[part 2 of 2: packages /ComponentTypes to /Nexteer/DataTypes]
AUTOSAR XML (schema 4.0)
package /ComponentTypes  (continued)
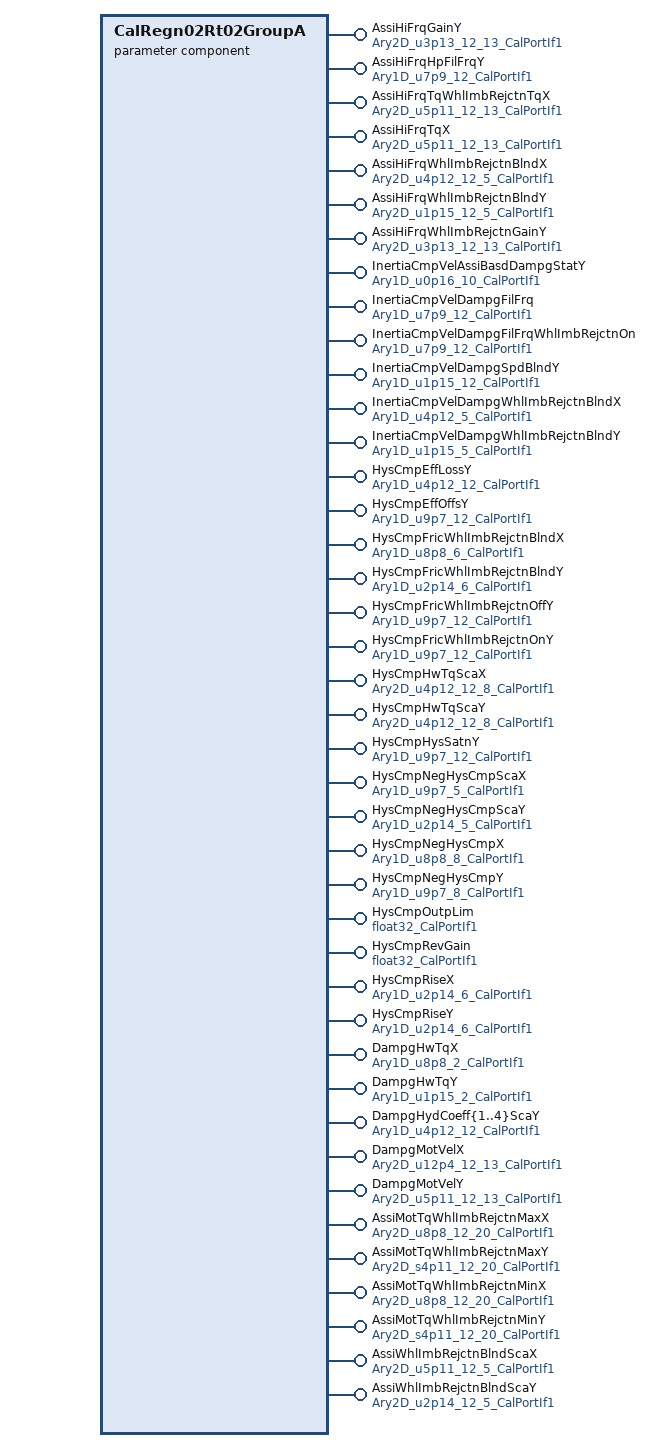
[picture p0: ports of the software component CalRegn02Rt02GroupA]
  parameter sw component type CalRegn02Rt02GroupA
    44 x provide port:
      AssiHiFrqGainY: parameter-provide-com-spec{init-value=12 x [2048, 1638, 1065, 655, 328, 82, 0, 0, 0, 0, 0, 0, 0], parameter=Ary2D_u3p13_12_13_CalPortIf1/Ary2D}, provided-interface=Ary2D_u3p13_12_13_CalPortIf1
      AssiHiFrqHpFilFrqY: parameter-provide-com-spec{init-value=12 x 4096, parameter=Ary1D_u7p9_12_CalPortIf1/Ary1D}, provided-interface=Ary1D_u7p9_12_CalPortIf1
      AssiHiFrqTqWhlImbRejctnTqX: parameter-provide-com-spec{init-value=12 x [0, 512, 1024, 1536, 2048, 2560, 3072, 4096, 8192, 12288, 15360, 15872, 16384], parameter=Ary2D_u5p11_12_13_CalPortIf1/Ary2D}, provided-interface=Ary2D_u5p11_12_13_CalPortIf1
      AssiHiFrqTqX: parameter-provide-com-spec{init-value=12 x [0, 512, 1024, 1536, 2048, 2560, 3072, 4096, 8192, 12288, 15360, 15872, 16384], parameter=Ary2D_u5p11_12_13_CalPortIf1/Ary2D}, provided-interface=Ary2D_u5p11_12_13_CalPortIf1
      AssiHiFrqWhlImbRejctnBlndX: parameter-provide-com-spec{init-value=12 x [0, 1024, 2048, 3072, 4506], parameter=Ary2D_u4p12_12_5_CalPortIf1/Ary2D}, provided-interface=Ary2D_u4p12_12_5_CalPortIf1
      AssiHiFrqWhlImbRejctnBlndY: parameter-provide-com-spec{init-value=12 x 5 x 0, parameter=Ary2D_u1p15_12_5_CalPortIf1/Ary2D}, provided-interface=Ary2D_u1p15_12_5_CalPortIf1
      AssiHiFrqWhlImbRejctnGainY: parameter-provide-com-spec{init-value=12 x [2048, 1638, 1065, 655, 328, 82, 0, 0, 0, 0, 0, 0, 0], parameter=Ary2D_u3p13_12_13_CalPortIf1/Ary2D}, provided-interface=Ary2D_u3p13_12_13_CalPortIf1
      InertiaCmpVelAssiBasdDampgStatY: parameter-provide-com-spec{init-value=10 x 0, parameter=Ary1D_u0p16_10_CalPortIf1/Ary1D}, provided-interface=Ary1D_u0p16_10_CalPortIf1
      InertiaCmpVelDampgFilFrq: parameter-provide-com-spec{init-value=12 x 8192, parameter=Ary1D_u7p9_12_CalPortIf1/Ary1D}, provided-interface=Ary1D_u7p9_12_CalPortIf1
      InertiaCmpVelDampgFilFrqWhlImbRejctnOn: parameter-provide-com-spec{init-value=12 x 8192, parameter=Ary1D_u7p9_12_CalPortIf1/Ary1D}, provided-interface=Ary1D_u7p9_12_CalPortIf1
      InertiaCmpVelDampgSpdBlndY: parameter-provide-com-spec{init-value=[32768, 32768, 9830, 6554, 3277, 0, 0, 0, 0, 0, 0, 0], parameter=Ary1D_u1p15_12_CalPortIf1/Ary1D}, provided-interface=Ary1D_u1p15_12_CalPortIf1
      InertiaCmpVelDampgWhlImbRejctnBlndX: parameter-provide-com-spec{init-value=[208, 432, 640, 848, 1056], parameter=Ary1D_u4p12_5_CalPortIf1/Ary1D}, provided-interface=Ary1D_u4p12_5_CalPortIf1
      InertiaCmpVelDampgWhlImbRejctnBlndY: parameter-provide-com-spec{init-value=5 x 0, parameter=Ary1D_u1p15_5_CalPortIf1/Ary1D}, provided-interface=Ary1D_u1p15_5_CalPortIf1
      HysCmpEffLossY: parameter-provide-com-spec{init-value=12 x 0, parameter=Ary1D_u4p12_12_CalPortIf1/Ary1D}, provided-interface=Ary1D_u4p12_12_CalPortIf1
      HysCmpEffOffsY: parameter-provide-com-spec{init-value=12 x 0, parameter=Ary1D_u9p7_12_CalPortIf1/Ary1D}, provided-interface=Ary1D_u9p7_12_CalPortIf1
      HysCmpFricWhlImbRejctnBlndX: parameter-provide-com-spec{init-value=[0, 51, 102, 154, 205, 256], parameter=Ary1D_u8p8_6_CalPortIf1/Ary1D}, provided-interface=Ary1D_u8p8_6_CalPortIf1
      HysCmpFricWhlImbRejctnBlndY: parameter-provide-com-spec{init-value=6 x 0, parameter=Ary1D_u2p14_6_CalPortIf1/Ary1D}, provided-interface=Ary1D_u2p14_6_CalPortIf1
      HysCmpFricWhlImbRejctnOffY: parameter-provide-com-spec{init-value=12 x 0, parameter=Ary1D_u9p7_12_CalPortIf1/Ary1D}, provided-interface=Ary1D_u9p7_12_CalPortIf1
      HysCmpFricWhlImbRejctnOnY: parameter-provide-com-spec{init-value=12 x 0, parameter=Ary1D_u9p7_12_CalPortIf1/Ary1D}, provided-interface=Ary1D_u9p7_12_CalPortIf1
      HysCmpHwTqScaX: parameter-provide-com-spec{init-value=12 x [0, 815, 1634, 2458, 4096, 5730, 8192, 40960], parameter=Ary2D_u4p12_12_8_CalPortIf1/Ary2D}, provided-interface=Ary2D_u4p12_12_8_CalPortIf1
      HysCmpHwTqScaY: parameter-provide-com-spec{init-value=12 x 8 x 4096, parameter=Ary2D_u4p12_12_8_CalPortIf1/Ary2D}, provided-interface=Ary2D_u4p12_12_8_CalPortIf1
      HysCmpHysSatnY: parameter-provide-com-spec{init-value=12 x 1280, parameter=Ary1D_u9p7_12_CalPortIf1/Ary1D}, provided-interface=Ary1D_u9p7_12_CalPortIf1
      HysCmpNegHysCmpScaX: parameter-provide-com-spec{init-value=[0, 128, 256, 384, 512], parameter=Ary1D_u9p7_5_CalPortIf1/Ary1D}, provided-interface=Ary1D_u9p7_5_CalPortIf1
      HysCmpNegHysCmpScaY: parameter-provide-com-spec{init-value=5 x 16384, parameter=Ary1D_u2p14_5_CalPortIf1/Ary1D}, provided-interface=Ary1D_u2p14_5_CalPortIf1
      HysCmpNegHysCmpX: parameter-provide-com-spec{init-value=[0, 26, 51, 102, 154, 205, 230, 256], parameter=Ary1D_u8p8_8_CalPortIf1/Ary1D}, provided-interface=Ary1D_u8p8_8_CalPortIf1
      HysCmpNegHysCmpY: parameter-provide-com-spec{init-value=8 x 0, parameter=Ary1D_u9p7_8_CalPortIf1/Ary1D}, provided-interface=Ary1D_u9p7_8_CalPortIf1
      HysCmpOutpLim: parameter-provide-com-spec{init-value=16, parameter=float32_CalPortIf1/Val}, provided-interface=float32_CalPortIf1
      HysCmpRevGain: parameter-provide-com-spec{init-value=6, parameter=float32_CalPortIf1/Val}, provided-interface=float32_CalPortIf1
      HysCmpRiseX: parameter-provide-com-spec{init-value=[0, 1556, 2097, 2540, 2982, 3277], parameter=Ary1D_u2p14_6_CalPortIf1/Ary1D}, provided-interface=Ary1D_u2p14_6_CalPortIf1
      HysCmpRiseY: parameter-provide-com-spec{init-value=[0, 9863, 12878, 14811, 15974, 16384], parameter=Ary1D_u2p14_6_CalPortIf1/Ary1D}, provided-interface=Ary1D_u2p14_6_CalPortIf1
      DampgHwTqX: parameter-provide-com-spec{init-value=[2048, 2560], parameter=Ary1D_u8p8_2_CalPortIf1/Ary1D}, provided-interface=Ary1D_u8p8_2_CalPortIf1
      DampgHwTqY: parameter-provide-com-spec{init-value=[32768, 0], parameter=Ary1D_u1p15_2_CalPortIf1/Ary1D}, provided-interface=Ary1D_u1p15_2_CalPortIf1
      DampgHydCoeff{1..4}ScaY: parameter-provide-com-spec{init-value=12 x 4096, parameter=Ary1D_u4p12_12_CalPortIf1/Ary1D}, provided-interface=Ary1D_u4p12_12_CalPortIf1
      DampgMotVelX: parameter-provide-com-spec{init-value=12 x [33, 163, 342, 554, 872, 1260, 1663, 2032, 2401, 2771, 3509, 4433, 5910], parameter=Ary2D_u12p4_12_13_CalPortIf1/Ary2D}, provided-interface=Ary2D_u12p4_12_13_CalPortIf1
      DampgMotVelY: parameter-provide-com-spec{init-value=[13 x 0, 13 x 0, 13 x 0, 13 x 0, [0, 0, 1, 3, 7, 14, 24, 36, 50, 67, 107, 171, 304], [1, 5, 13, 25, 48, 85, 132, 184, 245, 313, 476, 725, 1233], [5, 25, 54, 93, 159, 251, 360, 472, 597, 733, 1041, 1493, 2370], [10, 49, 106, 180, 301, 467, 659, 855, 1068, 1299, 1814, 2559, 3981], [10, 49, 106, 180, 301, 467, 659, 855, 1068, 1299, 1814, 2559, 3981], [10, 49, 106, 180, 301, 467, 659, 855, 1068, 1299, 1814, 2559, 3981], [10, 49, 106, 180, 301, 467, 659, 855, 1068, 1299, 1814, 2559, 3981], [10, 49, 106, 180, 301, 467, 659, 855, 1068, 1299, 1814, 2559, 3981]], parameter=Ary2D_u5p11_12_13_CalPortIf1/Ary2D}, provided-interface=Ary2D_u5p11_12_13_CalPortIf1
      AssiMotTqWhlImbRejctnMaxX: parameter-provide-com-spec{init-value=[[0, 26, 53, 63, 74, 86, 98, 110, 123, 134, 146, 159, 170, 182, 194, 205, 256, 372, 1220, 2560], [0, 26, 78, 101, 123, 148, 171, 196, 220, 243, 267, 290, 315, 339, 362, 435, 563, 719, 1624, 2560], [0, 51, 80, 113, 145, 176, 205, 238, 266, 297, 330, 360, 391, 422, 452, 538, 717, 916, 2216, 2560], [0, 51, 80, 110, 146, 173, 205, 237, 266, 299, 330, 360, 392, 423, 452, 484, 640, 917, 947, 2560], [0, 51, 80, 111, 143, 177, 207, 238, 267, 300, 330, 359, 392, 422, 453, 483, 640, 819, 947, 2560], [0, 51, 79, 111, 139, 174, 206, 236, 267, 300, 334, 366, 396, 428, 460, 494, 640, 819, 972, 2560], [0, 51, 80, 106, 142, 175, 205, 239, 270, 300, 332, 366, 398, 429, 462, 494, 640, 819, 972, 2560], [0, 51, 100, 130, 163, 194, 229, 261, 291, 324, 355, 388, 420, 451, 483, 515, 640, 819, 998, 2560], [0, 51, 100, 130, 164, 196, 232, 260, 297, 327, 360, 396, 430, 462, 493, 527, 666, 819, 1024, 2560], [0, 51, 100, 130, 164, 196, 232, 260, 297, 327, 360, 396, 430, 462, 493, 527, 666, 819, 1024, 2560], [0, 51, 100, 130, 164, 196, 232, 260, 297, 327, 360, 396, 430, 462, 493, 527, 666, 819, 1024, 2560], [0, 51, 100, 130, 164, 196, 232, 260, 297, 327, 360, 396, 430, 462, 493, 527, 666, 819, 1024, 2560]], parameter=Ary2D_u8p8_12_20_CalPortIf1/Ary2D}, provided-interface=Ary2D_u8p8_12_20_CalPortIf1
      AssiMotTqWhlImbRejctnMaxY: parameter-provide-com-spec{init-value=[[0, 0, 48, 72, 104, 144, 192, 248, 312, 376, 448, 536, 616, 712, 816, 920, 1536, 3128, 17904, 17904], [0, 0, 64, 104, 152, 216, 288, 376, 472, 576, 696, 824, 968, 1120, 1280, 1761, 3072, 5120, 17904, 17904], [0, 0, 32, 80, 136, 200, 272, 360, 448, 552, 672, 792, 928, 1072, 1224, 1741, 3031, 4728, 17904, 17904], [0, 0, 32, 72, 128, 176, 240, 312, 384, 472, 560, 656, 760, 872, 984, 1112, 2048, 3568, 3792, 15632], [0, 0, 32, 72, 120, 176, 232, 296, 360, 440, 520, 600, 696, 792, 896, 1000, 1741, 2642, 3320, 13472], [0, 0, 32, 72, 112, 168, 224, 280, 344, 416, 496, 576, 656, 744, 840, 944, 1536, 2314, 3024, 11632], [0, 0, 32, 64, 112, 160, 208, 264, 320, 376, 440, 512, 584, 656, 736, 816, 1311, 1925, 2456, 9120], [0, 0, 48, 80, 120, 160, 208, 256, 304, 360, 416, 480, 544, 608, 680, 752, 1126, 1720, 2264, 8272], [0, 0, 48, 80, 120, 160, 208, 248, 304, 352, 408, 472, 536, 600, 664, 736, 1024, 1536, 2160, 7528], [0, 0, 48, 80, 120, 160, 208, 248, 304, 352, 408, 472, 536, 600, 664, 736, 1024, 1536, 2160, 7528], [0, 0, 48, 80, 120, 160, 208, 248, 304, 352, 408, 472, 536, 600, 664, 736, 1024, 1536, 2160, 7528], [0, 0, 48, 80, 120, 160, 208, 248, 304, 352, 408, 472, 536, 600, 664, 736, 1024, 1536, 2160, 7528]], parameter=Ary2D_s4p11_12_20_CalPortIf1/Ary2D}, provided-interface=Ary2D_s4p11_12_20_CalPortIf1
      AssiMotTqWhlImbRejctnMinX: parameter-provide-com-spec{init-value=[[0, 26, 53, 63, 74, 86, 98, 110, 123, 134, 146, 159, 170, 182, 194, 205, 256, 372, 1220, 2560], [0, 26, 78, 101, 123, 148, 171, 196, 220, 243, 267, 290, 315, 339, 362, 435, 563, 719, 1624, 2560], [0, 51, 80, 113, 145, 176, 205, 238, 266, 297, 330, 360, 391, 422, 452, 538, 717, 916, 2216, 2560], [0, 51, 80, 110, 146, 173, 205, 237, 266, 299, 330, 360, 392, 423, 452, 484, 640, 917, 947, 2560], [0, 51, 80, 111, 143, 177, 207, 238, 267, 300, 330, 359, 392, 422, 453, 483, 640, 819, 947, 2560], [0, 51, 79, 111, 139, 174, 206, 236, 267, 300, 334, 366, 396, 428, 460, 494, 640, 819, 972, 2560], [0, 51, 80, 106, 142, 175, 205, 239, 270, 300, 332, 366, 398, 429, 462, 494, 640, 819, 972, 2560], [0, 51, 100, 130, 163, 194, 229, 261, 291, 324, 355, 388, 420, 451, 483, 515, 640, 819, 998, 2560], [0, 51, 100, 130, 164, 196, 232, 260, 297, 327, 360, 396, 430, 462, 493, 527, 666, 819, 1024, 2560], [0, 51, 100, 130, 164, 196, 232, 260, 297, 327, 360, 396, 430, 462, 493, 527, 666, 819, 1024, 2560], [0, 51, 100, 130, 164, 196, 232, 260, 297, 327, 360, 396, 430, 462, 493, 527, 666, 819, 1024, 2560], [0, 51, 100, 130, 164, 196, 232, 260, 297, 327, 360, 396, 430, 462, 493, 527, 666, 819, 1024, 2560]], parameter=Ary2D_u8p8_12_20_CalPortIf1/Ary2D}, provided-interface=Ary2D_u8p8_12_20_CalPortIf1
      AssiMotTqWhlImbRejctnMinY: parameter-provide-com-spec{init-value=[[0, 0, 48, 72, 104, 144, 192, 248, 312, 376, 448, 536, 616, 712, 816, 920, 1536, 3128, 17904, 17904], [0, 0, 64, 104, 152, 216, 288, 376, 472, 576, 696, 824, 968, 1120, 1280, 1761, 3072, 5120, 17904, 17904], [0, 0, 32, 80, 136, 200, 272, 360, 448, 552, 672, 792, 928, 1072, 1224, 1741, 3031, 4728, 17904, 17904], [0, 0, 32, 72, 128, 176, 240, 312, 384, 472, 560, 656, 760, 872, 984, 1112, 2048, 3568, 3792, 15632], [0, 0, 32, 72, 120, 176, 232, 296, 360, 440, 520, 600, 696, 792, 896, 1000, 1741, 2642, 3320, 13472], [0, 0, 32, 72, 112, 168, 224, 280, 344, 416, 496, 576, 656, 744, 840, 944, 1536, 2314, 3024, 11632], [0, 0, 32, 64, 112, 160, 208, 264, 320, 376, 440, 512, 584, 656, 736, 816, 1311, 1925, 2456, 9120], [0, 0, 48, 80, 120, 160, 208, 256, 304, 360, 416, 480, 544, 608, 680, 752, 1126, 1720, 2264, 8272], [0, 0, 48, 80, 120, 160, 208, 248, 304, 352, 408, 472, 536, 600, 664, 736, 1024, 1536, 2160, 7528], [0, 0, 48, 80, 120, 160, 208, 248, 304, 352, 408, 472, 536, 600, 664, 736, 1024, 1536, 2160, 7528], [0, 0, 48, 80, 120, 160, 208, 248, 304, 352, 408, 472, 536, 600, 664, 736, 1024, 1536, 2160, 7528], [0, 0, 48, 80, 120, 160, 208, 248, 304, 352, 408, 472, 536, 600, 664, 736, 1024, 1536, 2160, 7528]], parameter=Ary2D_s4p11_12_20_CalPortIf1/Ary2D}, provided-interface=Ary2D_s4p11_12_20_CalPortIf1
      AssiWhlImbRejctnBlndScaX: parameter-provide-com-spec{init-value=12 x [0, 512, 1024, 1536, 2253], parameter=Ary2D_u5p11_12_5_CalPortIf1/Ary2D}, provided-interface=Ary2D_u5p11_12_5_CalPortIf1
      AssiWhlImbRejctnBlndScaY: parameter-provide-com-spec{init-value=12 x 5 x 0, parameter=Ary2D_u2p14_12_5_CalPortIf1/Ary2D}, provided-interface=Ary2D_u2p14_12_5_CalPortIf1
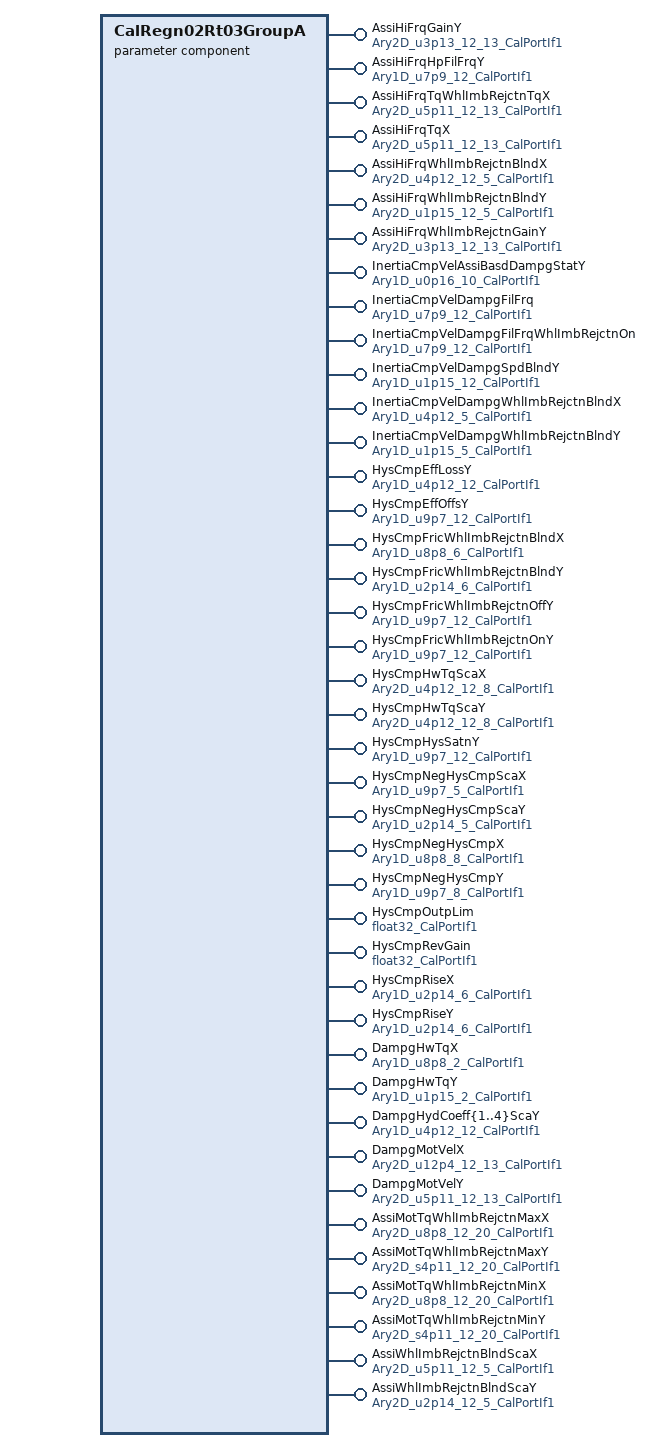
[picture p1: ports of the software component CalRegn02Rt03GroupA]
  parameter sw component type CalRegn02Rt03GroupA
    44 x provide port:
      AssiHiFrqGainY: parameter-provide-com-spec{init-value=12 x [2048, 1638, 1065, 655, 328, 82, 0, 0, 0, 0, 0, 0, 0], parameter=Ary2D_u3p13_12_13_CalPortIf1/Ary2D}, provided-interface=Ary2D_u3p13_12_13_CalPortIf1
      AssiHiFrqHpFilFrqY: parameter-provide-com-spec{init-value=12 x 4096, parameter=Ary1D_u7p9_12_CalPortIf1/Ary1D}, provided-interface=Ary1D_u7p9_12_CalPortIf1
      AssiHiFrqTqWhlImbRejctnTqX: parameter-provide-com-spec{init-value=12 x [0, 512, 1024, 1536, 2048, 2560, 3072, 4096, 8192, 12288, 15360, 15872, 16384], parameter=Ary2D_u5p11_12_13_CalPortIf1/Ary2D}, provided-interface=Ary2D_u5p11_12_13_CalPortIf1
      AssiHiFrqTqX: parameter-provide-com-spec{init-value=12 x [0, 512, 1024, 1536, 2048, 2560, 3072, 4096, 8192, 12288, 15360, 15872, 16384], parameter=Ary2D_u5p11_12_13_CalPortIf1/Ary2D}, provided-interface=Ary2D_u5p11_12_13_CalPortIf1
      AssiHiFrqWhlImbRejctnBlndX: parameter-provide-com-spec{init-value=12 x [0, 1024, 2048, 3072, 4506], parameter=Ary2D_u4p12_12_5_CalPortIf1/Ary2D}, provided-interface=Ary2D_u4p12_12_5_CalPortIf1
      AssiHiFrqWhlImbRejctnBlndY: parameter-provide-com-spec{init-value=12 x 5 x 0, parameter=Ary2D_u1p15_12_5_CalPortIf1/Ary2D}, provided-interface=Ary2D_u1p15_12_5_CalPortIf1
      AssiHiFrqWhlImbRejctnGainY: parameter-provide-com-spec{init-value=12 x [2048, 1638, 1065, 655, 328, 82, 0, 0, 0, 0, 0, 0, 0], parameter=Ary2D_u3p13_12_13_CalPortIf1/Ary2D}, provided-interface=Ary2D_u3p13_12_13_CalPortIf1
      InertiaCmpVelAssiBasdDampgStatY: parameter-provide-com-spec{init-value=10 x 0, parameter=Ary1D_u0p16_10_CalPortIf1/Ary1D}, provided-interface=Ary1D_u0p16_10_CalPortIf1
      InertiaCmpVelDampgFilFrq: parameter-provide-com-spec{init-value=12 x 8192, parameter=Ary1D_u7p9_12_CalPortIf1/Ary1D}, provided-interface=Ary1D_u7p9_12_CalPortIf1
      InertiaCmpVelDampgFilFrqWhlImbRejctnOn: parameter-provide-com-spec{init-value=12 x 8192, parameter=Ary1D_u7p9_12_CalPortIf1/Ary1D}, provided-interface=Ary1D_u7p9_12_CalPortIf1
      InertiaCmpVelDampgSpdBlndY: parameter-provide-com-spec{init-value=[32768, 32768, 9830, 6554, 3277, 0, 0, 0, 0, 0, 0, 0], parameter=Ary1D_u1p15_12_CalPortIf1/Ary1D}, provided-interface=Ary1D_u1p15_12_CalPortIf1
      InertiaCmpVelDampgWhlImbRejctnBlndX: parameter-provide-com-spec{init-value=[208, 432, 640, 848, 1056], parameter=Ary1D_u4p12_5_CalPortIf1/Ary1D}, provided-interface=Ary1D_u4p12_5_CalPortIf1
      InertiaCmpVelDampgWhlImbRejctnBlndY: parameter-provide-com-spec{init-value=5 x 0, parameter=Ary1D_u1p15_5_CalPortIf1/Ary1D}, provided-interface=Ary1D_u1p15_5_CalPortIf1
      HysCmpEffLossY: parameter-provide-com-spec{init-value=12 x 0, parameter=Ary1D_u4p12_12_CalPortIf1/Ary1D}, provided-interface=Ary1D_u4p12_12_CalPortIf1
      HysCmpEffOffsY: parameter-provide-com-spec{init-value=12 x 0, parameter=Ary1D_u9p7_12_CalPortIf1/Ary1D}, provided-interface=Ary1D_u9p7_12_CalPortIf1
      HysCmpFricWhlImbRejctnBlndX: parameter-provide-com-spec{init-value=[0, 51, 102, 154, 205, 256], parameter=Ary1D_u8p8_6_CalPortIf1/Ary1D}, provided-interface=Ary1D_u8p8_6_CalPortIf1
      HysCmpFricWhlImbRejctnBlndY: parameter-provide-com-spec{init-value=6 x 0, parameter=Ary1D_u2p14_6_CalPortIf1/Ary1D}, provided-interface=Ary1D_u2p14_6_CalPortIf1
      HysCmpFricWhlImbRejctnOffY: parameter-provide-com-spec{init-value=12 x 0, parameter=Ary1D_u9p7_12_CalPortIf1/Ary1D}, provided-interface=Ary1D_u9p7_12_CalPortIf1
      HysCmpFricWhlImbRejctnOnY: parameter-provide-com-spec{init-value=12 x 0, parameter=Ary1D_u9p7_12_CalPortIf1/Ary1D}, provided-interface=Ary1D_u9p7_12_CalPortIf1
      HysCmpHwTqScaX: parameter-provide-com-spec{init-value=12 x [0, 815, 1634, 2458, 4096, 5730, 8192, 40960], parameter=Ary2D_u4p12_12_8_CalPortIf1/Ary2D}, provided-interface=Ary2D_u4p12_12_8_CalPortIf1
      HysCmpHwTqScaY: parameter-provide-com-spec{init-value=12 x 8 x 4096, parameter=Ary2D_u4p12_12_8_CalPortIf1/Ary2D}, provided-interface=Ary2D_u4p12_12_8_CalPortIf1
      HysCmpHysSatnY: parameter-provide-com-spec{init-value=12 x 1280, parameter=Ary1D_u9p7_12_CalPortIf1/Ary1D}, provided-interface=Ary1D_u9p7_12_CalPortIf1
      HysCmpNegHysCmpScaX: parameter-provide-com-spec{init-value=[0, 128, 256, 384, 512], parameter=Ary1D_u9p7_5_CalPortIf1/Ary1D}, provided-interface=Ary1D_u9p7_5_CalPortIf1
      HysCmpNegHysCmpScaY: parameter-provide-com-spec{init-value=5 x 16384, parameter=Ary1D_u2p14_5_CalPortIf1/Ary1D}, provided-interface=Ary1D_u2p14_5_CalPortIf1
      HysCmpNegHysCmpX: parameter-provide-com-spec{init-value=[0, 26, 51, 102, 154, 205, 230, 256], parameter=Ary1D_u8p8_8_CalPortIf1/Ary1D}, provided-interface=Ary1D_u8p8_8_CalPortIf1
      HysCmpNegHysCmpY: parameter-provide-com-spec{init-value=8 x 0, parameter=Ary1D_u9p7_8_CalPortIf1/Ary1D}, provided-interface=Ary1D_u9p7_8_CalPortIf1
      HysCmpOutpLim: parameter-provide-com-spec{init-value=16, parameter=float32_CalPortIf1/Val}, provided-interface=float32_CalPortIf1
      HysCmpRevGain: parameter-provide-com-spec{init-value=6, parameter=float32_CalPortIf1/Val}, provided-interface=float32_CalPortIf1
      HysCmpRiseX: parameter-provide-com-spec{init-value=[0, 1556, 2097, 2540, 2982, 3277], parameter=Ary1D_u2p14_6_CalPortIf1/Ary1D}, provided-interface=Ary1D_u2p14_6_CalPortIf1
      HysCmpRiseY: parameter-provide-com-spec{init-value=[0, 9863, 12878, 14811, 15974, 16384], parameter=Ary1D_u2p14_6_CalPortIf1/Ary1D}, provided-interface=Ary1D_u2p14_6_CalPortIf1
      DampgHwTqX: parameter-provide-com-spec{init-value=[2048, 2560], parameter=Ary1D_u8p8_2_CalPortIf1/Ary1D}, provided-interface=Ary1D_u8p8_2_CalPortIf1
      DampgHwTqY: parameter-provide-com-spec{init-value=[32768, 0], parameter=Ary1D_u1p15_2_CalPortIf1/Ary1D}, provided-interface=Ary1D_u1p15_2_CalPortIf1
      DampgHydCoeff{1..4}ScaY: parameter-provide-com-spec{init-value=12 x 4096, parameter=Ary1D_u4p12_12_CalPortIf1/Ary1D}, provided-interface=Ary1D_u4p12_12_CalPortIf1
      DampgMotVelX: parameter-provide-com-spec{init-value=12 x [33, 163, 342, 554, 872, 1260, 1663, 2032, 2401, 2771, 3509, 4433, 5910], parameter=Ary2D_u12p4_12_13_CalPortIf1/Ary2D}, provided-interface=Ary2D_u12p4_12_13_CalPortIf1
      DampgMotVelY: parameter-provide-com-spec{init-value=[13 x 0, 13 x 0, 13 x 0, 13 x 0, [0, 0, 1, 3, 7, 14, 24, 36, 50, 67, 107, 171, 304], [1, 5, 13, 25, 48, 85, 132, 184, 245, 313, 476, 725, 1233], [5, 25, 54, 93, 159, 251, 360, 472, 597, 733, 1041, 1493, 2370], [10, 49, 106, 180, 301, 467, 659, 855, 1068, 1299, 1814, 2559, 3981], [10, 49, 106, 180, 301, 467, 659, 855, 1068, 1299, 1814, 2559, 3981], [10, 49, 106, 180, 301, 467, 659, 855, 1068, 1299, 1814, 2559, 3981], [10, 49, 106, 180, 301, 467, 659, 855, 1068, 1299, 1814, 2559, 3981], [10, 49, 106, 180, 301, 467, 659, 855, 1068, 1299, 1814, 2559, 3981]], parameter=Ary2D_u5p11_12_13_CalPortIf1/Ary2D}, provided-interface=Ary2D_u5p11_12_13_CalPortIf1
      AssiMotTqWhlImbRejctnMaxX: parameter-provide-com-spec{init-value=[[0, 26, 53, 63, 74, 86, 98, 110, 123, 134, 146, 159, 170, 182, 194, 205, 256, 372, 1220, 2560], [0, 26, 78, 101, 123, 148, 171, 196, 220, 243, 267, 290, 315, 339, 362, 435, 563, 719, 1624, 2560], [0, 51, 80, 113, 145, 176, 205, 238, 266, 297, 330, 360, 391, 422, 452, 538, 717, 916, 2216, 2560], [0, 51, 80, 110, 146, 173, 205, 237, 266, 299, 330, 360, 392, 423, 452, 484, 640, 917, 947, 2560], [0, 51, 80, 111, 143, 177, 207, 238, 267, 300, 330, 359, 392, 422, 453, 483, 640, 819, 947, 2560], [0, 51, 79, 111, 139, 174, 206, 236, 267, 300, 334, 366, 396, 428, 460, 494, 640, 819, 972, 2560], [0, 51, 80, 106, 142, 175, 205, 239, 270, 300, 332, 366, 398, 429, 462, 494, 640, 819, 972, 2560], [0, 51, 100, 130, 163, 194, 229, 261, 291, 324, 355, 388, 420, 451, 483, 515, 640, 819, 998, 2560], [0, 51, 100, 130, 164, 196, 232, 260, 297, 327, 360, 396, 430, 462, 493, 527, 666, 819, 1024, 2560], [0, 51, 100, 130, 164, 196, 232, 260, 297, 327, 360, 396, 430, 462, 493, 527, 666, 819, 1024, 2560], [0, 51, 100, 130, 164, 196, 232, 260, 297, 327, 360, 396, 430, 462, 493, 527, 666, 819, 1024, 2560], [0, 51, 100, 130, 164, 196, 232, 260, 297, 327, 360, 396, 430, 462, 493, 527, 666, 819, 1024, 2560]], parameter=Ary2D_u8p8_12_20_CalPortIf1/Ary2D}, provided-interface=Ary2D_u8p8_12_20_CalPortIf1
      AssiMotTqWhlImbRejctnMaxY: parameter-provide-com-spec{init-value=[[0, 0, 48, 72, 104, 144, 192, 248, 312, 376, 448, 536, 616, 712, 816, 920, 1536, 3128, 17904, 17904], [0, 0, 64, 104, 152, 216, 288, 376, 472, 576, 696, 824, 968, 1120, 1280, 1761, 3072, 5120, 17904, 17904], [0, 0, 32, 80, 136, 200, 272, 360, 448, 552, 672, 792, 928, 1072, 1224, 1741, 3031, 4728, 17904, 17904], [0, 0, 32, 72, 128, 176, 240, 312, 384, 472, 560, 656, 760, 872, 984, 1112, 2048, 3568, 3792, 15632], [0, 0, 32, 72, 120, 176, 232, 296, 360, 440, 520, 600, 696, 792, 896, 1000, 1741, 2642, 3320, 13472], [0, 0, 32, 72, 112, 168, 224, 280, 344, 416, 496, 576, 656, 744, 840, 944, 1536, 2314, 3024, 11632], [0, 0, 32, 64, 112, 160, 208, 264, 320, 376, 440, 512, 584, 656, 736, 816, 1311, 1925, 2456, 9120], [0, 0, 48, 80, 120, 160, 208, 256, 304, 360, 416, 480, 544, 608, 680, 752, 1126, 1720, 2264, 8272], [0, 0, 48, 80, 120, 160, 208, 248, 304, 352, 408, 472, 536, 600, 664, 736, 1024, 1536, 2160, 7528], [0, 0, 48, 80, 120, 160, 208, 248, 304, 352, 408, 472, 536, 600, 664, 736, 1024, 1536, 2160, 7528], [0, 0, 48, 80, 120, 160, 208, 248, 304, 352, 408, 472, 536, 600, 664, 736, 1024, 1536, 2160, 7528], [0, 0, 48, 80, 120, 160, 208, 248, 304, 352, 408, 472, 536, 600, 664, 736, 1024, 1536, 2160, 7528]], parameter=Ary2D_s4p11_12_20_CalPortIf1/Ary2D}, provided-interface=Ary2D_s4p11_12_20_CalPortIf1
      AssiMotTqWhlImbRejctnMinX: parameter-provide-com-spec{init-value=[[0, 26, 53, 63, 74, 86, 98, 110, 123, 134, 146, 159, 170, 182, 194, 205, 256, 372, 1220, 2560], [0, 26, 78, 101, 123, 148, 171, 196, 220, 243, 267, 290, 315, 339, 362, 435, 563, 719, 1624, 2560], [0, 51, 80, 113, 145, 176, 205, 238, 266, 297, 330, 360, 391, 422, 452, 538, 717, 916, 2216, 2560], [0, 51, 80, 110, 146, 173, 205, 237, 266, 299, 330, 360, 392, 423, 452, 484, 640, 917, 947, 2560], [0, 51, 80, 111, 143, 177, 207, 238, 267, 300, 330, 359, 392, 422, 453, 483, 640, 819, 947, 2560], [0, 51, 79, 111, 139, 174, 206, 236, 267, 300, 334, 366, 396, 428, 460, 494, 640, 819, 972, 2560], [0, 51, 80, 106, 142, 175, 205, 239, 270, 300, 332, 366, 398, 429, 462, 494, 640, 819, 972, 2560], [0, 51, 100, 130, 163, 194, 229, 261, 291, 324, 355, 388, 420, 451, 483, 515, 640, 819, 998, 2560], [0, 51, 100, 130, 164, 196, 232, 260, 297, 327, 360, 396, 430, 462, 493, 527, 666, 819, 1024, 2560], [0, 51, 100, 130, 164, 196, 232, 260, 297, 327, 360, 396, 430, 462, 493, 527, 666, 819, 1024, 2560], [0, 51, 100, 130, 164, 196, 232, 260, 297, 327, 360, 396, 430, 462, 493, 527, 666, 819, 1024, 2560], [0, 51, 100, 130, 164, 196, 232, 260, 297, 327, 360, 396, 430, 462, 493, 527, 666, 819, 1024, 2560]], parameter=Ary2D_u8p8_12_20_CalPortIf1/Ary2D}, provided-interface=Ary2D_u8p8_12_20_CalPortIf1
      AssiMotTqWhlImbRejctnMinY: parameter-provide-com-spec{init-value=[[0, 0, 48, 72, 104, 144, 192, 248, 312, 376, 448, 536, 616, 712, 816, 920, 1536, 3128, 17904, 17904], [0, 0, 64, 104, 152, 216, 288, 376, 472, 576, 696, 824, 968, 1120, 1280, 1761, 3072, 5120, 17904, 17904], [0, 0, 32, 80, 136, 200, 272, 360, 448, 552, 672, 792, 928, 1072, 1224, 1741, 3031, 4728, 17904, 17904], [0, 0, 32, 72, 128, 176, 240, 312, 384, 472, 560, 656, 760, 872, 984, 1112, 2048, 3568, 3792, 15632], [0, 0, 32, 72, 120, 176, 232, 296, 360, 440, 520, 600, 696, 792, 896, 1000, 1741, 2642, 3320, 13472], [0, 0, 32, 72, 112, 168, 224, 280, 344, 416, 496, 576, 656, 744, 840, 944, 1536, 2314, 3024, 11632], [0, 0, 32, 64, 112, 160, 208, 264, 320, 376, 440, 512, 584, 656, 736, 816, 1311, 1925, 2456, 9120], [0, 0, 48, 80, 120, 160, 208, 256, 304, 360, 416, 480, 544, 608, 680, 752, 1126, 1720, 2264, 8272], [0, 0, 48, 80, 120, 160, 208, 248, 304, 352, 408, 472, 536, 600, 664, 736, 1024, 1536, 2160, 7528], [0, 0, 48, 80, 120, 160, 208, 248, 304, 352, 408, 472, 536, 600, 664, 736, 1024, 1536, 2160, 7528], [0, 0, 48, 80, 120, 160, 208, 248, 304, 352, 408, 472, 536, 600, 664, 736, 1024, 1536, 2160, 7528], [0, 0, 48, 80, 120, 160, 208, 248, 304, 352, 408, 472, 536, 600, 664, 736, 1024, 1536, 2160, 7528]], parameter=Ary2D_s4p11_12_20_CalPortIf1/Ary2D}, provided-interface=Ary2D_s4p11_12_20_CalPortIf1
      AssiWhlImbRejctnBlndScaX: parameter-provide-com-spec{init-value=12 x [0, 512, 1024, 1536, 2253], parameter=Ary2D_u5p11_12_5_CalPortIf1/Ary2D}, provided-interface=Ary2D_u5p11_12_5_CalPortIf1
      AssiWhlImbRejctnBlndScaY: parameter-provide-com-spec{init-value=12 x 5 x 0, parameter=Ary2D_u2p14_12_5_CalPortIf1/Ary2D}, provided-interface=Ary2D_u2p14_12_5_CalPortIf1
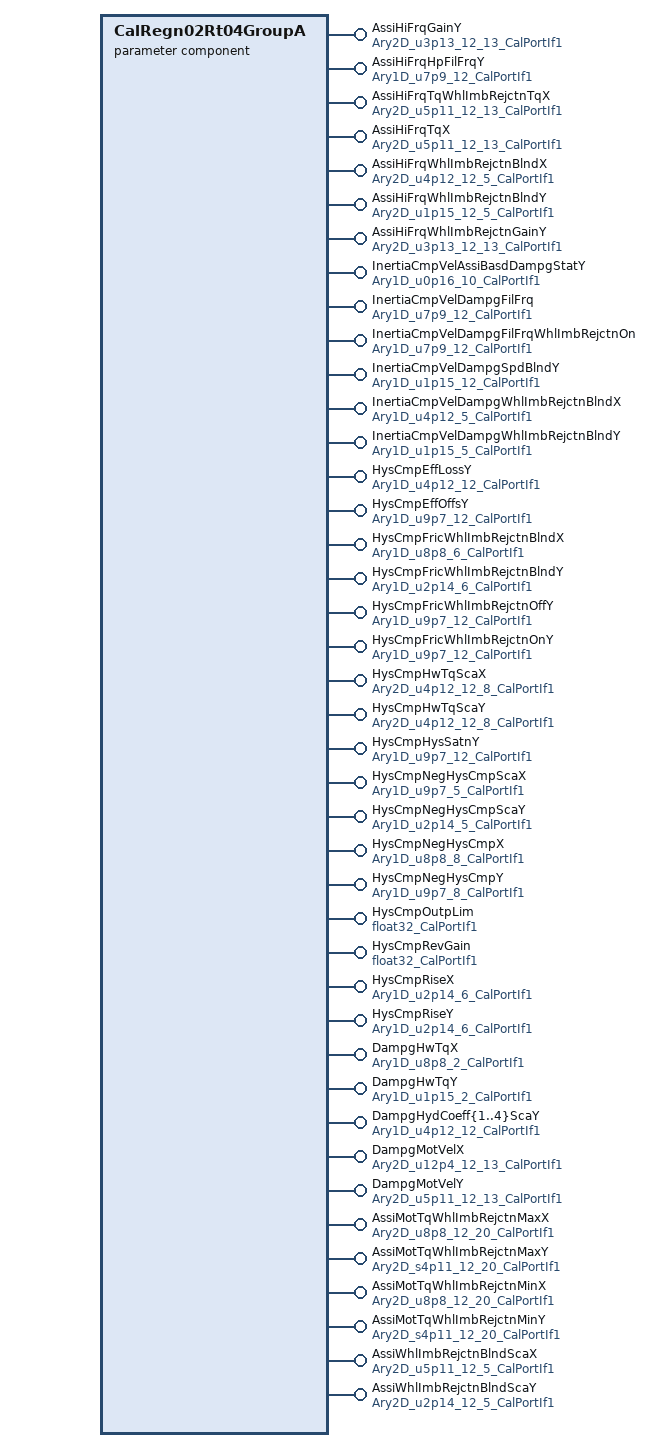
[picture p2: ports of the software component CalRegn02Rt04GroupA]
  parameter sw component type CalRegn02Rt04GroupA
    44 x provide port:
      AssiHiFrqGainY: parameter-provide-com-spec{init-value=12 x [2048, 1638, 1065, 655, 328, 82, 0, 0, 0, 0, 0, 0, 0], parameter=Ary2D_u3p13_12_13_CalPortIf1/Ary2D}, provided-interface=Ary2D_u3p13_12_13_CalPortIf1
      AssiHiFrqHpFilFrqY: parameter-provide-com-spec{init-value=12 x 4096, parameter=Ary1D_u7p9_12_CalPortIf1/Ary1D}, provided-interface=Ary1D_u7p9_12_CalPortIf1
      AssiHiFrqTqWhlImbRejctnTqX: parameter-provide-com-spec{init-value=12 x [0, 512, 1024, 1536, 2048, 2560, 3072, 4096, 8192, 12288, 15360, 15872, 16384], parameter=Ary2D_u5p11_12_13_CalPortIf1/Ary2D}, provided-interface=Ary2D_u5p11_12_13_CalPortIf1
      AssiHiFrqTqX: parameter-provide-com-spec{init-value=12 x [0, 512, 1024, 1536, 2048, 2560, 3072, 4096, 8192, 12288, 15360, 15872, 16384], parameter=Ary2D_u5p11_12_13_CalPortIf1/Ary2D}, provided-interface=Ary2D_u5p11_12_13_CalPortIf1
      AssiHiFrqWhlImbRejctnBlndX: parameter-provide-com-spec{init-value=12 x [0, 1024, 2048, 3072, 4506], parameter=Ary2D_u4p12_12_5_CalPortIf1/Ary2D}, provided-interface=Ary2D_u4p12_12_5_CalPortIf1
      AssiHiFrqWhlImbRejctnBlndY: parameter-provide-com-spec{init-value=12 x 5 x 0, parameter=Ary2D_u1p15_12_5_CalPortIf1/Ary2D}, provided-interface=Ary2D_u1p15_12_5_CalPortIf1
      AssiHiFrqWhlImbRejctnGainY: parameter-provide-com-spec{init-value=12 x [2048, 1638, 1065, 655, 328, 82, 0, 0, 0, 0, 0, 0, 0], parameter=Ary2D_u3p13_12_13_CalPortIf1/Ary2D}, provided-interface=Ary2D_u3p13_12_13_CalPortIf1
      InertiaCmpVelAssiBasdDampgStatY: parameter-provide-com-spec{init-value=10 x 0, parameter=Ary1D_u0p16_10_CalPortIf1/Ary1D}, provided-interface=Ary1D_u0p16_10_CalPortIf1
      InertiaCmpVelDampgFilFrq: parameter-provide-com-spec{init-value=12 x 8192, parameter=Ary1D_u7p9_12_CalPortIf1/Ary1D}, provided-interface=Ary1D_u7p9_12_CalPortIf1
      InertiaCmpVelDampgFilFrqWhlImbRejctnOn: parameter-provide-com-spec{init-value=12 x 8192, parameter=Ary1D_u7p9_12_CalPortIf1/Ary1D}, provided-interface=Ary1D_u7p9_12_CalPortIf1
      InertiaCmpVelDampgSpdBlndY: parameter-provide-com-spec{init-value=[32768, 32768, 9830, 6554, 3277, 0, 0, 0, 0, 0, 0, 0], parameter=Ary1D_u1p15_12_CalPortIf1/Ary1D}, provided-interface=Ary1D_u1p15_12_CalPortIf1
      InertiaCmpVelDampgWhlImbRejctnBlndX: parameter-provide-com-spec{init-value=[208, 432, 640, 848, 1056], parameter=Ary1D_u4p12_5_CalPortIf1/Ary1D}, provided-interface=Ary1D_u4p12_5_CalPortIf1
      InertiaCmpVelDampgWhlImbRejctnBlndY: parameter-provide-com-spec{init-value=5 x 0, parameter=Ary1D_u1p15_5_CalPortIf1/Ary1D}, provided-interface=Ary1D_u1p15_5_CalPortIf1
      HysCmpEffLossY: parameter-provide-com-spec{init-value=12 x 0, parameter=Ary1D_u4p12_12_CalPortIf1/Ary1D}, provided-interface=Ary1D_u4p12_12_CalPortIf1
      HysCmpEffOffsY: parameter-provide-com-spec{init-value=12 x 0, parameter=Ary1D_u9p7_12_CalPortIf1/Ary1D}, provided-interface=Ary1D_u9p7_12_CalPortIf1
      HysCmpFricWhlImbRejctnBlndX: parameter-provide-com-spec{init-value=[0, 51, 102, 154, 205, 256], parameter=Ary1D_u8p8_6_CalPortIf1/Ary1D}, provided-interface=Ary1D_u8p8_6_CalPortIf1
      HysCmpFricWhlImbRejctnBlndY: parameter-provide-com-spec{init-value=6 x 0, parameter=Ary1D_u2p14_6_CalPortIf1/Ary1D}, provided-interface=Ary1D_u2p14_6_CalPortIf1
      HysCmpFricWhlImbRejctnOffY: parameter-provide-com-spec{init-value=12 x 0, parameter=Ary1D_u9p7_12_CalPortIf1/Ary1D}, provided-interface=Ary1D_u9p7_12_CalPortIf1
      HysCmpFricWhlImbRejctnOnY: parameter-provide-com-spec{init-value=12 x 0, parameter=Ary1D_u9p7_12_CalPortIf1/Ary1D}, provided-interface=Ary1D_u9p7_12_CalPortIf1
      HysCmpHwTqScaX: parameter-provide-com-spec{init-value=12 x [0, 815, 1634, 2458, 4096, 5730, 8192, 40960], parameter=Ary2D_u4p12_12_8_CalPortIf1/Ary2D}, provided-interface=Ary2D_u4p12_12_8_CalPortIf1
      HysCmpHwTqScaY: parameter-provide-com-spec{init-value=12 x 8 x 4096, parameter=Ary2D_u4p12_12_8_CalPortIf1/Ary2D}, provided-interface=Ary2D_u4p12_12_8_CalPortIf1
      HysCmpHysSatnY: parameter-provide-com-spec{init-value=12 x 1280, parameter=Ary1D_u9p7_12_CalPortIf1/Ary1D}, provided-interface=Ary1D_u9p7_12_CalPortIf1
      HysCmpNegHysCmpScaX: parameter-provide-com-spec{init-value=[0, 128, 256, 384, 512], parameter=Ary1D_u9p7_5_CalPortIf1/Ary1D}, provided-interface=Ary1D_u9p7_5_CalPortIf1
      HysCmpNegHysCmpScaY: parameter-provide-com-spec{init-value=5 x 16384, parameter=Ary1D_u2p14_5_CalPortIf1/Ary1D}, provided-interface=Ary1D_u2p14_5_CalPortIf1
      HysCmpNegHysCmpX: parameter-provide-com-spec{init-value=[0, 26, 51, 102, 154, 205, 230, 256], parameter=Ary1D_u8p8_8_CalPortIf1/Ary1D}, provided-interface=Ary1D_u8p8_8_CalPortIf1
      HysCmpNegHysCmpY: parameter-provide-com-spec{init-value=8 x 0, parameter=Ary1D_u9p7_8_CalPortIf1/Ary1D}, provided-interface=Ary1D_u9p7_8_CalPortIf1
      HysCmpOutpLim: parameter-provide-com-spec{init-value=16, parameter=float32_CalPortIf1/Val}, provided-interface=float32_CalPortIf1
      HysCmpRevGain: parameter-provide-com-spec{init-value=6, parameter=float32_CalPortIf1/Val}, provided-interface=float32_CalPortIf1
      HysCmpRiseX: parameter-provide-com-spec{init-value=[0, 1556, 2097, 2540, 2982, 3277], parameter=Ary1D_u2p14_6_CalPortIf1/Ary1D}, provided-interface=Ary1D_u2p14_6_CalPortIf1
      HysCmpRiseY: parameter-provide-com-spec{init-value=[0, 9863, 12878, 14811, 15974, 16384], parameter=Ary1D_u2p14_6_CalPortIf1/Ary1D}, provided-interface=Ary1D_u2p14_6_CalPortIf1
      DampgHwTqX: parameter-provide-com-spec{init-value=[2048, 2560], parameter=Ary1D_u8p8_2_CalPortIf1/Ary1D}, provided-interface=Ary1D_u8p8_2_CalPortIf1
      DampgHwTqY: parameter-provide-com-spec{init-value=[32768, 0], parameter=Ary1D_u1p15_2_CalPortIf1/Ary1D}, provided-interface=Ary1D_u1p15_2_CalPortIf1
      DampgHydCoeff{1..4}ScaY: parameter-provide-com-spec{init-value=12 x 4096, parameter=Ary1D_u4p12_12_CalPortIf1/Ary1D}, provided-interface=Ary1D_u4p12_12_CalPortIf1
      DampgMotVelX: parameter-provide-com-spec{init-value=12 x [33, 163, 342, 554, 872, 1260, 1663, 2032, 2401, 2771, 3509, 4433, 5910], parameter=Ary2D_u12p4_12_13_CalPortIf1/Ary2D}, provided-interface=Ary2D_u12p4_12_13_CalPortIf1
      DampgMotVelY: parameter-provide-com-spec{init-value=[13 x 0, 13 x 0, 13 x 0, 13 x 0, [0, 0, 1, 3, 7, 14, 24, 36, 50, 67, 107, 171, 304], [1, 5, 13, 25, 48, 85, 132, 184, 245, 313, 476, 725, 1233], [5, 25, 54, 93, 159, 251, 360, 472, 597, 733, 1041, 1493, 2370], [10, 49, 106, 180, 301, 467, 659, 855, 1068, 1299, 1814, 2559, 3981], [10, 49, 106, 180, 301, 467, 659, 855, 1068, 1299, 1814, 2559, 3981], [10, 49, 106, 180, 301, 467, 659, 855, 1068, 1299, 1814, 2559, 3981], [10, 49, 106, 180, 301, 467, 659, 855, 1068, 1299, 1814, 2559, 3981], [10, 49, 106, 180, 301, 467, 659, 855, 1068, 1299, 1814, 2559, 3981]], parameter=Ary2D_u5p11_12_13_CalPortIf1/Ary2D}, provided-interface=Ary2D_u5p11_12_13_CalPortIf1
      AssiMotTqWhlImbRejctnMaxX: parameter-provide-com-spec{init-value=[[0, 26, 53, 63, 74, 86, 98, 110, 123, 134, 146, 159, 170, 182, 194, 205, 256, 372, 1220, 2560], [0, 26, 78, 101, 123, 148, 171, 196, 220, 243, 267, 290, 315, 339, 362, 435, 563, 719, 1624, 2560], [0, 51, 80, 113, 145, 176, 205, 238, 266, 297, 330, 360, 391, 422, 452, 538, 717, 916, 2216, 2560], [0, 51, 80, 110, 146, 173, 205, 237, 266, 299, 330, 360, 392, 423, 452, 484, 640, 917, 947, 2560], [0, 51, 80, 111, 143, 177, 207, 238, 267, 300, 330, 359, 392, 422, 453, 483, 640, 819, 947, 2560], [0, 51, 79, 111, 139, 174, 206, 236, 267, 300, 334, 366, 396, 428, 460, 494, 640, 819, 972, 2560], [0, 51, 80, 106, 142, 175, 205, 239, 270, 300, 332, 366, 398, 429, 462, 494, 640, 819, 972, 2560], [0, 51, 100, 130, 163, 194, 229, 261, 291, 324, 355, 388, 420, 451, 483, 515, 640, 819, 998, 2560], [0, 51, 100, 130, 164, 196, 232, 260, 297, 327, 360, 396, 430, 462, 493, 527, 666, 819, 1024, 2560], [0, 51, 100, 130, 164, 196, 232, 260, 297, 327, 360, 396, 430, 462, 493, 527, 666, 819, 1024, 2560], [0, 51, 100, 130, 164, 196, 232, 260, 297, 327, 360, 396, 430, 462, 493, 527, 666, 819, 1024, 2560], [0, 51, 100, 130, 164, 196, 232, 260, 297, 327, 360, 396, 430, 462, 493, 527, 666, 819, 1024, 2560]], parameter=Ary2D_u8p8_12_20_CalPortIf1/Ary2D}, provided-interface=Ary2D_u8p8_12_20_CalPortIf1
      AssiMotTqWhlImbRejctnMaxY: parameter-provide-com-spec{init-value=[[0, 0, 48, 72, 104, 144, 192, 248, 312, 376, 448, 536, 616, 712, 816, 920, 1536, 3128, 17904, 17904], [0, 0, 64, 104, 152, 216, 288, 376, 472, 576, 696, 824, 968, 1120, 1280, 1761, 3072, 5120, 17904, 17904], [0, 0, 32, 80, 136, 200, 272, 360, 448, 552, 672, 792, 928, 1072, 1224, 1741, 3031, 4728, 17904, 17904], [0, 0, 32, 72, 128, 176, 240, 312, 384, 472, 560, 656, 760, 872, 984, 1112, 2048, 3568, 3792, 15632], [0, 0, 32, 72, 120, 176, 232, 296, 360, 440, 520, 600, 696, 792, 896, 1000, 1741, 2642, 3320, 13472], [0, 0, 32, 72, 112, 168, 224, 280, 344, 416, 496, 576, 656, 744, 840, 944, 1536, 2314, 3024, 11632], [0, 0, 32, 64, 112, 160, 208, 264, 320, 376, 440, 512, 584, 656, 736, 816, 1311, 1925, 2456, 9120], [0, 0, 48, 80, 120, 160, 208, 256, 304, 360, 416, 480, 544, 608, 680, 752, 1126, 1720, 2264, 8272], [0, 0, 48, 80, 120, 160, 208, 248, 304, 352, 408, 472, 536, 600, 664, 736, 1024, 1536, 2160, 7528], [0, 0, 48, 80, 120, 160, 208, 248, 304, 352, 408, 472, 536, 600, 664, 736, 1024, 1536, 2160, 7528], [0, 0, 48, 80, 120, 160, 208, 248, 304, 352, 408, 472, 536, 600, 664, 736, 1024, 1536, 2160, 7528], [0, 0, 48, 80, 120, 160, 208, 248, 304, 352, 408, 472, 536, 600, 664, 736, 1024, 1536, 2160, 7528]], parameter=Ary2D_s4p11_12_20_CalPortIf1/Ary2D}, provided-interface=Ary2D_s4p11_12_20_CalPortIf1
      AssiMotTqWhlImbRejctnMinX: parameter-provide-com-spec{init-value=[[0, 26, 53, 63, 74, 86, 98, 110, 123, 134, 146, 159, 170, 182, 194, 205, 256, 372, 1220, 2560], [0, 26, 78, 101, 123, 148, 171, 196, 220, 243, 267, 290, 315, 339, 362, 435, 563, 719, 1624, 2560], [0, 51, 80, 113, 145, 176, 205, 238, 266, 297, 330, 360, 391, 422, 452, 538, 717, 916, 2216, 2560], [0, 51, 80, 110, 146, 173, 205, 237, 266, 299, 330, 360, 392, 423, 452, 484, 640, 917, 947, 2560], [0, 51, 80, 111, 143, 177, 207, 238, 267, 300, 330, 359, 392, 422, 453, 483, 640, 819, 947, 2560], [0, 51, 79, 111, 139, 174, 206, 236, 267, 300, 334, 366, 396, 428, 460, 494, 640, 819, 972, 2560], [0, 51, 80, 106, 142, 175, 205, 239, 270, 300, 332, 366, 398, 429, 462, 494, 640, 819, 972, 2560], [0, 51, 100, 130, 163, 194, 229, 261, 291, 324, 355, 388, 420, 451, 483, 515, 640, 819, 998, 2560], [0, 51, 100, 130, 164, 196, 232, 260, 297, 327, 360, 396, 430, 462, 493, 527, 666, 819, 1024, 2560], [0, 51, 100, 130, 164, 196, 232, 260, 297, 327, 360, 396, 430, 462, 493, 527, 666, 819, 1024, 2560], [0, 51, 100, 130, 164, 196, 232, 260, 297, 327, 360, 396, 430, 462, 493, 527, 666, 819, 1024, 2560], [0, 51, 100, 130, 164, 196, 232, 260, 297, 327, 360, 396, 430, 462, 493, 527, 666, 819, 1024, 2560]], parameter=Ary2D_u8p8_12_20_CalPortIf1/Ary2D}, provided-interface=Ary2D_u8p8_12_20_CalPortIf1
      AssiMotTqWhlImbRejctnMinY: parameter-provide-com-spec{init-value=[[0, 0, 48, 72, 104, 144, 192, 248, 312, 376, 448, 536, 616, 712, 816, 920, 1536, 3128, 17904, 17904], [0, 0, 64, 104, 152, 216, 288, 376, 472, 576, 696, 824, 968, 1120, 1280, 1761, 3072, 5120, 17904, 17904], [0, 0, 32, 80, 136, 200, 272, 360, 448, 552, 672, 792, 928, 1072, 1224, 1741, 3031, 4728, 17904, 17904], [0, 0, 32, 72, 128, 176, 240, 312, 384, 472, 560, 656, 760, 872, 984, 1112, 2048, 3568, 3792, 15632], [0, 0, 32, 72, 120, 176, 232, 296, 360, 440, 520, 600, 696, 792, 896, 1000, 1741, 2642, 3320, 13472], [0, 0, 32, 72, 112, 168, 224, 280, 344, 416, 496, 576, 656, 744, 840, 944, 1536, 2314, 3024, 11632], [0, 0, 32, 64, 112, 160, 208, 264, 320, 376, 440, 512, 584, 656, 736, 816, 1311, 1925, 2456, 9120], [0, 0, 48, 80, 120, 160, 208, 256, 304, 360, 416, 480, 544, 608, 680, 752, 1126, 1720, 2264, 8272], [0, 0, 48, 80, 120, 160, 208, 248, 304, 352, 408, 472, 536, 600, 664, 736, 1024, 1536, 2160, 7528], [0, 0, 48, 80, 120, 160, 208, 248, 304, 352, 408, 472, 536, 600, 664, 736, 1024, 1536, 2160, 7528], [0, 0, 48, 80, 120, 160, 208, 248, 304, 352, 408, 472, 536, 600, 664, 736, 1024, 1536, 2160, 7528], [0, 0, 48, 80, 120, 160, 208, 248, 304, 352, 408, 472, 536, 600, 664, 736, 1024, 1536, 2160, 7528]], parameter=Ary2D_s4p11_12_20_CalPortIf1/Ary2D}, provided-interface=Ary2D_s4p11_12_20_CalPortIf1
      AssiWhlImbRejctnBlndScaX: parameter-provide-com-spec{init-value=12 x [0, 512, 1024, 1536, 2253], parameter=Ary2D_u5p11_12_5_CalPortIf1/Ary2D}, provided-interface=Ary2D_u5p11_12_5_CalPortIf1
      AssiWhlImbRejctnBlndScaY: parameter-provide-com-spec{init-value=12 x 5 x 0, parameter=Ary2D_u2p14_12_5_CalPortIf1/Ary2D}, provided-interface=Ary2D_u2p14_12_5_CalPortIf1
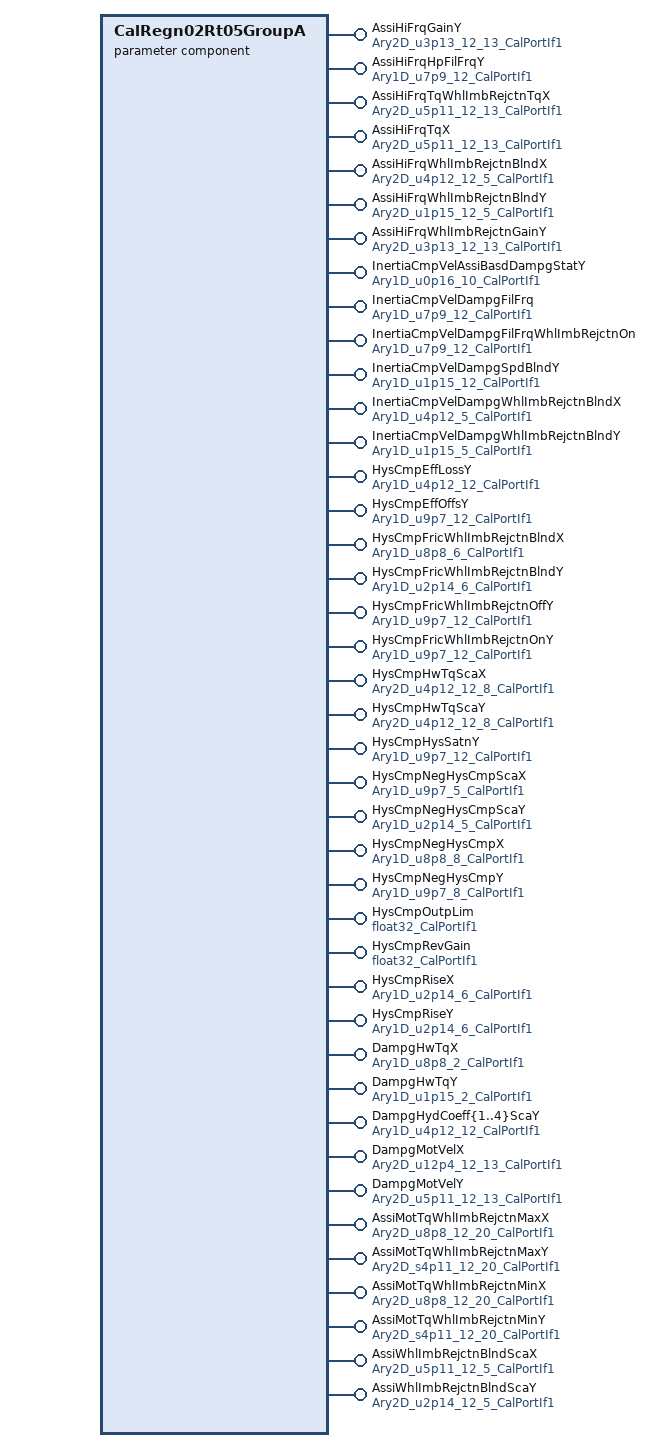
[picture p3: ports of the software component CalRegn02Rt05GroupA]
  parameter sw component type CalRegn02Rt05GroupA
    44 x provide port:
      AssiHiFrqGainY: parameter-provide-com-spec{init-value=12 x [2048, 1638, 1065, 655, 328, 82, 0, 0, 0, 0, 0, 0, 0], parameter=Ary2D_u3p13_12_13_CalPortIf1/Ary2D}, provided-interface=Ary2D_u3p13_12_13_CalPortIf1
      AssiHiFrqHpFilFrqY: parameter-provide-com-spec{init-value=12 x 4096, parameter=Ary1D_u7p9_12_CalPortIf1/Ary1D}, provided-interface=Ary1D_u7p9_12_CalPortIf1
      AssiHiFrqTqWhlImbRejctnTqX: parameter-provide-com-spec{init-value=12 x [0, 512, 1024, 1536, 2048, 2560, 3072, 4096, 8192, 12288, 15360, 15872, 16384], parameter=Ary2D_u5p11_12_13_CalPortIf1/Ary2D}, provided-interface=Ary2D_u5p11_12_13_CalPortIf1
      AssiHiFrqTqX: parameter-provide-com-spec{init-value=12 x [0, 512, 1024, 1536, 2048, 2560, 3072, 4096, 8192, 12288, 15360, 15872, 16384], parameter=Ary2D_u5p11_12_13_CalPortIf1/Ary2D}, provided-interface=Ary2D_u5p11_12_13_CalPortIf1
      AssiHiFrqWhlImbRejctnBlndX: parameter-provide-com-spec{init-value=12 x [0, 1024, 2048, 3072, 4506], parameter=Ary2D_u4p12_12_5_CalPortIf1/Ary2D}, provided-interface=Ary2D_u4p12_12_5_CalPortIf1
      AssiHiFrqWhlImbRejctnBlndY: parameter-provide-com-spec{init-value=12 x 5 x 0, parameter=Ary2D_u1p15_12_5_CalPortIf1/Ary2D}, provided-interface=Ary2D_u1p15_12_5_CalPortIf1
      AssiHiFrqWhlImbRejctnGainY: parameter-provide-com-spec{init-value=12 x [2048, 1638, 1065, 655, 328, 82, 0, 0, 0, 0, 0, 0, 0], parameter=Ary2D_u3p13_12_13_CalPortIf1/Ary2D}, provided-interface=Ary2D_u3p13_12_13_CalPortIf1
      InertiaCmpVelAssiBasdDampgStatY: parameter-provide-com-spec{init-value=10 x 0, parameter=Ary1D_u0p16_10_CalPortIf1/Ary1D}, provided-interface=Ary1D_u0p16_10_CalPortIf1
      InertiaCmpVelDampgFilFrq: parameter-provide-com-spec{init-value=12 x 8192, parameter=Ary1D_u7p9_12_CalPortIf1/Ary1D}, provided-interface=Ary1D_u7p9_12_CalPortIf1
      InertiaCmpVelDampgFilFrqWhlImbRejctnOn: parameter-provide-com-spec{init-value=12 x 8192, parameter=Ary1D_u7p9_12_CalPortIf1/Ary1D}, provided-interface=Ary1D_u7p9_12_CalPortIf1
      InertiaCmpVelDampgSpdBlndY: parameter-provide-com-spec{init-value=[32768, 32768, 9830, 6554, 3277, 0, 0, 0, 0, 0, 0, 0], parameter=Ary1D_u1p15_12_CalPortIf1/Ary1D}, provided-interface=Ary1D_u1p15_12_CalPortIf1
      InertiaCmpVelDampgWhlImbRejctnBlndX: parameter-provide-com-spec{init-value=[208, 432, 640, 848, 1056], parameter=Ary1D_u4p12_5_CalPortIf1/Ary1D}, provided-interface=Ary1D_u4p12_5_CalPortIf1
      InertiaCmpVelDampgWhlImbRejctnBlndY: parameter-provide-com-spec{init-value=5 x 0, parameter=Ary1D_u1p15_5_CalPortIf1/Ary1D}, provided-interface=Ary1D_u1p15_5_CalPortIf1
      HysCmpEffLossY: parameter-provide-com-spec{init-value=12 x 0, parameter=Ary1D_u4p12_12_CalPortIf1/Ary1D}, provided-interface=Ary1D_u4p12_12_CalPortIf1
      HysCmpEffOffsY: parameter-provide-com-spec{init-value=12 x 0, parameter=Ary1D_u9p7_12_CalPortIf1/Ary1D}, provided-interface=Ary1D_u9p7_12_CalPortIf1
      HysCmpFricWhlImbRejctnBlndX: parameter-provide-com-spec{init-value=[0, 51, 102, 154, 205, 256], parameter=Ary1D_u8p8_6_CalPortIf1/Ary1D}, provided-interface=Ary1D_u8p8_6_CalPortIf1
      HysCmpFricWhlImbRejctnBlndY: parameter-provide-com-spec{init-value=6 x 0, parameter=Ary1D_u2p14_6_CalPortIf1/Ary1D}, provided-interface=Ary1D_u2p14_6_CalPortIf1
      HysCmpFricWhlImbRejctnOffY: parameter-provide-com-spec{init-value=12 x 0, parameter=Ary1D_u9p7_12_CalPortIf1/Ary1D}, provided-interface=Ary1D_u9p7_12_CalPortIf1
      HysCmpFricWhlImbRejctnOnY: parameter-provide-com-spec{init-value=12 x 0, parameter=Ary1D_u9p7_12_CalPortIf1/Ary1D}, provided-interface=Ary1D_u9p7_12_CalPortIf1
      HysCmpHwTqScaX: parameter-provide-com-spec{init-value=12 x [0, 815, 1634, 2458, 4096, 5730, 8192, 40960], parameter=Ary2D_u4p12_12_8_CalPortIf1/Ary2D}, provided-interface=Ary2D_u4p12_12_8_CalPortIf1
      HysCmpHwTqScaY: parameter-provide-com-spec{init-value=12 x 8 x 4096, parameter=Ary2D_u4p12_12_8_CalPortIf1/Ary2D}, provided-interface=Ary2D_u4p12_12_8_CalPortIf1
      HysCmpHysSatnY: parameter-provide-com-spec{init-value=12 x 1280, parameter=Ary1D_u9p7_12_CalPortIf1/Ary1D}, provided-interface=Ary1D_u9p7_12_CalPortIf1
      HysCmpNegHysCmpScaX: parameter-provide-com-spec{init-value=[0, 128, 256, 384, 512], parameter=Ary1D_u9p7_5_CalPortIf1/Ary1D}, provided-interface=Ary1D_u9p7_5_CalPortIf1
      HysCmpNegHysCmpScaY: parameter-provide-com-spec{init-value=5 x 16384, parameter=Ary1D_u2p14_5_CalPortIf1/Ary1D}, provided-interface=Ary1D_u2p14_5_CalPortIf1
      HysCmpNegHysCmpX: parameter-provide-com-spec{init-value=[0, 26, 51, 102, 154, 205, 230, 256], parameter=Ary1D_u8p8_8_CalPortIf1/Ary1D}, provided-interface=Ary1D_u8p8_8_CalPortIf1
      HysCmpNegHysCmpY: parameter-provide-com-spec{init-value=8 x 0, parameter=Ary1D_u9p7_8_CalPortIf1/Ary1D}, provided-interface=Ary1D_u9p7_8_CalPortIf1
      HysCmpOutpLim: parameter-provide-com-spec{init-value=16, parameter=float32_CalPortIf1/Val}, provided-interface=float32_CalPortIf1
      HysCmpRevGain: parameter-provide-com-spec{init-value=6, parameter=float32_CalPortIf1/Val}, provided-interface=float32_CalPortIf1
      HysCmpRiseX: parameter-provide-com-spec{init-value=[0, 1556, 2097, 2540, 2982, 3277], parameter=Ary1D_u2p14_6_CalPortIf1/Ary1D}, provided-interface=Ary1D_u2p14_6_CalPortIf1
      HysCmpRiseY: parameter-provide-com-spec{init-value=[0, 9863, 12878, 14811, 15974, 16384], parameter=Ary1D_u2p14_6_CalPortIf1/Ary1D}, provided-interface=Ary1D_u2p14_6_CalPortIf1
      DampgHwTqX: parameter-provide-com-spec{init-value=[2048, 2560], parameter=Ary1D_u8p8_2_CalPortIf1/Ary1D}, provided-interface=Ary1D_u8p8_2_CalPortIf1
      DampgHwTqY: parameter-provide-com-spec{init-value=[32768, 0], parameter=Ary1D_u1p15_2_CalPortIf1/Ary1D}, provided-interface=Ary1D_u1p15_2_CalPortIf1
      DampgHydCoeff{1..4}ScaY: parameter-provide-com-spec{init-value=12 x 4096, parameter=Ary1D_u4p12_12_CalPortIf1/Ary1D}, provided-interface=Ary1D_u4p12_12_CalPortIf1
      DampgMotVelX: parameter-provide-com-spec{init-value=12 x [33, 163, 342, 554, 872, 1260, 1663, 2032, 2401, 2771, 3509, 4433, 5910], parameter=Ary2D_u12p4_12_13_CalPortIf1/Ary2D}, provided-interface=Ary2D_u12p4_12_13_CalPortIf1
      DampgMotVelY: parameter-provide-com-spec{init-value=[13 x 0, 13 x 0, 13 x 0, 13 x 0, [0, 0, 1, 3, 7, 14, 24, 36, 50, 67, 107, 171, 304], [1, 5, 13, 25, 48, 85, 132, 184, 245, 313, 476, 725, 1233], [5, 25, 54, 93, 159, 251, 360, 472, 597, 733, 1041, 1493, 2370], [10, 49, 106, 180, 301, 467, 659, 855, 1068, 1299, 1814, 2559, 3981], [10, 49, 106, 180, 301, 467, 659, 855, 1068, 1299, 1814, 2559, 3981], [10, 49, 106, 180, 301, 467, 659, 855, 1068, 1299, 1814, 2559, 3981], [10, 49, 106, 180, 301, 467, 659, 855, 1068, 1299, 1814, 2559, 3981], [10, 49, 106, 180, 301, 467, 659, 855, 1068, 1299, 1814, 2559, 3981]], parameter=Ary2D_u5p11_12_13_CalPortIf1/Ary2D}, provided-interface=Ary2D_u5p11_12_13_CalPortIf1
      AssiMotTqWhlImbRejctnMaxX: parameter-provide-com-spec{init-value=[[0, 26, 53, 63, 74, 86, 98, 110, 123, 134, 146, 159, 170, 182, 194, 205, 256, 372, 1220, 2560], [0, 26, 78, 101, 123, 148, 171, 196, 220, 243, 267, 290, 315, 339, 362, 435, 563, 719, 1624, 2560], [0, 51, 80, 113, 145, 176, 205, 238, 266, 297, 330, 360, 391, 422, 452, 538, 717, 916, 2216, 2560], [0, 51, 80, 110, 146, 173, 205, 237, 266, 299, 330, 360, 392, 423, 452, 484, 640, 917, 947, 2560], [0, 51, 80, 111, 143, 177, 207, 238, 267, 300, 330, 359, 392, 422, 453, 483, 640, 819, 947, 2560], [0, 51, 79, 111, 139, 174, 206, 236, 267, 300, 334, 366, 396, 428, 460, 494, 640, 819, 972, 2560], [0, 51, 80, 106, 142, 175, 205, 239, 270, 300, 332, 366, 398, 429, 462, 494, 640, 819, 972, 2560], [0, 51, 100, 130, 163, 194, 229, 261, 291, 324, 355, 388, 420, 451, 483, 515, 640, 819, 998, 2560], [0, 51, 100, 130, 164, 196, 232, 260, 297, 327, 360, 396, 430, 462, 493, 527, 666, 819, 1024, 2560], [0, 51, 100, 130, 164, 196, 232, 260, 297, 327, 360, 396, 430, 462, 493, 527, 666, 819, 1024, 2560], [0, 51, 100, 130, 164, 196, 232, 260, 297, 327, 360, 396, 430, 462, 493, 527, 666, 819, 1024, 2560], [0, 51, 100, 130, 164, 196, 232, 260, 297, 327, 360, 396, 430, 462, 493, 527, 666, 819, 1024, 2560]], parameter=Ary2D_u8p8_12_20_CalPortIf1/Ary2D}, provided-interface=Ary2D_u8p8_12_20_CalPortIf1
      AssiMotTqWhlImbRejctnMaxY: parameter-provide-com-spec{init-value=[[0, 0, 48, 72, 104, 144, 192, 248, 312, 376, 448, 536, 616, 712, 816, 920, 1536, 3128, 17904, 17904], [0, 0, 64, 104, 152, 216, 288, 376, 472, 576, 696, 824, 968, 1120, 1280, 1761, 3072, 5120, 17904, 17904], [0, 0, 32, 80, 136, 200, 272, 360, 448, 552, 672, 792, 928, 1072, 1224, 1741, 3031, 4728, 17904, 17904], [0, 0, 32, 72, 128, 176, 240, 312, 384, 472, 560, 656, 760, 872, 984, 1112, 2048, 3568, 3792, 15632], [0, 0, 32, 72, 120, 176, 232, 296, 360, 440, 520, 600, 696, 792, 896, 1000, 1741, 2642, 3320, 13472], [0, 0, 32, 72, 112, 168, 224, 280, 344, 416, 496, 576, 656, 744, 840, 944, 1536, 2314, 3024, 11632], [0, 0, 32, 64, 112, 160, 208, 264, 320, 376, 440, 512, 584, 656, 736, 816, 1311, 1925, 2456, 9120], [0, 0, 48, 80, 120, 160, 208, 256, 304, 360, 416, 480, 544, 608, 680, 752, 1126, 1720, 2264, 8272], [0, 0, 48, 80, 120, 160, 208, 248, 304, 352, 408, 472, 536, 600, 664, 736, 1024, 1536, 2160, 7528], [0, 0, 48, 80, 120, 160, 208, 248, 304, 352, 408, 472, 536, 600, 664, 736, 1024, 1536, 2160, 7528], [0, 0, 48, 80, 120, 160, 208, 248, 304, 352, 408, 472, 536, 600, 664, 736, 1024, 1536, 2160, 7528], [0, 0, 48, 80, 120, 160, 208, 248, 304, 352, 408, 472, 536, 600, 664, 736, 1024, 1536, 2160, 7528]], parameter=Ary2D_s4p11_12_20_CalPortIf1/Ary2D}, provided-interface=Ary2D_s4p11_12_20_CalPortIf1
      AssiMotTqWhlImbRejctnMinX: parameter-provide-com-spec{init-value=[[0, 26, 53, 63, 74, 86, 98, 110, 123, 134, 146, 159, 170, 182, 194, 205, 256, 372, 1220, 2560], [0, 26, 78, 101, 123, 148, 171, 196, 220, 243, 267, 290, 315, 339, 362, 435, 563, 719, 1624, 2560], [0, 51, 80, 113, 145, 176, 205, 238, 266, 297, 330, 360, 391, 422, 452, 538, 717, 916, 2216, 2560], [0, 51, 80, 110, 146, 173, 205, 237, 266, 299, 330, 360, 392, 423, 452, 484, 640, 917, 947, 2560], [0, 51, 80, 111, 143, 177, 207, 238, 267, 300, 330, 359, 392, 422, 453, 483, 640, 819, 947, 2560], [0, 51, 79, 111, 139, 174, 206, 236, 267, 300, 334, 366, 396, 428, 460, 494, 640, 819, 972, 2560], [0, 51, 80, 106, 142, 175, 205, 239, 270, 300, 332, 366, 398, 429, 462, 494, 640, 819, 972, 2560], [0, 51, 100, 130, 163, 194, 229, 261, 291, 324, 355, 388, 420, 451, 483, 515, 640, 819, 998, 2560], [0, 51, 100, 130, 164, 196, 232, 260, 297, 327, 360, 396, 430, 462, 493, 527, 666, 819, 1024, 2560], [0, 51, 100, 130, 164, 196, 232, 260, 297, 327, 360, 396, 430, 462, 493, 527, 666, 819, 1024, 2560], [0, 51, 100, 130, 164, 196, 232, 260, 297, 327, 360, 396, 430, 462, 493, 527, 666, 819, 1024, 2560], [0, 51, 100, 130, 164, 196, 232, 260, 297, 327, 360, 396, 430, 462, 493, 527, 666, 819, 1024, 2560]], parameter=Ary2D_u8p8_12_20_CalPortIf1/Ary2D}, provided-interface=Ary2D_u8p8_12_20_CalPortIf1
      AssiMotTqWhlImbRejctnMinY: parameter-provide-com-spec{init-value=[[0, 0, 48, 72, 104, 144, 192, 248, 312, 376, 448, 536, 616, 712, 816, 920, 1536, 3128, 17904, 17904], [0, 0, 64, 104, 152, 216, 288, 376, 472, 576, 696, 824, 968, 1120, 1280, 1761, 3072, 5120, 17904, 17904], [0, 0, 32, 80, 136, 200, 272, 360, 448, 552, 672, 792, 928, 1072, 1224, 1741, 3031, 4728, 17904, 17904], [0, 0, 32, 72, 128, 176, 240, 312, 384, 472, 560, 656, 760, 872, 984, 1112, 2048, 3568, 3792, 15632], [0, 0, 32, 72, 120, 176, 232, 296, 360, 440, 520, 600, 696, 792, 896, 1000, 1741, 2642, 3320, 13472], [0, 0, 32, 72, 112, 168, 224, 280, 344, 416, 496, 576, 656, 744, 840, 944, 1536, 2314, 3024, 11632], [0, 0, 32, 64, 112, 160, 208, 264, 320, 376, 440, 512, 584, 656, 736, 816, 1311, 1925, 2456, 9120], [0, 0, 48, 80, 120, 160, 208, 256, 304, 360, 416, 480, 544, 608, 680, 752, 1126, 1720, 2264, 8272], [0, 0, 48, 80, 120, 160, 208, 248, 304, 352, 408, 472, 536, 600, 664, 736, 1024, 1536, 2160, 7528], [0, 0, 48, 80, 120, 160, 208, 248, 304, 352, 408, 472, 536, 600, 664, 736, 1024, 1536, 2160, 7528], [0, 0, 48, 80, 120, 160, 208, 248, 304, 352, 408, 472, 536, 600, 664, 736, 1024, 1536, 2160, 7528], [0, 0, 48, 80, 120, 160, 208, 248, 304, 352, 408, 472, 536, 600, 664, 736, 1024, 1536, 2160, 7528]], parameter=Ary2D_s4p11_12_20_CalPortIf1/Ary2D}, provided-interface=Ary2D_s4p11_12_20_CalPortIf1
      AssiWhlImbRejctnBlndScaX: parameter-provide-com-spec{init-value=12 x [0, 512, 1024, 1536, 2253], parameter=Ary2D_u5p11_12_5_CalPortIf1/Ary2D}, provided-interface=Ary2D_u5p11_12_5_CalPortIf1
      AssiWhlImbRejctnBlndScaY: parameter-provide-com-spec{init-value=12 x 5 x 0, parameter=Ary2D_u2p14_12_5_CalPortIf1/Ary2D}, provided-interface=Ary2D_u2p14_12_5_CalPortIf1
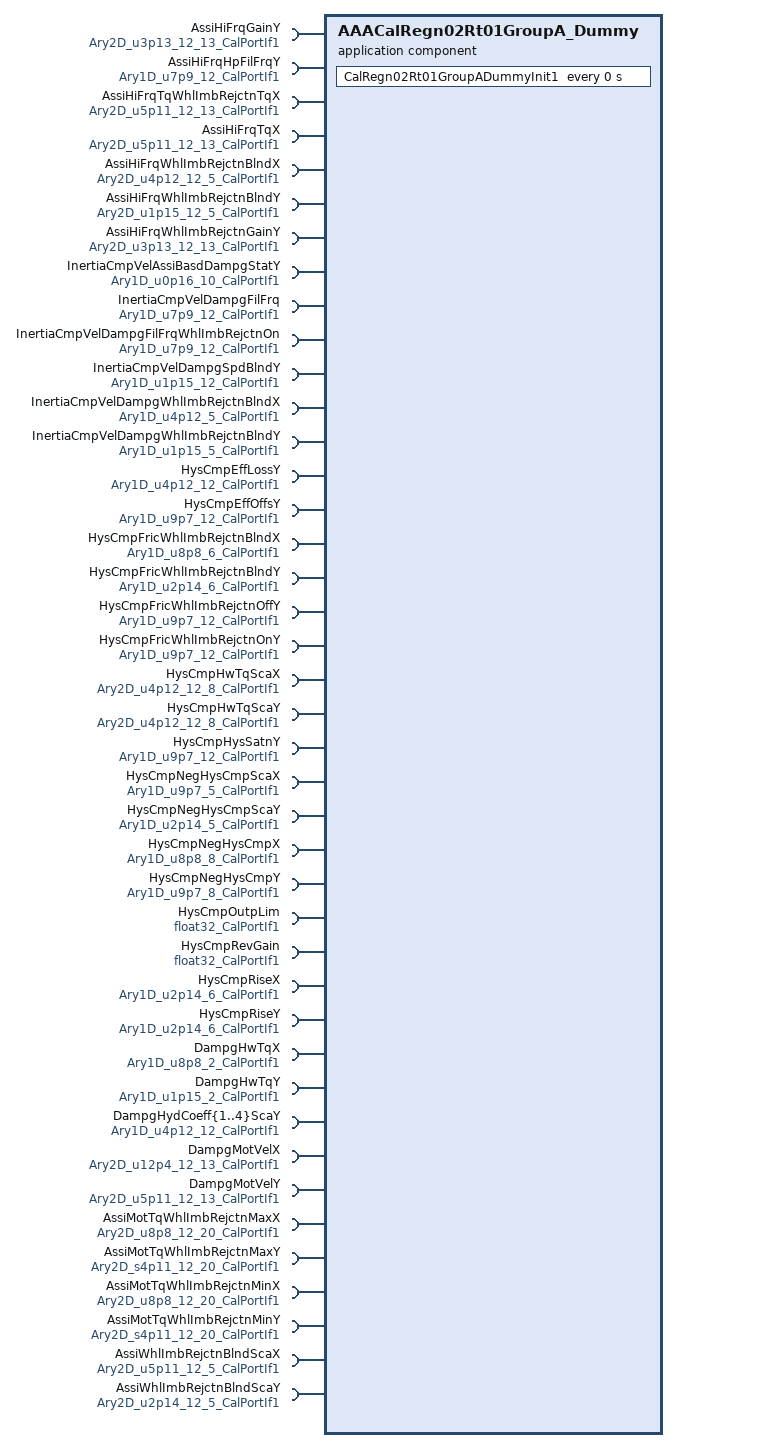
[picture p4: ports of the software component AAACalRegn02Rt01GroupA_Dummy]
  application sw component type AAACalRegn02Rt01GroupA_Dummy
    44 x require port:
      AssiHiFrqGainY: parameter-require-com-spec{init-value=12 x [2048, 1638, 1065, 655, 328, 82, 0, 0, 0, 0, 0, 0, 0], parameter=Ary2D_u3p13_12_13_CalPortIf1/Ary2D}, required-interface=Ary2D_u3p13_12_13_CalPortIf1
      AssiHiFrqHpFilFrqY: parameter-require-com-spec{init-value=12 x 4096, parameter=Ary1D_u7p9_12_CalPortIf1/Ary1D}, required-interface=Ary1D_u7p9_12_CalPortIf1
      AssiHiFrqTqWhlImbRejctnTqX: parameter-require-com-spec{init-value=12 x [0, 512, 1024, 1536, 2048, 2560, 3072, 4096, 8192, 12288, 15360, 15872, 16384], parameter=Ary2D_u5p11_12_13_CalPortIf1/Ary2D}, required-interface=Ary2D_u5p11_12_13_CalPortIf1
      AssiHiFrqTqX: parameter-require-com-spec{init-value=12 x [0, 512, 1024, 1536, 2048, 2560, 3072, 4096, 8192, 12288, 15360, 15872, 16384], parameter=Ary2D_u5p11_12_13_CalPortIf1/Ary2D}, required-interface=Ary2D_u5p11_12_13_CalPortIf1
      AssiHiFrqWhlImbRejctnBlndX: parameter-require-com-spec{init-value=12 x [0, 1024, 2048, 3072, 4506], parameter=Ary2D_u4p12_12_5_CalPortIf1/Ary2D}, required-interface=Ary2D_u4p12_12_5_CalPortIf1
      AssiHiFrqWhlImbRejctnBlndY: parameter-require-com-spec{init-value=12 x 5 x 0, parameter=Ary2D_u1p15_12_5_CalPortIf1/Ary2D}, required-interface=Ary2D_u1p15_12_5_CalPortIf1
      AssiHiFrqWhlImbRejctnGainY: parameter-require-com-spec{init-value=12 x [2048, 1638, 1065, 655, 328, 82, 0, 0, 0, 0, 0, 0, 0], parameter=Ary2D_u3p13_12_13_CalPortIf1/Ary2D}, required-interface=Ary2D_u3p13_12_13_CalPortIf1
      InertiaCmpVelAssiBasdDampgStatY: parameter-require-com-spec{init-value=10 x 0, parameter=Ary1D_u0p16_10_CalPortIf1/Ary1D}, required-interface=Ary1D_u0p16_10_CalPortIf1
      InertiaCmpVelDampgFilFrq: parameter-require-com-spec{init-value=12 x 8192, parameter=Ary1D_u7p9_12_CalPortIf1/Ary1D}, required-interface=Ary1D_u7p9_12_CalPortIf1
      InertiaCmpVelDampgFilFrqWhlImbRejctnOn: parameter-require-com-spec{init-value=12 x 8192, parameter=Ary1D_u7p9_12_CalPortIf1/Ary1D}, required-interface=Ary1D_u7p9_12_CalPortIf1
      InertiaCmpVelDampgSpdBlndY: parameter-require-com-spec{init-value=[32768, 32768, 9830, 6554, 3277, 0, 0, 0, 0, 0, 0, 0], parameter=Ary1D_u1p15_12_CalPortIf1/Ary1D}, required-interface=Ary1D_u1p15_12_CalPortIf1
      InertiaCmpVelDampgWhlImbRejctnBlndX: parameter-require-com-spec{init-value=[208, 432, 640, 848, 1056], parameter=Ary1D_u4p12_5_CalPortIf1/Ary1D}, required-interface=Ary1D_u4p12_5_CalPortIf1
      InertiaCmpVelDampgWhlImbRejctnBlndY: parameter-require-com-spec{init-value=5 x 0, parameter=Ary1D_u1p15_5_CalPortIf1/Ary1D}, required-interface=Ary1D_u1p15_5_CalPortIf1
      HysCmpEffLossY: parameter-require-com-spec{init-value=12 x 0, parameter=Ary1D_u4p12_12_CalPortIf1/Ary1D}, required-interface=Ary1D_u4p12_12_CalPortIf1
      HysCmpEffOffsY: parameter-require-com-spec{init-value=12 x 0, parameter=Ary1D_u9p7_12_CalPortIf1/Ary1D}, required-interface=Ary1D_u9p7_12_CalPortIf1
      HysCmpFricWhlImbRejctnBlndX: parameter-require-com-spec{init-value=[0, 51, 102, 154, 205, 256], parameter=Ary1D_u8p8_6_CalPortIf1/Ary1D}, required-interface=Ary1D_u8p8_6_CalPortIf1
      HysCmpFricWhlImbRejctnBlndY: parameter-require-com-spec{init-value=6 x 0, parameter=Ary1D_u2p14_6_CalPortIf1/Ary1D}, required-interface=Ary1D_u2p14_6_CalPortIf1
      HysCmpFricWhlImbRejctnOffY: parameter-require-com-spec{init-value=12 x 0, parameter=Ary1D_u9p7_12_CalPortIf1/Ary1D}, required-interface=Ary1D_u9p7_12_CalPortIf1
      HysCmpFricWhlImbRejctnOnY: parameter-require-com-spec{init-value=12 x 0, parameter=Ary1D_u9p7_12_CalPortIf1/Ary1D}, required-interface=Ary1D_u9p7_12_CalPortIf1
      HysCmpHwTqScaX: parameter-require-com-spec{init-value=12 x [0, 815, 1634, 2458, 4096, 5730, 8192, 40960], parameter=Ary2D_u4p12_12_8_CalPortIf1/Ary2D}, required-interface=Ary2D_u4p12_12_8_CalPortIf1
      HysCmpHwTqScaY: parameter-require-com-spec{init-value=12 x 8 x 4096, parameter=Ary2D_u4p12_12_8_CalPortIf1/Ary2D}, required-interface=Ary2D_u4p12_12_8_CalPortIf1
      HysCmpHysSatnY: parameter-require-com-spec{init-value=12 x 1280, parameter=Ary1D_u9p7_12_CalPortIf1/Ary1D}, required-interface=Ary1D_u9p7_12_CalPortIf1
      HysCmpNegHysCmpScaX: parameter-require-com-spec{init-value=[0, 128, 256, 384, 512], parameter=Ary1D_u9p7_5_CalPortIf1/Ary1D}, required-interface=Ary1D_u9p7_5_CalPortIf1
      HysCmpNegHysCmpScaY: parameter-require-com-spec{init-value=5 x 16384, parameter=Ary1D_u2p14_5_CalPortIf1/Ary1D}, required-interface=Ary1D_u2p14_5_CalPortIf1
      HysCmpNegHysCmpX: parameter-require-com-spec{init-value=[0, 26, 51, 102, 154, 205, 230, 256], parameter=Ary1D_u8p8_8_CalPortIf1/Ary1D}, required-interface=Ary1D_u8p8_8_CalPortIf1
      HysCmpNegHysCmpY: parameter-require-com-spec{init-value=8 x 0, parameter=Ary1D_u9p7_8_CalPortIf1/Ary1D}, required-interface=Ary1D_u9p7_8_CalPortIf1
      HysCmpOutpLim: parameter-require-com-spec{init-value=16, parameter=float32_CalPortIf1/Val}, required-interface=float32_CalPortIf1
      HysCmpRevGain: parameter-require-com-spec{init-value=6, parameter=float32_CalPortIf1/Val}, required-interface=float32_CalPortIf1
      HysCmpRiseX: parameter-require-com-spec{init-value=[0, 1556, 2097, 2540, 2982, 3277], parameter=Ary1D_u2p14_6_CalPortIf1/Ary1D}, required-interface=Ary1D_u2p14_6_CalPortIf1
      HysCmpRiseY: parameter-require-com-spec{init-value=[0, 9863, 12878, 14811, 15974, 16384], parameter=Ary1D_u2p14_6_CalPortIf1/Ary1D}, required-interface=Ary1D_u2p14_6_CalPortIf1
      DampgHwTqX: parameter-require-com-spec{init-value=[2048, 2560], parameter=Ary1D_u8p8_2_CalPortIf1/Ary1D}, required-interface=Ary1D_u8p8_2_CalPortIf1
      DampgHwTqY: parameter-require-com-spec{init-value=[32768, 0], parameter=Ary1D_u1p15_2_CalPortIf1/Ary1D}, required-interface=Ary1D_u1p15_2_CalPortIf1
      DampgHydCoeff{1..4}ScaY: parameter-require-com-spec{init-value=12 x 4096, parameter=Ary1D_u4p12_12_CalPortIf1/Ary1D}, required-interface=Ary1D_u4p12_12_CalPortIf1
      DampgMotVelX: parameter-require-com-spec{init-value=12 x [33, 163, 342, 554, 872, 1260, 1663, 2032, 2401, 2771, 3509, 4433, 5910], parameter=Ary2D_u12p4_12_13_CalPortIf1/Ary2D}, required-interface=Ary2D_u12p4_12_13_CalPortIf1
      DampgMotVelY: parameter-require-com-spec{init-value=[13 x 0, 13 x 0, 13 x 0, 13 x 0, [0, 0, 1, 3, 7, 14, 24, 36, 50, 67, 107, 171, 304], [1, 5, 13, 25, 48, 85, 132, 184, 245, 313, 476, 725, 1233], [5, 25, 54, 93, 159, 251, 360, 472, 597, 733, 1041, 1493, 2370], [10, 49, 106, 180, 301, 467, 659, 855, 1068, 1299, 1814, 2559, 3981], [10, 49, 106, 180, 301, 467, 659, 855, 1068, 1299, 1814, 2559, 3981], [10, 49, 106, 180, 301, 467, 659, 855, 1068, 1299, 1814, 2559, 3981], [10, 49, 106, 180, 301, 467, 659, 855, 1068, 1299, 1814, 2559, 3981], [10, 49, 106, 180, 301, 467, 659, 855, 1068, 1299, 1814, 2559, 3981]], parameter=Ary2D_u5p11_12_13_CalPortIf1/Ary2D}, required-interface=Ary2D_u5p11_12_13_CalPortIf1
      AssiMotTqWhlImbRejctnMaxX: parameter-require-com-spec{init-value=[[0, 26, 53, 63, 74, 86, 98, 110, 123, 134, 146, 159, 170, 182, 194, 205, 256, 372, 1220, 2560], [0, 26, 78, 101, 123, 148, 171, 196, 220, 243, 267, 290, 315, 339, 362, 435, 563, 719, 1624, 2560], [0, 51, 80, 113, 145, 176, 205, 238, 266, 297, 330, 360, 391, 422, 452, 538, 717, 916, 2216, 2560], [0, 51, 80, 110, 146, 173, 205, 237, 266, 299, 330, 360, 392, 423, 452, 484, 640, 917, 947, 2560], [0, 51, 80, 111, 143, 177, 207, 238, 267, 300, 330, 359, 392, 422, 453, 483, 640, 819, 947, 2560], [0, 51, 79, 111, 139, 174, 206, 236, 267, 300, 334, 366, 396, 428, 460, 494, 640, 819, 972, 2560], [0, 51, 80, 106, 142, 175, 205, 239, 270, 300, 332, 366, 398, 429, 462, 494, 640, 819, 972, 2560], [0, 51, 100, 130, 163, 194, 229, 261, 291, 324, 355, 388, 420, 451, 483, 515, 640, 819, 998, 2560], [0, 51, 100, 130, 164, 196, 232, 260, 297, 327, 360, 396, 430, 462, 493, 527, 666, 819, 1024, 2560], [0, 51, 100, 130, 164, 196, 232, 260, 297, 327, 360, 396, 430, 462, 493, 527, 666, 819, 1024, 2560], [0, 51, 100, 130, 164, 196, 232, 260, 297, 327, 360, 396, 430, 462, 493, 527, 666, 819, 1024, 2560], [0, 51, 100, 130, 164, 196, 232, 260, 297, 327, 360, 396, 430, 462, 493, 527, 666, 819, 1024, 2560]], parameter=Ary2D_u8p8_12_20_CalPortIf1/Ary2D}, required-interface=Ary2D_u8p8_12_20_CalPortIf1
      AssiMotTqWhlImbRejctnMaxY: parameter-require-com-spec{init-value=[[0, 0, 48, 72, 104, 144, 192, 248, 312, 376, 448, 536, 616, 712, 816, 920, 1536, 3128, 17904, 17904], [0, 0, 64, 104, 152, 216, 288, 376, 472, 576, 696, 824, 968, 1120, 1280, 1761, 3072, 5120, 17904, 17904], [0, 0, 32, 80, 136, 200, 272, 360, 448, 552, 672, 792, 928, 1072, 1224, 1741, 3031, 4728, 17904, 17904], [0, 0, 32, 72, 128, 176, 240, 312, 384, 472, 560, 656, 760, 872, 984, 1112, 2048, 3568, 3792, 15632], [0, 0, 32, 72, 120, 176, 232, 296, 360, 440, 520, 600, 696, 792, 896, 1000, 1741, 2642, 3320, 13472], [0, 0, 32, 72, 112, 168, 224, 280, 344, 416, 496, 576, 656, 744, 840, 944, 1536, 2314, 3024, 11632], [0, 0, 32, 64, 112, 160, 208, 264, 320, 376, 440, 512, 584, 656, 736, 816, 1311, 1925, 2456, 9120], [0, 0, 48, 80, 120, 160, 208, 256, 304, 360, 416, 480, 544, 608, 680, 752, 1126, 1720, 2264, 8272], [0, 0, 48, 80, 120, 160, 208, 248, 304, 352, 408, 472, 536, 600, 664, 736, 1024, 1536, 2160, 7528], [0, 0, 48, 80, 120, 160, 208, 248, 304, 352, 408, 472, 536, 600, 664, 736, 1024, 1536, 2160, 7528], [0, 0, 48, 80, 120, 160, 208, 248, 304, 352, 408, 472, 536, 600, 664, 736, 1024, 1536, 2160, 7528], [0, 0, 48, 80, 120, 160, 208, 248, 304, 352, 408, 472, 536, 600, 664, 736, 1024, 1536, 2160, 7528]], parameter=Ary2D_s4p11_12_20_CalPortIf1/Ary2D}, required-interface=Ary2D_s4p11_12_20_CalPortIf1
      AssiMotTqWhlImbRejctnMinX: parameter-require-com-spec{init-value=[[0, 26, 53, 63, 74, 86, 98, 110, 123, 134, 146, 159, 170, 182, 194, 205, 256, 372, 1220, 2560], [0, 26, 78, 101, 123, 148, 171, 196, 220, 243, 267, 290, 315, 339, 362, 435, 563, 719, 1624, 2560], [0, 51, 80, 113, 145, 176, 205, 238, 266, 297, 330, 360, 391, 422, 452, 538, 717, 916, 2216, 2560], [0, 51, 80, 110, 146, 173, 205, 237, 266, 299, 330, 360, 392, 423, 452, 484, 640, 917, 947, 2560], [0, 51, 80, 111, 143, 177, 207, 238, 267, 300, 330, 359, 392, 422, 453, 483, 640, 819, 947, 2560], [0, 51, 79, 111, 139, 174, 206, 236, 267, 300, 334, 366, 396, 428, 460, 494, 640, 819, 972, 2560], [0, 51, 80, 106, 142, 175, 205, 239, 270, 300, 332, 366, 398, 429, 462, 494, 640, 819, 972, 2560], [0, 51, 100, 130, 163, 194, 229, 261, 291, 324, 355, 388, 420, 451, 483, 515, 640, 819, 998, 2560], [0, 51, 100, 130, 164, 196, 232, 260, 297, 327, 360, 396, 430, 462, 493, 527, 666, 819, 1024, 2560], [0, 51, 100, 130, 164, 196, 232, 260, 297, 327, 360, 396, 430, 462, 493, 527, 666, 819, 1024, 2560], [0, 51, 100, 130, 164, 196, 232, 260, 297, 327, 360, 396, 430, 462, 493, 527, 666, 819, 1024, 2560], [0, 51, 100, 130, 164, 196, 232, 260, 297, 327, 360, 396, 430, 462, 493, 527, 666, 819, 1024, 2560]], parameter=Ary2D_u8p8_12_20_CalPortIf1/Ary2D}, required-interface=Ary2D_u8p8_12_20_CalPortIf1
      AssiMotTqWhlImbRejctnMinY: parameter-require-com-spec{init-value=[[0, 0, 48, 72, 104, 144, 192, 248, 312, 376, 448, 536, 616, 712, 816, 920, 1536, 3128, 17904, 17904], [0, 0, 64, 104, 152, 216, 288, 376, 472, 576, 696, 824, 968, 1120, 1280, 1761, 3072, 5120, 17904, 17904], [0, 0, 32, 80, 136, 200, 272, 360, 448, 552, 672, 792, 928, 1072, 1224, 1741, 3031, 4728, 17904, 17904], [0, 0, 32, 72, 128, 176, 240, 312, 384, 472, 560, 656, 760, 872, 984, 1112, 2048, 3568, 3792, 15632], [0, 0, 32, 72, 120, 176, 232, 296, 360, 440, 520, 600, 696, 792, 896, 1000, 1741, 2642, 3320, 13472], [0, 0, 32, 72, 112, 168, 224, 280, 344, 416, 496, 576, 656, 744, 840, 944, 1536, 2314, 3024, 11632], [0, 0, 32, 64, 112, 160, 208, 264, 320, 376, 440, 512, 584, 656, 736, 816, 1311, 1925, 2456, 9120], [0, 0, 48, 80, 120, 160, 208, 256, 304, 360, 416, 480, 544, 608, 680, 752, 1126, 1720, 2264, 8272], [0, 0, 48, 80, 120, 160, 208, 248, 304, 352, 408, 472, 536, 600, 664, 736, 1024, 1536, 2160, 7528], [0, 0, 48, 80, 120, 160, 208, 248, 304, 352, 408, 472, 536, 600, 664, 736, 1024, 1536, 2160, 7528], [0, 0, 48, 80, 120, 160, 208, 248, 304, 352, 408, 472, 536, 600, 664, 736, 1024, 1536, 2160, 7528], [0, 0, 48, 80, 120, 160, 208, 248, 304, 352, 408, 472, 536, 600, 664, 736, 1024, 1536, 2160, 7528]], parameter=Ary2D_s4p11_12_20_CalPortIf1/Ary2D}, required-interface=Ary2D_s4p11_12_20_CalPortIf1
      AssiWhlImbRejctnBlndScaX: parameter-require-com-spec{init-value=12 x [0, 512, 1024, 1536, 2253], parameter=Ary2D_u5p11_12_5_CalPortIf1/Ary2D}, required-interface=Ary2D_u5p11_12_5_CalPortIf1
      AssiWhlImbRejctnBlndScaY: parameter-require-com-spec{init-value=12 x 5 x 0, parameter=Ary2D_u2p14_12_5_CalPortIf1/Ary2D}, required-interface=Ary2D_u2p14_12_5_CalPortIf1
    behavior AAACalRegn02Rt01GroupA_Dummy_InternalBehavior: supports-multiple-instantiation=true
      timing event AAACalRegn02Rt01GroupA_Dummy_InitEvent: start-on-event=CalRegn02Rt01GroupADummyInit1, period=0
      runnable CalRegn02Rt01GroupADummyInit1
        44 x parameter access:
          PA_AssiHiFrqGainY_Ary2D: accessed-parameter=AssiHiFrqGainY.Ary2D
          PA_AssiHiFrqHpFilFrqY_Ary1D: accessed-parameter=AssiHiFrqHpFilFrqY.Ary1D
          PA_AssiHiFrqTqWhlImbRejctnTqX_Ary2D: accessed-parameter=AssiHiFrqTqWhlImbRejctnTqX.Ary2D
          PA_AssiHiFrqTqX_Ary2D: accessed-parameter=AssiHiFrqTqX.Ary2D
          PA_AssiHiFrqWhlImbRejctnBlndX_Ary2D: accessed-parameter=AssiHiFrqWhlImbRejctnBlndX.Ary2D
          PA_AssiHiFrqWhlImbRejctnBlndY_Ary2D: accessed-parameter=AssiHiFrqWhlImbRejctnBlndY.Ary2D
          PA_AssiHiFrqWhlImbRejctnGainY_Ary2D: accessed-parameter=AssiHiFrqWhlImbRejctnGainY.Ary2D
          PA_InertiaCmpVelAssiBasdDampgStatY_Ary1D: accessed-parameter=InertiaCmpVelAssiBasdDampgStatY.Ary1D
          PA_InertiaCmpVelDampgFilFrq_Ary1D: accessed-parameter=InertiaCmpVelDampgFilFrq.Ary1D
          PA_InertiaCmpVelDampgFilFrqWhlImbRejctnOn_Ary1D: accessed-parameter=InertiaCmpVelDampgFilFrqWhlImbRejctnOn.Ary1D
          PA_InertiaCmpVelDampgSpdBlndY_Ary1D: accessed-parameter=InertiaCmpVelDampgSpdBlndY.Ary1D
          PA_InertiaCmpVelDampgWhlImbRejctnBlndX_Ary1D: accessed-parameter=InertiaCmpVelDampgWhlImbRejctnBlndX.Ary1D
          PA_InertiaCmpVelDampgWhlImbRejctnBlndY_Ary1D: accessed-parameter=InertiaCmpVelDampgWhlImbRejctnBlndY.Ary1D
          PA_HysCmpEffLossY_Ary1D: accessed-parameter=HysCmpEffLossY.Ary1D
          PA_HysCmpEffOffsY_Ary1D: accessed-parameter=HysCmpEffOffsY.Ary1D
          PA_HysCmpFricWhlImbRejctnBlndX_Ary1D: accessed-parameter=HysCmpFricWhlImbRejctnBlndX.Ary1D
          PA_HysCmpFricWhlImbRejctnBlndY_Ary1D: accessed-parameter=HysCmpFricWhlImbRejctnBlndY.Ary1D
          PA_HysCmpFricWhlImbRejctnOffY_Ary1D: accessed-parameter=HysCmpFricWhlImbRejctnOffY.Ary1D
          PA_HysCmpFricWhlImbRejctnOnY_Ary1D: accessed-parameter=HysCmpFricWhlImbRejctnOnY.Ary1D
          PA_HysCmpHwTqScaX_Ary2D: accessed-parameter=HysCmpHwTqScaX.Ary2D
          PA_HysCmpHwTqScaY_Ary2D: accessed-parameter=HysCmpHwTqScaY.Ary2D
          PA_HysCmpHysSatnY_Ary1D: accessed-parameter=HysCmpHysSatnY.Ary1D
          PA_HysCmpNegHysCmpScaX_Ary1D: accessed-parameter=HysCmpNegHysCmpScaX.Ary1D
          PA_HysCmpNegHysCmpScaY_Ary1D: accessed-parameter=HysCmpNegHysCmpScaY.Ary1D
          PA_HysCmpNegHysCmpX_Ary1D: accessed-parameter=HysCmpNegHysCmpX.Ary1D
          PA_HysCmpNegHysCmpY_Ary1D: accessed-parameter=HysCmpNegHysCmpY.Ary1D
          PA_HysCmpOutpLim_Val: accessed-parameter=HysCmpOutpLim.Val
          PA_HysCmpRevGain_Val: accessed-parameter=HysCmpRevGain.Val
          PA_HysCmpRiseX_Ary1D: accessed-parameter=HysCmpRiseX.Ary1D
          PA_HysCmpRiseY_Ary1D: accessed-parameter=HysCmpRiseY.Ary1D
          PA_DampgHwTqX_Ary1D: accessed-parameter=DampgHwTqX.Ary1D
          PA_DampgHwTqY_Ary1D: accessed-parameter=DampgHwTqY.Ary1D
          PA_DampgHydCoeff{1..4}ScaY_Ary1D: accessed-parameter=DampgHydCoeff{1..4}ScaY.Ary1D
          PA_DampgMotVelX_Ary2D: accessed-parameter=DampgMotVelX.Ary2D
          PA_DampgMotVelY_Ary2D: accessed-parameter=DampgMotVelY.Ary2D
          PA_AssiMotTqWhlImbRejctnMaxX_Ary2D: accessed-parameter=AssiMotTqWhlImbRejctnMaxX.Ary2D
          PA_AssiMotTqWhlImbRejctnMaxY_Ary2D: accessed-parameter=AssiMotTqWhlImbRejctnMaxY.Ary2D
          PA_AssiMotTqWhlImbRejctnMinX_Ary2D: accessed-parameter=AssiMotTqWhlImbRejctnMinX.Ary2D
          PA_AssiMotTqWhlImbRejctnMinY_Ary2D: accessed-parameter=AssiMotTqWhlImbRejctnMinY.Ary2D
          PA_AssiWhlImbRejctnBlndScaX_Ary2D: accessed-parameter=AssiWhlImbRejctnBlndScaX.Ary2D
          PA_AssiWhlImbRejctnBlndScaY_Ary2D: accessed-parameter=AssiWhlImbRejctnBlndScaY.Ary2D
  6 x swc implementation, all with behavior=AAACalRegn02Rt01GroupA_Dummy_InternalBehavior:
    AAACalRegn02Rt00GroupA_Dummy_Implementation
      code-descriptors:
        code Default: artifact-descriptors=autosar-engineering-object={short-label=Default, category=SWSRC}
    AAACalRegn02Rt01GroupA_Dummy_Implementation
      code-descriptors:
        code Default: artifact-descriptors=autosar-engineering-object={short-label=Default, category=SWSRC}
    AAACalRegn02Rt02GroupA_Dummy_Implementation
      code-descriptors:
        code Default: artifact-descriptors=autosar-engineering-object={short-label=Default, category=SWSRC}
    AAACalRegn02Rt03GroupA_Dummy_Implementation
      code-descriptors:
        code Default: artifact-descriptors=autosar-engineering-object={short-label=Default, category=SWSRC}
    AAACalRegn02Rt04GroupA_Dummy_Implementation
      code-descriptors:
        code Default: artifact-descriptors=autosar-engineering-object={short-label=Default, category=SWSRC}
    AAACalRegn02Rt05GroupA_Dummy_Implementation
      code-descriptors:
        code Default: artifact-descriptors=autosar-engineering-object={short-label=Default, category=SWSRC}
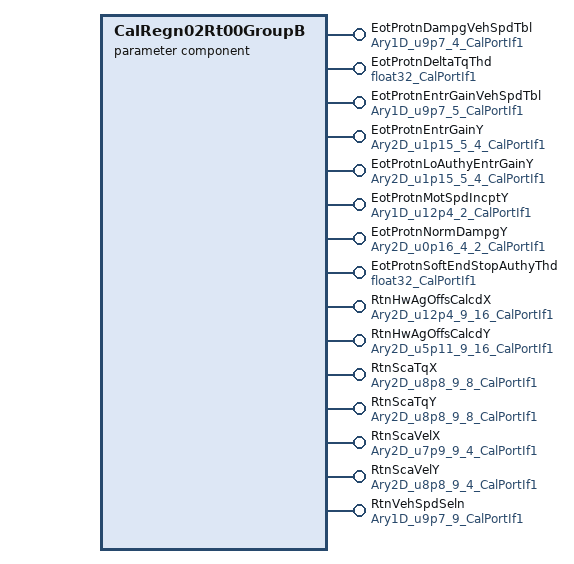
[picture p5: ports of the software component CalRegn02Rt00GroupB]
  parameter sw component type CalRegn02Rt00GroupB
    15 x provide port:
      EotProtnDampgVehSpdTbl: parameter-provide-com-spec{init-value=[0, 640, 1280, 2560], parameter=Ary1D_u9p7_4_CalPortIf1/Ary1D}, provided-interface=Ary1D_u9p7_4_CalPortIf1
      EotProtnDeltaTqThd: parameter-provide-com-spec{init-value=0, parameter=float32_CalPortIf1/Val}, provided-interface=float32_CalPortIf1
      EotProtnEntrGainVehSpdTbl: parameter-provide-com-spec{init-value=[0, 640, 1280, 1920, 2560], parameter=Ary1D_u9p7_5_CalPortIf1/Ary1D}, provided-interface=Ary1D_u9p7_5_CalPortIf1
      EotProtnEntrGainY: parameter-provide-com-spec{init-value=5 x [0, 10813, 21627, 32768], parameter=Ary2D_u1p15_5_4_CalPortIf1/Ary2D}, provided-interface=Ary2D_u1p15_5_4_CalPortIf1
      EotProtnLoAuthyEntrGainY: parameter-provide-com-spec{init-value=5 x [0, 9830, 22938, 32768], parameter=Ary2D_u1p15_5_4_CalPortIf1/Ary2D}, provided-interface=Ary2D_u1p15_5_4_CalPortIf1
      EotProtnMotSpdIncptY: parameter-provide-com-spec{init-value=[10400, 10400], parameter=Ary1D_u12p4_2_CalPortIf1/Ary1D}, provided-interface=Ary1D_u12p4_2_CalPortIf1
      EotProtnNormDampgY: parameter-provide-com-spec{init-value=[[0, 262], [0, 262], [0, 262], [0, 262]], parameter=Ary2D_u0p16_4_2_CalPortIf1/Ary2D}, provided-interface=Ary2D_u0p16_4_2_CalPortIf1
      EotProtnSoftEndStopAuthyThd: parameter-provide-com-spec{init-value=0.9, parameter=float32_CalPortIf1/Val}, provided-interface=float32_CalPortIf1
      RtnHwAgOffsCalcdX: parameter-provide-com-spec{init-value=9 x [0, 8, 16, 80, 160, 320, 480, 720, 960, 1440, 1920, 2880, 4320, 5760, 7200, 8640], parameter=Ary2D_u12p4_9_16_CalPortIf1/Ary2D}, provided-interface=Ary2D_u12p4_9_16_CalPortIf1
      RtnHwAgOffsCalcdY: parameter-provide-com-spec{init-value=9 x 16 x 0, parameter=Ary2D_u5p11_9_16_CalPortIf1/Ary2D}, provided-interface=Ary2D_u5p11_9_16_CalPortIf1
      RtnScaTqX: parameter-provide-com-spec{init-value=9 x [0, 128, 256, 512, 768, 1024, 1280, 2560], parameter=Ary2D_u8p8_9_8_CalPortIf1/Ary2D}, provided-interface=Ary2D_u8p8_9_8_CalPortIf1
      RtnScaTqY: parameter-provide-com-spec{init-value=9 x 8 x 256, parameter=Ary2D_u8p8_9_8_CalPortIf1/Ary2D}, provided-interface=Ary2D_u8p8_9_8_CalPortIf1
      RtnScaVelX: parameter-provide-com-spec{init-value=9 x [0, 20480, 21504, 21504], parameter=Ary2D_u7p9_9_4_CalPortIf1/Ary2D}, provided-interface=Ary2D_u7p9_9_4_CalPortIf1
      RtnScaVelY: parameter-provide-com-spec{init-value=9 x [256, 256, 256, 256], parameter=Ary2D_u8p8_9_4_CalPortIf1/Ary2D}, provided-interface=Ary2D_u8p8_9_4_CalPortIf1
      RtnVehSpdSeln: parameter-provide-com-spec{init-value=[0, 384, 896, 1536, 2560, 3840, 5760, 7680, 10240], parameter=Ary1D_u9p7_9_CalPortIf1/Ary1D}, provided-interface=Ary1D_u9p7_9_CalPortIf1
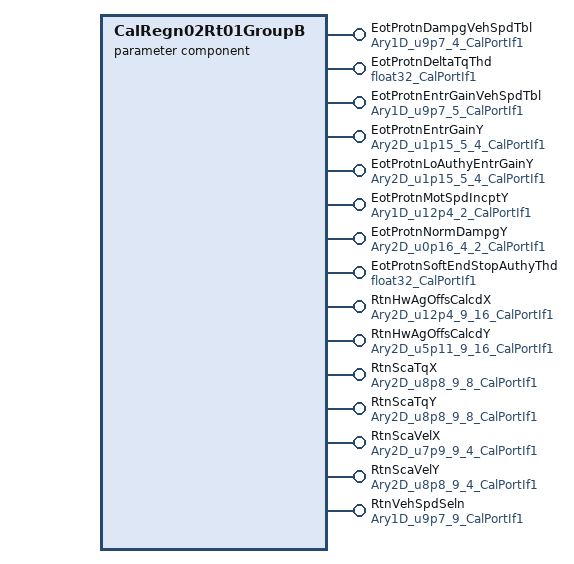
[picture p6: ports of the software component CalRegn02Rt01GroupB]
  parameter sw component type CalRegn02Rt01GroupB
    15 x provide port:
      EotProtnDampgVehSpdTbl: parameter-provide-com-spec{init-value=[0, 640, 1280, 2560], parameter=Ary1D_u9p7_4_CalPortIf1/Ary1D}, provided-interface=Ary1D_u9p7_4_CalPortIf1
      EotProtnDeltaTqThd: parameter-provide-com-spec{init-value=0, parameter=float32_CalPortIf1/Val}, provided-interface=float32_CalPortIf1
      EotProtnEntrGainVehSpdTbl: parameter-provide-com-spec{init-value=[0, 640, 1280, 1920, 2560], parameter=Ary1D_u9p7_5_CalPortIf1/Ary1D}, provided-interface=Ary1D_u9p7_5_CalPortIf1
      EotProtnEntrGainY: parameter-provide-com-spec{init-value=5 x [0, 10813, 21627, 32768], parameter=Ary2D_u1p15_5_4_CalPortIf1/Ary2D}, provided-interface=Ary2D_u1p15_5_4_CalPortIf1
      EotProtnLoAuthyEntrGainY: parameter-provide-com-spec{init-value=5 x [0, 9830, 22938, 32768], parameter=Ary2D_u1p15_5_4_CalPortIf1/Ary2D}, provided-interface=Ary2D_u1p15_5_4_CalPortIf1
      EotProtnMotSpdIncptY: parameter-provide-com-spec{init-value=[10400, 10400], parameter=Ary1D_u12p4_2_CalPortIf1/Ary1D}, provided-interface=Ary1D_u12p4_2_CalPortIf1
      EotProtnNormDampgY: parameter-provide-com-spec{init-value=[[0, 262], [0, 262], [0, 262], [0, 262]], parameter=Ary2D_u0p16_4_2_CalPortIf1/Ary2D}, provided-interface=Ary2D_u0p16_4_2_CalPortIf1
      EotProtnSoftEndStopAuthyThd: parameter-provide-com-spec{init-value=0.9, parameter=float32_CalPortIf1/Val}, provided-interface=float32_CalPortIf1
      RtnHwAgOffsCalcdX: parameter-provide-com-spec{init-value=9 x [0, 8, 16, 80, 160, 320, 480, 720, 960, 1440, 1920, 2880, 4320, 5760, 7200, 8640], parameter=Ary2D_u12p4_9_16_CalPortIf1/Ary2D}, provided-interface=Ary2D_u12p4_9_16_CalPortIf1
      RtnHwAgOffsCalcdY: parameter-provide-com-spec{init-value=9 x 16 x 0, parameter=Ary2D_u5p11_9_16_CalPortIf1/Ary2D}, provided-interface=Ary2D_u5p11_9_16_CalPortIf1
      RtnScaTqX: parameter-provide-com-spec{init-value=9 x [0, 128, 256, 512, 768, 1024, 1280, 2560], parameter=Ary2D_u8p8_9_8_CalPortIf1/Ary2D}, provided-interface=Ary2D_u8p8_9_8_CalPortIf1
      RtnScaTqY: parameter-provide-com-spec{init-value=9 x 8 x 256, parameter=Ary2D_u8p8_9_8_CalPortIf1/Ary2D}, provided-interface=Ary2D_u8p8_9_8_CalPortIf1
      RtnScaVelX: parameter-provide-com-spec{init-value=9 x [0, 20480, 21504, 21504], parameter=Ary2D_u7p9_9_4_CalPortIf1/Ary2D}, provided-interface=Ary2D_u7p9_9_4_CalPortIf1
      RtnScaVelY: parameter-provide-com-spec{init-value=9 x [256, 256, 256, 256], parameter=Ary2D_u8p8_9_4_CalPortIf1/Ary2D}, provided-interface=Ary2D_u8p8_9_4_CalPortIf1
      RtnVehSpdSeln: parameter-provide-com-spec{init-value=[0, 384, 896, 1536, 2560, 3840, 5760, 7680, 10240], parameter=Ary1D_u9p7_9_CalPortIf1/Ary1D}, provided-interface=Ary1D_u9p7_9_CalPortIf1
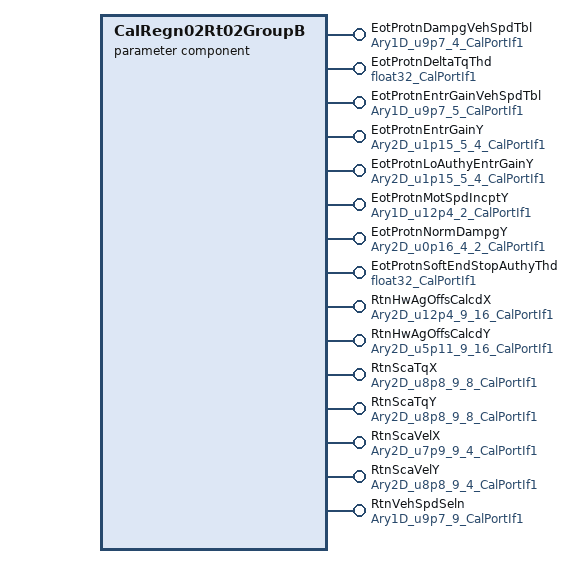
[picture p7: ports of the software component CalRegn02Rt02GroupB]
  parameter sw component type CalRegn02Rt02GroupB
    15 x provide port:
      EotProtnDampgVehSpdTbl: parameter-provide-com-spec{init-value=[0, 640, 1280, 2560], parameter=Ary1D_u9p7_4_CalPortIf1/Ary1D}, provided-interface=Ary1D_u9p7_4_CalPortIf1
      EotProtnDeltaTqThd: parameter-provide-com-spec{init-value=0, parameter=float32_CalPortIf1/Val}, provided-interface=float32_CalPortIf1
      EotProtnEntrGainVehSpdTbl: parameter-provide-com-spec{init-value=[0, 640, 1280, 1920, 2560], parameter=Ary1D_u9p7_5_CalPortIf1/Ary1D}, provided-interface=Ary1D_u9p7_5_CalPortIf1
      EotProtnEntrGainY: parameter-provide-com-spec{init-value=5 x [0, 10813, 21627, 32768], parameter=Ary2D_u1p15_5_4_CalPortIf1/Ary2D}, provided-interface=Ary2D_u1p15_5_4_CalPortIf1
      EotProtnLoAuthyEntrGainY: parameter-provide-com-spec{init-value=5 x [0, 9830, 22938, 32768], parameter=Ary2D_u1p15_5_4_CalPortIf1/Ary2D}, provided-interface=Ary2D_u1p15_5_4_CalPortIf1
      EotProtnMotSpdIncptY: parameter-provide-com-spec{init-value=[10400, 10400], parameter=Ary1D_u12p4_2_CalPortIf1/Ary1D}, provided-interface=Ary1D_u12p4_2_CalPortIf1
      EotProtnNormDampgY: parameter-provide-com-spec{init-value=[[0, 262], [0, 262], [0, 262], [0, 262]], parameter=Ary2D_u0p16_4_2_CalPortIf1/Ary2D}, provided-interface=Ary2D_u0p16_4_2_CalPortIf1
      EotProtnSoftEndStopAuthyThd: parameter-provide-com-spec{init-value=0.9, parameter=float32_CalPortIf1/Val}, provided-interface=float32_CalPortIf1
      RtnHwAgOffsCalcdX: parameter-provide-com-spec{init-value=9 x [0, 8, 16, 80, 160, 320, 480, 720, 960, 1440, 1920, 2880, 4320, 5760, 7200, 8640], parameter=Ary2D_u12p4_9_16_CalPortIf1/Ary2D}, provided-interface=Ary2D_u12p4_9_16_CalPortIf1
      RtnHwAgOffsCalcdY: parameter-provide-com-spec{init-value=9 x 16 x 0, parameter=Ary2D_u5p11_9_16_CalPortIf1/Ary2D}, provided-interface=Ary2D_u5p11_9_16_CalPortIf1
      RtnScaTqX: parameter-provide-com-spec{init-value=9 x [0, 128, 256, 512, 768, 1024, 1280, 2560], parameter=Ary2D_u8p8_9_8_CalPortIf1/Ary2D}, provided-interface=Ary2D_u8p8_9_8_CalPortIf1
      RtnScaTqY: parameter-provide-com-spec{init-value=9 x 8 x 256, parameter=Ary2D_u8p8_9_8_CalPortIf1/Ary2D}, provided-interface=Ary2D_u8p8_9_8_CalPortIf1
      RtnScaVelX: parameter-provide-com-spec{init-value=9 x [0, 20480, 21504, 21504], parameter=Ary2D_u7p9_9_4_CalPortIf1/Ary2D}, provided-interface=Ary2D_u7p9_9_4_CalPortIf1
      RtnScaVelY: parameter-provide-com-spec{init-value=9 x [256, 256, 256, 256], parameter=Ary2D_u8p8_9_4_CalPortIf1/Ary2D}, provided-interface=Ary2D_u8p8_9_4_CalPortIf1
      RtnVehSpdSeln: parameter-provide-com-spec{init-value=[0, 384, 896, 1536, 2560, 3840, 5760, 7680, 10240], parameter=Ary1D_u9p7_9_CalPortIf1/Ary1D}, provided-interface=Ary1D_u9p7_9_CalPortIf1
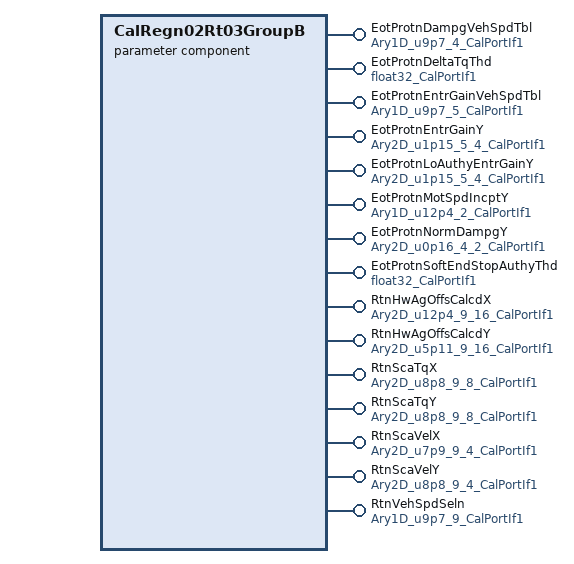
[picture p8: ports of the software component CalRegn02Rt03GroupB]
  parameter sw component type CalRegn02Rt03GroupB
    15 x provide port:
      EotProtnDampgVehSpdTbl: parameter-provide-com-spec{init-value=[0, 640, 1280, 2560], parameter=Ary1D_u9p7_4_CalPortIf1/Ary1D}, provided-interface=Ary1D_u9p7_4_CalPortIf1
      EotProtnDeltaTqThd: parameter-provide-com-spec{init-value=0, parameter=float32_CalPortIf1/Val}, provided-interface=float32_CalPortIf1
      EotProtnEntrGainVehSpdTbl: parameter-provide-com-spec{init-value=[0, 640, 1280, 1920, 2560], parameter=Ary1D_u9p7_5_CalPortIf1/Ary1D}, provided-interface=Ary1D_u9p7_5_CalPortIf1
      EotProtnEntrGainY: parameter-provide-com-spec{init-value=5 x [0, 10813, 21627, 32768], parameter=Ary2D_u1p15_5_4_CalPortIf1/Ary2D}, provided-interface=Ary2D_u1p15_5_4_CalPortIf1
      EotProtnLoAuthyEntrGainY: parameter-provide-com-spec{init-value=5 x [0, 9830, 22938, 32768], parameter=Ary2D_u1p15_5_4_CalPortIf1/Ary2D}, provided-interface=Ary2D_u1p15_5_4_CalPortIf1
      EotProtnMotSpdIncptY: parameter-provide-com-spec{init-value=[10400, 10400], parameter=Ary1D_u12p4_2_CalPortIf1/Ary1D}, provided-interface=Ary1D_u12p4_2_CalPortIf1
      EotProtnNormDampgY: parameter-provide-com-spec{init-value=[[0, 262], [0, 262], [0, 262], [0, 262]], parameter=Ary2D_u0p16_4_2_CalPortIf1/Ary2D}, provided-interface=Ary2D_u0p16_4_2_CalPortIf1
      EotProtnSoftEndStopAuthyThd: parameter-provide-com-spec{init-value=0.9, parameter=float32_CalPortIf1/Val}, provided-interface=float32_CalPortIf1
      RtnHwAgOffsCalcdX: parameter-provide-com-spec{init-value=9 x [0, 8, 16, 80, 160, 320, 480, 720, 960, 1440, 1920, 2880, 4320, 5760, 7200, 8640], parameter=Ary2D_u12p4_9_16_CalPortIf1/Ary2D}, provided-interface=Ary2D_u12p4_9_16_CalPortIf1
      RtnHwAgOffsCalcdY: parameter-provide-com-spec{init-value=9 x 16 x 0, parameter=Ary2D_u5p11_9_16_CalPortIf1/Ary2D}, provided-interface=Ary2D_u5p11_9_16_CalPortIf1
      RtnScaTqX: parameter-provide-com-spec{init-value=9 x [0, 128, 256, 512, 768, 1024, 1280, 2560], parameter=Ary2D_u8p8_9_8_CalPortIf1/Ary2D}, provided-interface=Ary2D_u8p8_9_8_CalPortIf1
      RtnScaTqY: parameter-provide-com-spec{init-value=9 x 8 x 256, parameter=Ary2D_u8p8_9_8_CalPortIf1/Ary2D}, provided-interface=Ary2D_u8p8_9_8_CalPortIf1
      RtnScaVelX: parameter-provide-com-spec{init-value=9 x [0, 20480, 21504, 21504], parameter=Ary2D_u7p9_9_4_CalPortIf1/Ary2D}, provided-interface=Ary2D_u7p9_9_4_CalPortIf1
      RtnScaVelY: parameter-provide-com-spec{init-value=9 x [256, 256, 256, 256], parameter=Ary2D_u8p8_9_4_CalPortIf1/Ary2D}, provided-interface=Ary2D_u8p8_9_4_CalPortIf1
      RtnVehSpdSeln: parameter-provide-com-spec{init-value=[0, 384, 896, 1536, 2560, 3840, 5760, 7680, 10240], parameter=Ary1D_u9p7_9_CalPortIf1/Ary1D}, provided-interface=Ary1D_u9p7_9_CalPortIf1
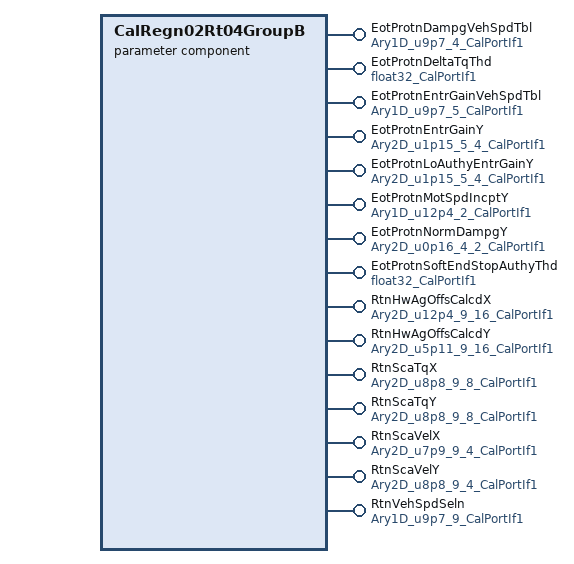
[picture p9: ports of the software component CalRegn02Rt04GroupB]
  parameter sw component type CalRegn02Rt04GroupB
    15 x provide port:
      EotProtnDampgVehSpdTbl: parameter-provide-com-spec{init-value=[0, 640, 1280, 2560], parameter=Ary1D_u9p7_4_CalPortIf1/Ary1D}, provided-interface=Ary1D_u9p7_4_CalPortIf1
      EotProtnDeltaTqThd: parameter-provide-com-spec{init-value=0, parameter=float32_CalPortIf1/Val}, provided-interface=float32_CalPortIf1
      EotProtnEntrGainVehSpdTbl: parameter-provide-com-spec{init-value=[0, 640, 1280, 1920, 2560], parameter=Ary1D_u9p7_5_CalPortIf1/Ary1D}, provided-interface=Ary1D_u9p7_5_CalPortIf1
      EotProtnEntrGainY: parameter-provide-com-spec{init-value=5 x [0, 10813, 21627, 32768], parameter=Ary2D_u1p15_5_4_CalPortIf1/Ary2D}, provided-interface=Ary2D_u1p15_5_4_CalPortIf1
      EotProtnLoAuthyEntrGainY: parameter-provide-com-spec{init-value=5 x [0, 9830, 22938, 32768], parameter=Ary2D_u1p15_5_4_CalPortIf1/Ary2D}, provided-interface=Ary2D_u1p15_5_4_CalPortIf1
      EotProtnMotSpdIncptY: parameter-provide-com-spec{init-value=[10400, 10400], parameter=Ary1D_u12p4_2_CalPortIf1/Ary1D}, provided-interface=Ary1D_u12p4_2_CalPortIf1
      EotProtnNormDampgY: parameter-provide-com-spec{init-value=[[0, 262], [0, 262], [0, 262], [0, 262]], parameter=Ary2D_u0p16_4_2_CalPortIf1/Ary2D}, provided-interface=Ary2D_u0p16_4_2_CalPortIf1
      EotProtnSoftEndStopAuthyThd: parameter-provide-com-spec{init-value=0.9, parameter=float32_CalPortIf1/Val}, provided-interface=float32_CalPortIf1
      RtnHwAgOffsCalcdX: parameter-provide-com-spec{init-value=9 x [0, 8, 16, 80, 160, 320, 480, 720, 960, 1440, 1920, 2880, 4320, 5760, 7200, 8640], parameter=Ary2D_u12p4_9_16_CalPortIf1/Ary2D}, provided-interface=Ary2D_u12p4_9_16_CalPortIf1
      RtnHwAgOffsCalcdY: parameter-provide-com-spec{init-value=9 x 16 x 0, parameter=Ary2D_u5p11_9_16_CalPortIf1/Ary2D}, provided-interface=Ary2D_u5p11_9_16_CalPortIf1
      RtnScaTqX: parameter-provide-com-spec{init-value=9 x [0, 128, 256, 512, 768, 1024, 1280, 2560], parameter=Ary2D_u8p8_9_8_CalPortIf1/Ary2D}, provided-interface=Ary2D_u8p8_9_8_CalPortIf1
      RtnScaTqY: parameter-provide-com-spec{init-value=9 x 8 x 256, parameter=Ary2D_u8p8_9_8_CalPortIf1/Ary2D}, provided-interface=Ary2D_u8p8_9_8_CalPortIf1
      RtnScaVelX: parameter-provide-com-spec{init-value=9 x [0, 20480, 21504, 21504], parameter=Ary2D_u7p9_9_4_CalPortIf1/Ary2D}, provided-interface=Ary2D_u7p9_9_4_CalPortIf1
      RtnScaVelY: parameter-provide-com-spec{init-value=9 x [256, 256, 256, 256], parameter=Ary2D_u8p8_9_4_CalPortIf1/Ary2D}, provided-interface=Ary2D_u8p8_9_4_CalPortIf1
      RtnVehSpdSeln: parameter-provide-com-spec{init-value=[0, 384, 896, 1536, 2560, 3840, 5760, 7680, 10240], parameter=Ary1D_u9p7_9_CalPortIf1/Ary1D}, provided-interface=Ary1D_u9p7_9_CalPortIf1
  parameter sw component type CalRegn02Rt05GroupB
    15 x provide port:
      EotProtnDampgVehSpdTbl: parameter-provide-com-spec{init-value=[0, 640, 1280, 2560], parameter=Ary1D_u9p7_4_CalPortIf1/Ary1D}, provided-interface=Ary1D_u9p7_4_CalPortIf1
      EotProtnDeltaTqThd: parameter-provide-com-spec{init-value=0, parameter=float32_CalPortIf1/Val}, provided-interface=float32_CalPortIf1
      EotProtnEntrGainVehSpdTbl: parameter-provide-com-spec{init-value=[0, 640, 1280, 1920, 2560], parameter=Ary1D_u9p7_5_CalPortIf1/Ary1D}, provided-interface=Ary1D_u9p7_5_CalPortIf1
      EotProtnEntrGainY: parameter-provide-com-spec{init-value=5 x [0, 10813, 21627, 32768], parameter=Ary2D_u1p15_5_4_CalPortIf1/Ary2D}, provided-interface=Ary2D_u1p15_5_4_CalPortIf1
      EotProtnLoAuthyEntrGainY: parameter-provide-com-spec{init-value=5 x [0, 9830, 22938, 32768], parameter=Ary2D_u1p15_5_4_CalPortIf1/Ary2D}, provided-interface=Ary2D_u1p15_5_4_CalPortIf1
      EotProtnMotSpdIncptY: parameter-provide-com-spec{init-value=[10400, 10400], parameter=Ary1D_u12p4_2_CalPortIf1/Ary1D}, provided-interface=Ary1D_u12p4_2_CalPortIf1
      EotProtnNormDampgY: parameter-provide-com-spec{init-value=[[0, 262], [0, 262], [0, 262], [0, 262]], parameter=Ary2D_u0p16_4_2_CalPortIf1/Ary2D}, provided-interface=Ary2D_u0p16_4_2_CalPortIf1
      EotProtnSoftEndStopAuthyThd: parameter-provide-com-spec{init-value=0.9, parameter=float32_CalPortIf1/Val}, provided-interface=float32_CalPortIf1
      RtnHwAgOffsCalcdX: parameter-provide-com-spec{init-value=9 x [0, 8, 16, 80, 160, 320, 480, 720, 960, 1440, 1920, 2880, 4320, 5760, 7200, 8640], parameter=Ary2D_u12p4_9_16_CalPortIf1/Ary2D}, provided-interface=Ary2D_u12p4_9_16_CalPortIf1
      RtnHwAgOffsCalcdY: parameter-provide-com-spec{init-value=9 x 16 x 0, parameter=Ary2D_u5p11_9_16_CalPortIf1/Ary2D}, provided-interface=Ary2D_u5p11_9_16_CalPortIf1
      RtnScaTqX: parameter-provide-com-spec{init-value=9 x [0, 128, 256, 512, 768, 1024, 1280, 2560], parameter=Ary2D_u8p8_9_8_CalPortIf1/Ary2D}, provided-interface=Ary2D_u8p8_9_8_CalPortIf1
      RtnScaTqY: parameter-provide-com-spec{init-value=9 x 8 x 256, parameter=Ary2D_u8p8_9_8_CalPortIf1/Ary2D}, provided-interface=Ary2D_u8p8_9_8_CalPortIf1
      RtnScaVelX: parameter-provide-com-spec{init-value=9 x [0, 20480, 21504, 21504], parameter=Ary2D_u7p9_9_4_CalPortIf1/Ary2D}, provided-interface=Ary2D_u7p9_9_4_CalPortIf1
      RtnScaVelY: parameter-provide-com-spec{init-value=9 x [256, 256, 256, 256], parameter=Ary2D_u8p8_9_4_CalPortIf1/Ary2D}, provided-interface=Ary2D_u8p8_9_4_CalPortIf1
      RtnVehSpdSeln: parameter-provide-com-spec{init-value=[0, 384, 896, 1536, 2560, 3840, 5760, 7680, 10240], parameter=Ary1D_u9p7_9_CalPortIf1/Ary1D}, provided-interface=Ary1D_u9p7_9_CalPortIf1
  application sw component type AAACalRegn02Rt01GroupB_Dummy
    15 x require port:
      EotProtnDampgVehSpdTbl: parameter-require-com-spec{init-value=[0, 640, 1280, 2560], parameter=Ary1D_u9p7_4_CalPortIf1/Ary1D}, required-interface=Ary1D_u9p7_4_CalPortIf1
      EotProtnDeltaTqThd: parameter-require-com-spec{init-value=0, parameter=float32_CalPortIf1/Val}, required-interface=float32_CalPortIf1
      EotProtnEntrGainVehSpdTbl: parameter-require-com-spec{init-value=[0, 640, 1280, 1920, 2560], parameter=Ary1D_u9p7_5_CalPortIf1/Ary1D}, required-interface=Ary1D_u9p7_5_CalPortIf1
      EotProtnEntrGainY: parameter-require-com-spec{init-value=5 x [0, 10813, 21627, 32768], parameter=Ary2D_u1p15_5_4_CalPortIf1/Ary2D}, required-interface=Ary2D_u1p15_5_4_CalPortIf1
      EotProtnLoAuthyEntrGainY: parameter-require-com-spec{init-value=5 x [0, 9830, 22938, 32768], parameter=Ary2D_u1p15_5_4_CalPortIf1/Ary2D}, required-interface=Ary2D_u1p15_5_4_CalPortIf1
      EotProtnMotSpdIncptY: parameter-require-com-spec{init-value=[10400, 10400], parameter=Ary1D_u12p4_2_CalPortIf1/Ary1D}, required-interface=Ary1D_u12p4_2_CalPortIf1
      EotProtnNormDampgY: parameter-require-com-spec{init-value=[[0, 262], [0, 262], [0, 262], [0, 262]], parameter=Ary2D_u0p16_4_2_CalPortIf1/Ary2D}, required-interface=Ary2D_u0p16_4_2_CalPortIf1
      EotProtnSoftEndStopAuthyThd: parameter-require-com-spec{init-value=0.9, parameter=float32_CalPortIf1/Val}, required-interface=float32_CalPortIf1
      RtnHwAgOffsCalcdX: parameter-require-com-spec{init-value=9 x [0, 8, 16, 80, 160, 320, 480, 720, 960, 1440, 1920, 2880, 4320, 5760, 7200, 8640], parameter=Ary2D_u12p4_9_16_CalPortIf1/Ary2D}, required-interface=Ary2D_u12p4_9_16_CalPortIf1
      RtnHwAgOffsCalcdY: parameter-require-com-spec{init-value=9 x 16 x 0, parameter=Ary2D_u5p11_9_16_CalPortIf1/Ary2D}, required-interface=Ary2D_u5p11_9_16_CalPortIf1
      RtnScaTqX: parameter-require-com-spec{init-value=9 x [0, 128, 256, 512, 768, 1024, 1280, 2560], parameter=Ary2D_u8p8_9_8_CalPortIf1/Ary2D}, required-interface=Ary2D_u8p8_9_8_CalPortIf1
      RtnScaTqY: parameter-require-com-spec{init-value=9 x 8 x 256, parameter=Ary2D_u8p8_9_8_CalPortIf1/Ary2D}, required-interface=Ary2D_u8p8_9_8_CalPortIf1
      RtnScaVelX: parameter-require-com-spec{init-value=9 x [0, 20480, 21504, 21504], parameter=Ary2D_u7p9_9_4_CalPortIf1/Ary2D}, required-interface=Ary2D_u7p9_9_4_CalPortIf1
      RtnScaVelY: parameter-require-com-spec{init-value=9 x [256, 256, 256, 256], parameter=Ary2D_u8p8_9_4_CalPortIf1/Ary2D}, required-interface=Ary2D_u8p8_9_4_CalPortIf1
      RtnVehSpdSeln: parameter-require-com-spec{init-value=[0, 384, 896, 1536, 2560, 3840, 5760, 7680, 10240], parameter=Ary1D_u9p7_9_CalPortIf1/Ary1D}, required-interface=Ary1D_u9p7_9_CalPortIf1
    behavior AAACalRegn02Rt01GroupB_Dummy_InternalBehavior: supports-multiple-instantiation=true
      timing event AAACalRegn02Rt01GroupB_Dummy_InitEvent: start-on-event=CalRegn02Rt01GroupBDummyInit1, period=0
      runnable CalRegn02Rt01GroupBDummyInit1
        15 x parameter access:
          PA_EotProtnDampgVehSpdTbl_Ary1D: accessed-parameter=EotProtnDampgVehSpdTbl.Ary1D
          PA_EotProtnDeltaTqThd_Val: accessed-parameter=EotProtnDeltaTqThd.Val
          PA_EotProtnEntrGainVehSpdTbl_Ary1D: accessed-parameter=EotProtnEntrGainVehSpdTbl.Ary1D
          PA_EotProtnEntrGainY_Ary2D: accessed-parameter=EotProtnEntrGainY.Ary2D
          PA_EotProtnLoAuthyEntrGainY_Ary2D: accessed-parameter=EotProtnLoAuthyEntrGainY.Ary2D
          PA_EotProtnMotSpdIncptY_Ary1D: accessed-parameter=EotProtnMotSpdIncptY.Ary1D
          PA_EotProtnNormDampgY_Ary2D: accessed-parameter=EotProtnNormDampgY.Ary2D
          PA_EotProtnSoftEndStopAuthyThd_Val: accessed-parameter=EotProtnSoftEndStopAuthyThd.Val
          PA_RtnHwAgOffsCalcdX_Ary2D: accessed-parameter=RtnHwAgOffsCalcdX.Ary2D
          PA_RtnHwAgOffsCalcdY_Ary2D: accessed-parameter=RtnHwAgOffsCalcdY.Ary2D
          PA_RtnScaTqX_Ary2D: accessed-parameter=RtnScaTqX.Ary2D
          PA_RtnScaTqY_Ary2D: accessed-parameter=RtnScaTqY.Ary2D
          PA_RtnScaVelX_Ary2D: accessed-parameter=RtnScaVelX.Ary2D
          PA_RtnScaVelY_Ary2D: accessed-parameter=RtnScaVelY.Ary2D
          PA_RtnVehSpdSeln_Ary1D: accessed-parameter=RtnVehSpdSeln.Ary1D
  6 x swc implementation, all with behavior=AAACalRegn02Rt01GroupB_Dummy_InternalBehavior:
    AAACalRegn02Rt00GroupB_Dummy_Implementation
      code-descriptors:
        code Default: artifact-descriptors=autosar-engineering-object={short-label=Default, category=SWSRC}
    AAACalRegn02Rt01GroupB_Dummy_Implementation
      code-descriptors:
        code Default: artifact-descriptors=autosar-engineering-object={short-label=Default, category=SWSRC}
    AAACalRegn02Rt02GroupB_Dummy_Implementation
      code-descriptors:
        code Default: artifact-descriptors=autosar-engineering-object={short-label=Default, category=SWSRC}
    AAACalRegn02Rt03GroupB_Dummy_Implementation
      code-descriptors:
        code Default: artifact-descriptors=autosar-engineering-object={short-label=Default, category=SWSRC}
    AAACalRegn02Rt04GroupB_Dummy_Implementation
      code-descriptors:
        code Default: artifact-descriptors=autosar-engineering-object={short-label=Default, category=SWSRC}
    AAACalRegn02Rt05GroupB_Dummy_Implementation
      code-descriptors:
        code Default: artifact-descriptors=autosar-engineering-object={short-label=Default, category=SWSRC}
  parameter sw component type CalRegn02Inin00
    11 x provide port:
      SysGlbPrmSysKineRat: parameter-provide-com-spec{init-value=22, parameter=float32_CalPortIf1/Val}, provided-interface=float32_CalPortIf1
      VehSigCdngVehSpdSlewRate: parameter-provide-com-spec{init-value=50, parameter=float32_CalPortIf1/Val}, provided-interface=float32_CalPortIf1
      HiLoadStallLimrMotTqCmdFetMtgtnEnaFilFrq: parameter-provide-com-spec{init-value=2, parameter=float32_CalPortIf1/Val}, provided-interface=float32_CalPortIf1
      HiLoadStallLimrMotTqCmdFilFrq: parameter-provide-com-spec{init-value=2, parameter=float32_CalPortIf1/Val}, provided-interface=float32_CalPortIf1
      HiLoadStallLimrMotVelMgnThd: parameter-provide-com-spec{init-value=[1.375, 1.375], parameter=Ary1D_f32_2_CalPortIf1/Ary1D}, provided-interface=Ary1D_f32_2_CalPortIf1
      HiLoadStallLimrStallMotTqCmdFetMtgtnLimX: parameter-provide-com-spec{init-value=[0, 563, 640, 717, 768, 768], parameter=Ary1D_u8p8_6_CalPortIf1/Ary1D}, provided-interface=Ary1D_u8p8_6_CalPortIf1
      HiLoadStallLimrStallMotTqCmdFetMtgtnLimY: parameter-provide-com-spec{init-value=[768, 768, 512, 256, 0, 0], parameter=Ary1D_u8p8_6_CalPortIf1/Ary1D}, provided-interface=Ary1D_u8p8_6_CalPortIf1
      HiLoadStallLimrStallMotTqCmdLimX: parameter-provide-com-spec{init-value=[0, 563, 640, 717, 768, 768], parameter=Ary1D_u8p8_6_CalPortIf1/Ary1D}, provided-interface=Ary1D_u8p8_6_CalPortIf1
      HiLoadStallLimrStallMotTqCmdLimY: parameter-provide-com-spec{init-value=[768, 768, 512, 256, 0, 0], parameter=Ary1D_u8p8_6_CalPortIf1/Ary1D}, provided-interface=Ary1D_u8p8_6_CalPortIf1
      HiLoadStallLimrStallMotTqLimSlewRate: parameter-provide-com-spec{init-value=[0.101563, 0.101563], parameter=Ary1D_f32_2_CalPortIf1/Ary1D}, provided-interface=Ary1D_f32_2_CalPortIf1
      HiLoadStallLimrStallThermLimSca: parameter-provide-com-spec{init-value=0.5, parameter=float32_CalPortIf1/Val}, provided-interface=float32_CalPortIf1
  parameter sw component type CalRegn02Inin00GroupA
    29 x provide port:
      AssiHiFrqHpFilFrq: parameter-provide-com-spec{init-value=15, parameter=float32_CalPortIf1/Val}, provided-interface=float32_CalPortIf1
      InertiaCmpVelAssiBasdDampgCoeffX: parameter-provide-com-spec{init-value=[0, 2048, 4096, 6144, 8192, 10240, 12288, 14336, 16384, 18432], parameter=Ary1D_u4p12_10_CalPortIf1/Ary1D}, provided-interface=Ary1D_u4p12_10_CalPortIf1
      InertiaCmpVelAssiBasdDampgRollgWhlImbRejctnOnY: parameter-provide-com-spec{init-value=10 x 0, parameter=Ary1D_u0p16_10_CalPortIf1/Ary1D}, provided-interface=Ary1D_u0p16_10_CalPortIf1
      InertiaCmpVelAssiBasdDampgRollgY: parameter-provide-com-spec{init-value=10 x 0, parameter=Ary1D_u0p16_10_CalPortIf1/Ary1D}, provided-interface=Ary1D_u0p16_10_CalPortIf1
      InertiaCmpVelAssiBasdDampgStatWhlImbRejctnOnY: parameter-provide-com-spec{init-value=10 x 0, parameter=Ary1D_u0p16_10_CalPortIf1/Ary1D}, provided-interface=Ary1D_u0p16_10_CalPortIf1
      InertiaCmpVelCmdScaY: parameter-provide-com-spec{init-value=12 x 384, parameter=Ary1D_u2p14_12_CalPortIf1/Ary1D}, provided-interface=Ary1D_u2p14_12_CalPortIf1
      InertiaCmpVelDampgDecelGain: parameter-provide-com-spec{init-value=1, parameter=float32_CalPortIf1/Val}, provided-interface=float32_CalPortIf1
      InertiaCmpVelDampgDecelGainFallSlew: parameter-provide-com-spec{init-value=-4500, parameter=float32_CalPortIf1/Val}, provided-interface=float32_CalPortIf1
      InertiaCmpVelDampgDecelGainRisngSlewX: parameter-provide-com-spec{init-value=[0, 640, 1088, 1120, 1152, 1184], parameter=Ary1D_u11p5_6_CalPortIf1/Ary1D}, provided-interface=Ary1D_u11p5_6_CalPortIf1
      InertiaCmpVelDampgDecelGainRisngSlewY: parameter-provide-com-spec{init-value=6 x 36000, parameter=Ary1D_u13p3_6_CalPortIf1/Ary1D}, provided-interface=Ary1D_u13p3_6_CalPortIf1
      InertiaCmpVelDampgGainOffThd: parameter-provide-com-spec{init-value=1, parameter=float32_CalPortIf1/Val}, provided-interface=float32_CalPortIf1
      InertiaCmpVelDampgGainOnThd: parameter-provide-com-spec{init-value=10, parameter=float32_CalPortIf1/Val}, provided-interface=float32_CalPortIf1
      InertiaCmpVelDecelGainEnaCal: parameter-provide-com-spec{init-value=0, parameter=Logl}, provided-interface=boolean_CalPortIf1
      InertiaCmpVelModWhlImbRejctnBlndX: parameter-provide-com-spec{init-value=[0, 4096], parameter=Ary1D_u4p12_2_CalPortIf1/Ary1D}, provided-interface=Ary1D_u4p12_2_CalPortIf1
      InertiaCmpVelModWhlImbRejctnBlndY: parameter-provide-com-spec{init-value=[32768, 0], parameter=Ary1D_u1p15_2_CalPortIf1/Ary1D}, provided-interface=Ary1D_u1p15_2_CalPortIf1
      InertiaCmpVelMotInertia: parameter-provide-com-spec{init-value=0.001, parameter=float32_CalPortIf1/Val}, provided-interface=float32_CalPortIf1
      InertiaCmpVelMotVelBasdOutpScagX: parameter-provide-com-spec{init-value=[1005, 1100], parameter=Ary1D_u12p4_2_CalPortIf1/Ary1D}, provided-interface=Ary1D_u12p4_2_CalPortIf1
      InertiaCmpVelMotVelBasdOutpScagY: parameter-provide-com-spec{init-value=[32768, 32768], parameter=Ary1D_u1p15_2_CalPortIf1/Ary1D}, provided-interface=Ary1D_u1p15_2_CalPortIf1
      InertiaCmpVelNotchBlndY: parameter-provide-com-spec{init-value=12 x 0, parameter=Ary1D_u1p15_12_CalPortIf1/Ary1D}, provided-interface=Ary1D_u1p15_12_CalPortIf1
      InertiaCmpVelNotchFilStruct: parameter-provide-com-spec=parameter=Rec, provided-interface=FilNotchGainRec1_CalPortIf1
      InertiaCmpVelTqSnsrVelFilFrq: parameter-provide-com-spec{init-value=20, parameter=float32_CalPortIf1/Val}, provided-interface=float32_CalPortIf1
      InertiaCmpVelTqSnsrVelSca: parameter-provide-com-spec{init-value=12 x 0, parameter=Ary1D_u2p14_12_CalPortIf1/Ary1D}, provided-interface=Ary1D_u2p14_12_CalPortIf1
      HysCmpAssiCmdLpFilFrq: parameter-provide-com-spec{init-value=50, parameter=float32_CalPortIf1/Val}, provided-interface=float32_CalPortIf1
      HysCmpAssiInpLim: parameter-provide-com-spec{init-value=45056, parameter=u9p7_CalPortIf1/Val}, provided-interface=u9p7_CalPortIf1
      HysCmpFinalOutpLpFilFrq: parameter-provide-com-spec{init-value=50, parameter=float32_CalPortIf1/Val}, provided-interface=float32_CalPortIf1
      HysCmpFricTScaX: parameter-provide-com-spec{init-value=[-80, -60, -40, -20, 0, 50, 100, 160], parameter=Ary1D_s14p1_8_CalPortIf1/Ary1D}, provided-interface=Ary1D_s14p1_8_CalPortIf1
      HysCmpFricTScaY: parameter-provide-com-spec{init-value=8 x 128, parameter=Ary1D_u9p7_8_CalPortIf1/Ary1D}, provided-interface=Ary1D_u9p7_8_CalPortIf1
      HysCmpHwTqLpFilFrq: parameter-provide-com-spec{init-value=50, parameter=float32_CalPortIf1/Val}, provided-interface=float32_CalPortIf1
      DampgHydAssiLim: parameter-provide-com-spec{init-value=12 x 36045, parameter=Ary1D_u4p12_12_CalPortIf1/Ary1D}, provided-interface=Ary1D_u4p12_12_CalPortIf1
  parameter sw component type CalRegn02Inin00GroupB
    47 x provide port:
      RtnPahFwlUpprBndTblX: parameter-provide-com-spec{init-value=[-6400, -1600, 0, 800, 1600, 2400, 3200, 4000, 4800, 5600, 6400], parameter=Ary1D_s11p4_11_CalPortIf1/Ary1D}, provided-interface=Ary1D_s11p4_11_CalPortIf1
      RtnPahFwlUpprBndTblY: parameter-provide-com-spec{init-value=8 x 11 x 18022, parameter=Ary2D_s4p11_8_11_CalPortIf1/Ary2D}, provided-interface=Ary2D_s4p11_8_11_CalPortIf1
      RtnPahFwlVehSpd: parameter-provide-com-spec{init-value=[0, 384, 1280, 2560, 3840, 7680, 12800, 32640], parameter=Ary1D_u9p7_8_CalPortIf1/Ary1D}, provided-interface=Ary1D_u9p7_8_CalPortIf1
      EotProtnFwlActvCmdLowrBnd: parameter-provide-com-spec{init-value=[-512, -512, -512, -512], parameter=Ary1D_s4p11_4_CalPortIf1/Ary1D}, provided-interface=Ary1D_s4p11_4_CalPortIf1
      EotProtnFwlActvCmdUpprBnd: parameter-provide-com-spec{init-value=[18022, 18022, 18022, 18022], parameter=Ary1D_s4p11_4_CalPortIf1/Ary1D}, provided-interface=Ary1D_s4p11_4_CalPortIf1
      EotProtnFwlEotDampgActvBndY: parameter-provide-com-spec{init-value=[5 x 2253, 5 x 2253, 5 x 2253, 5 x 2253], parameter=Ary2D_s7p8_4_5_CalPortIf1/Ary2D}, provided-interface=Ary2D_s7p8_4_5_CalPortIf1
      EotProtnDampgSlew: parameter-provide-com-spec{init-value=400, parameter=float32_CalPortIf1/Val}, provided-interface=float32_CalPortIf1
      EotProtnDftPosn: parameter-provide-com-spec{init-value=100, parameter=float32_CalPortIf1/Val}, provided-interface=float32_CalPortIf1
      EotProtnEntrGainAuthyThd: parameter-provide-com-spec{init-value=0.5, parameter=float32_CalPortIf1/Val}, provided-interface=float32_CalPortIf1
      EotProtnEntrGainX: parameter-provide-com-spec{init-value=5 x [0, 480, 960, 1440], parameter=Ary2D_u12p4_5_4_CalPortIf1/Ary2D}, provided-interface=Ary2D_u12p4_5_4_CalPortIf1
      EotProtnEntrStLpFilFrq: parameter-provide-com-spec{init-value=30, parameter=float32_CalPortIf1/Val}, provided-interface=float32_CalPortIf1
      EotProtnExitDampgY: parameter-provide-com-spec{init-value=[[0, 262], [0, 262], [0, 262], [0, 262]], parameter=Ary2D_u0p16_4_2_CalPortIf1/Ary2D}, provided-interface=Ary2D_u0p16_4_2_CalPortIf1
      EotProtnExitStLpFilFrq: parameter-provide-com-spec{init-value=5, parameter=float32_CalPortIf1/Val}, provided-interface=float32_CalPortIf1
      EotProtnHwAgGain: parameter-provide-com-spec{init-value=0.15, parameter=float32_CalPortIf1/Val}, provided-interface=float32_CalPortIf1
      EotProtnHwAgMax: parameter-provide-com-spec{init-value=600, parameter=float32_CalPortIf1/Val}, provided-interface=float32_CalPortIf1
      EotProtnHwAgMin: parameter-provide-com-spec{init-value=550, parameter=float32_CalPortIf1/Val}, provided-interface=float32_CalPortIf1
      EotProtnHwDegDampgX: parameter-provide-com-spec{init-value=[[1920, 0], [1920, 0], [1920, 0], [1920, 0]], parameter=Ary2D_u12p4_4_2_CalPortIf1/Ary2D}, provided-interface=Ary2D_u12p4_4_2_CalPortIf1
      EotProtnHwTqLpFilFrq: parameter-provide-com-spec{init-value=30, parameter=float32_CalPortIf1/Val}, provided-interface=float32_CalPortIf1
      EotProtnHwTqScaX: parameter-provide-com-spec{init-value=[0, 4096], parameter=Ary1D_u4p12_2_CalPortIf1/Ary1D}, provided-interface=Ary1D_u4p12_2_CalPortIf1
      EotProtnMotSpdIncptSca: parameter-provide-com-spec{init-value=0.02, parameter=float32_CalPortIf1/Val}, provided-interface=float32_CalPortIf1
      EotProtnMotSpdIncptX: parameter-provide-com-spec{init-value=[800, 400], parameter=Ary1D_u12p4_2_CalPortIf1/Ary1D}, provided-interface=Ary1D_u12p4_2_CalPortIf1
      EotProtnMotVelGain: parameter-provide-com-spec{init-value=0.29, parameter=float32_CalPortIf1/Val}, provided-interface=float32_CalPortIf1
      EotProtnPosnRampStep: parameter-provide-com-spec{init-value=3, parameter=float32_CalPortIf1/Val}, provided-interface=float32_CalPortIf1
      EotProtnRackTrvlLimrAuthyThd: parameter-provide-com-spec{init-value=1, parameter=float32_CalPortIf1/Val}, provided-interface=float32_CalPortIf1
      EotProtnRackTrvlLimrAuthyThdLimd: parameter-provide-com-spec{init-value=1, parameter=float32_CalPortIf1/Val}, provided-interface=float32_CalPortIf1
      EotProtnRackTrvlLimrEna: parameter-provide-com-spec{init-value=0, parameter=Logl}, provided-interface=boolean_CalPortIf1
      EotProtnRackTrvlLimrRng: parameter-provide-com-spec{init-value=90, parameter=float32_CalPortIf1/Val}, provided-interface=float32_CalPortIf1
      EotProtnRackTrvlLimrRngLimd: parameter-provide-com-spec{init-value=20, parameter=float32_CalPortIf1/Val}, provided-interface=float32_CalPortIf1
      EotProtnRackTrvlLimrVehSpdThd: parameter-provide-com-spec{init-value=20, parameter=float32_CalPortIf1/Val}, provided-interface=float32_CalPortIf1
      EotProtnRunEotVelImpctAndSoftEndStop: parameter-provide-com-spec{init-value=0, parameter=Logl}, provided-interface=boolean_CalPortIf1
      EotProtnSoftEndStopEna: parameter-provide-com-spec{init-value=0, parameter=Logl}, provided-interface=boolean_CalPortIf1
      EotProtnSoftEndStopVehSpdThd: parameter-provide-com-spec{init-value=30, parameter=float32_CalPortIf1/Val}, provided-interface=float32_CalPortIf1
      EotLrngAuthyStrtLrn: parameter-provide-com-spec{init-value=1, parameter=float32_CalPortIf1/Val}, provided-interface=float32_CalPortIf1
      EotLrngEntrAndExitHysRngLimr: parameter-provide-com-spec{init-value=3, parameter=float32_CalPortIf1/Val}, provided-interface=float32_CalPortIf1
      EotLrngEotLrnTmr: parameter-provide-com-spec{init-value=100, parameter=uint16_CalPortIf1/Val}, provided-interface=uint16_CalPortIf1
      EotLrngHwTqEotLrn: parameter-provide-com-spec{init-value=2, parameter=float32_CalPortIf1/Val}, provided-interface=float32_CalPortIf1
      EotLrngMotVelEotLrn: parameter-provide-com-spec{init-value=50, parameter=float32_CalPortIf1/Val}, provided-interface=float32_CalPortIf1
      EotLrngRackTrvlMax: parameter-provide-com-spec{init-value=800, parameter=float32_CalPortIf1/Val}, provided-interface=float32_CalPortIf1
      EotLrngRackTrvlMin: parameter-provide-com-spec{init-value=400, parameter=float32_CalPortIf1/Val}, provided-interface=float32_CalPortIf1
      EotLrngRstAuthyMin: parameter-provide-com-spec{init-value=1, parameter=float32_CalPortIf1/Val}, provided-interface=float32_CalPortIf1
      RtnHwAuthyScaX: parameter-provide-com-spec{init-value=[0, 128, 192, 256], parameter=Ary1D_u8p8_4_CalPortIf1/Ary1D}, provided-interface=Ary1D_u8p8_4_CalPortIf1
      RtnHwAuthyScaY: parameter-provide-com-spec{init-value=[0, 0, 0, 128], parameter=Ary1D_u9p7_4_CalPortIf1/Ary1D}, provided-interface=Ary1D_u9p7_4_CalPortIf1
      RtnHwAuthySlew: parameter-provide-com-spec{init-value=0.5, parameter=float32_CalPortIf1/Val}, provided-interface=float32_CalPortIf1
      RtnOffsRng: parameter-provide-com-spec{init-value=17, parameter=float32_CalPortIf1/Val}, provided-interface=float32_CalPortIf1
      RtnOffsSlew: parameter-provide-com-spec{init-value=0.04, parameter=float32_CalPortIf1/Val}, provided-interface=float32_CalPortIf1
      RtnTScaX: parameter-provide-com-spec{init-value=[-640, -560, -480, -320, -160, 0, 160, 320, 480, 640, 800, 960, 1120, 1440], parameter=Ary1D_s11p4_14_CalPortIf1/Ary1D}, provided-interface=Ary1D_s11p4_14_CalPortIf1
      RtnTScaY: parameter-provide-com-spec{init-value=14 x 256, parameter=Ary1D_u8p8_14_CalPortIf1/Ary1D}, provided-interface=Ary1D_u8p8_14_CalPortIf1
  parameter sw component type CalRegn02Cmn
    161 x provide port:
      MotRplCoggCmdHrmncOrder1Elec: parameter-provide-com-spec{init-value=6, parameter=uint8_CalPortIf1/Val}, provided-interface=uint8_CalPortIf1
      MotRplCoggCmdHrmncOrder2Elec: parameter-provide-com-spec{init-value=12, parameter=uint8_CalPortIf1/Val}, provided-interface=uint8_CalPortIf1
      MotRplCoggCmdHrmncOrder3Elec: parameter-provide-com-spec{init-value=18, parameter=uint8_CalPortIf1/Val}, provided-interface=uint8_CalPortIf1
      MotRplCoggCfgMotAgTiDly: parameter-provide-com-spec{init-value=0, parameter=float32_CalPortIf1/Val}, provided-interface=float32_CalPortIf1
      MotRplCoggCfgMotCurrDaxRplBilnrSeln: parameter-provide-com-spec{init-value=[0, 1280, 3200, 6400, 7680, 9600, 11520, 12800, 14080, 16000], parameter=Ary1D_u9p7_10_CalPortIf1/Ary1D}, provided-interface=Ary1D_u9p7_10_CalPortIf1
      MotRplCoggCfgMotCurrQaxRpl: parameter-provide-com-spec{init-value=[0, 1280, 3200, 6400, 7680, 9600, 12800, 13440, 14080, 15360, 16000, 17280], parameter=Ary1D_u9p7_12_CalPortIf1/Ary1D}, provided-interface=Ary1D_u9p7_12_CalPortIf1
      MotRplCoggCfgMotTqCmdCurrRgltrBwCmpMgnY: parameter-provide-com-spec{init-value=20 x 8 x 0, parameter=Ary2D_u3p13_20_8_CalPortIf1/Ary2D}, provided-interface=Ary2D_u3p13_20_8_CalPortIf1
      MotRplCoggCfgMotTqCmdCurrRgltrBwCmpPhaY: parameter-provide-com-spec{init-value=20 x 8 x 0, parameter=Ary2D_u0p16_20_8_CalPortIf1/Ary2D}, provided-interface=Ary2D_u0p16_20_8_CalPortIf1
      MotRplCoggCfgMotTqCmdCurrRgltrBwCmpX: parameter-provide-com-spec{init-value=[0, 1024, 2048, 4096, 6144, 8192, 9216, 10240], parameter=Ary1D_u5p11_8_CalPortIf1/Ary1D}, provided-interface=Ary1D_u5p11_8_CalPortIf1
      MotRplCoggCfgMotTqRplOrder1X: parameter-provide-com-spec{init-value=10 x 12 x 0, parameter=Ary2D_s1p14_10_12_CalPortIf1/Ary2D}, provided-interface=Ary2D_s1p14_10_12_CalPortIf1
      MotRplCoggCfgMotTqRplOrder1Y: parameter-provide-com-spec{init-value=10 x 12 x 0, parameter=Ary2D_s1p14_10_12_CalPortIf1/Ary2D}, provided-interface=Ary2D_s1p14_10_12_CalPortIf1
      MotRplCoggCfgMotTqRplOrder2X: parameter-provide-com-spec{init-value=10 x 12 x 0, parameter=Ary2D_s1p14_10_12_CalPortIf1/Ary2D}, provided-interface=Ary2D_s1p14_10_12_CalPortIf1
      MotRplCoggCfgMotTqRplOrder2Y: parameter-provide-com-spec{init-value=10 x 12 x 0, parameter=Ary2D_s1p14_10_12_CalPortIf1/Ary2D}, provided-interface=Ary2D_s1p14_10_12_CalPortIf1
      MotRplCoggCfgMotTqRplOrder3X: parameter-provide-com-spec{init-value=10 x 12 x 0, parameter=Ary2D_s1p14_10_12_CalPortIf1/Ary2D}, provided-interface=Ary2D_s1p14_10_12_CalPortIf1
      MotRplCoggCfgMotTqRplOrder3Y: parameter-provide-com-spec{init-value=10 x 12 x 0, parameter=Ary2D_s1p14_10_12_CalPortIf1/Ary2D}, provided-interface=Ary2D_s1p14_10_12_CalPortIf1
      MotRplCoggCfgMotVelBilnrSeln: parameter-provide-com-spec{init-value=[0, 100, 114, 303, 800, 1200, 2600, 3200, 3700, 4200, 5000, 6000, 7200, 7500, 8000, 8500, 9000, 9500, 10000, 11000], parameter=Ary1D_u16p0_20_CalPortIf1/Ary1D}, provided-interface=Ary1D_u16p0_20_CalPortIf1
      LoaMgrCurrIvtrMtgtnRate: parameter-provide-com-spec{init-value=1, parameter=float32_CalPortIf1/Val}, provided-interface=float32_CalPortIf1
      LoaMgrCurrIvtrMtgtnSca: parameter-provide-com-spec{init-value=1, parameter=float32_CalPortIf1/Val}, provided-interface=float32_CalPortIf1
      LoaMgrCurrMeasMtgtnRate: parameter-provide-com-spec{init-value=1, parameter=float32_CalPortIf1/Val}, provided-interface=float32_CalPortIf1
      LoaMgrCurrMeasMtgtnSca: parameter-provide-com-spec{init-value=1, parameter=float32_CalPortIf1/Val}, provided-interface=float32_CalPortIf1
      LoaMgrIvtrMtgtnRate: parameter-provide-com-spec{init-value=1, parameter=float32_CalPortIf1/Val}, provided-interface=float32_CalPortIf1
      LoaMgrIvtrMtgtnSca: parameter-provide-com-spec{init-value=1, parameter=float32_CalPortIf1/Val}, provided-interface=float32_CalPortIf1
      LoaMgrLimdStRate: parameter-provide-com-spec{init-value=1, parameter=float32_CalPortIf1/Val}, provided-interface=float32_CalPortIf1
      LoaMgrLimdStSca: parameter-provide-com-spec{init-value=1, parameter=float32_CalPortIf1/Val}, provided-interface=float32_CalPortIf1
      LoaMgrMotAgMtgtnRate: parameter-provide-com-spec{init-value=1, parameter=float32_CalPortIf1/Val}, provided-interface=float32_CalPortIf1
      LoaMgrMotAgMtgtnSca: parameter-provide-com-spec{init-value=1, parameter=float32_CalPortIf1/Val}, provided-interface=float32_CalPortIf1
      NxtrCalIdsCal1DevlpRelNr: parameter-provide-com-spec{init-value=0, parameter=uint32_CalPortIf1/Val}, provided-interface=uint32_CalPortIf1
      NxtrCalIdsCal1DevlpVers: parameter-provide-com-spec{init-value=0, parameter=uint8_CalPortIf1/Val}, provided-interface=uint8_CalPortIf1
      NxtrCalIdsCal1DevlpAuthor: parameter-provide-com-spec{init-value=6 x 0, parameter=Ary1D_u08_6_CalPortIf1/Ary1D}, provided-interface=Ary1D_u08_6_CalPortIf1
      NxtrCalIdsCal1DevlpDesc: parameter-provide-com-spec{init-value=48 x 0, parameter=Ary1D_u08_48_CalPortIf1/Ary1D}, provided-interface=Ary1D_u08_48_CalPortIf1
      NxtrCalIdsCal1DevlpRelSt: parameter-provide-com-spec{init-value=0, parameter=uint8_CalPortIf1/Val}, provided-interface=uint8_CalPortIf1
      NxtrCalIdsCal1DevlpTiStamp: parameter-provide-com-spec{init-value=0, parameter=uint32_CalPortIf1/Val}, provided-interface=uint32_CalPortIf1
      CmnMfgSrvCal2RelNr: parameter-provide-com-spec{init-value=0, parameter=uint32_CalPortIf1/Val}, provided-interface=uint32_CalPortIf1
      FordBlaBoxIfCmnVehWhlBas: parameter-provide-com-spec{init-value=3099, parameter=uint16_CalPortIf1/Val}, provided-interface=uint16_CalPortIf1
      FordBlaBoxIfCmnVehSteerRat: parameter-provide-com-spec{init-value=0, parameter=u8p8_CalPortIf1/Val}, provided-interface=u8p8_CalPortIf1
      FordHwTqCdngAppldFinalMotTqVldTiThd: parameter-provide-com-spec{init-value=0, parameter=u16p0_CalPortIf1/Val}, provided-interface=u16p0_CalPortIf1
      FordHwTqCdngInpTqRawVldTiThd: parameter-provide-com-spec{init-value=0, parameter=u16p0_CalPortIf1/Val}, provided-interface=u16p0_CalPortIf1
      FordHwAgArbnMotVelVldFlgRcvrTiThd: parameter-provide-com-spec{init-value=30000, parameter=uint16_CalPortIf1/Val}, provided-interface=uint16_CalPortIf1
      FordHwAgArbnNonAbsCentrNotDetdTiThd: parameter-provide-com-spec{init-value=30000, parameter=uint16_CalPortIf1/Val}, provided-interface=uint16_CalPortIf1
      FordHwAgArbnPhyRackTrvlThd: parameter-provide-com-spec{init-value=65535, parameter=float32_CalPortIf1/Val}, provided-interface=float32_CalPortIf1
      FordHwAgArbnRelPosnVldFlgRcvryTiThd: parameter-provide-com-spec{init-value=0, parameter=uint16_CalPortIf1/Val}, provided-interface=uint16_CalPortIf1
      FordHwTqCmdOvrlLimrCombdBwY: parameter-provide-com-spec{init-value=8 x 0, parameter=Ary1D_u13p3_8_CalPortIf1/Ary1D}, provided-interface=Ary1D_u13p3_8_CalPortIf1
      FordHwTqCmdOvrlLimrCombdTqRateY: parameter-provide-com-spec{init-value=8 x 64, parameter=Ary1D_u13p3_8_CalPortIf1/Ary1D}, provided-interface=Ary1D_u13p3_8_CalPortIf1
      FordHwTqCmdOvrlLimrCombdTqSatnY: parameter-provide-com-spec{init-value=8 x 0, parameter=Ary1D_u13p3_8_CalPortIf1/Ary1D}, provided-interface=Ary1D_u13p3_8_CalPortIf1
      FordHwTqCmdOvrlLimrCombdVehSpdBreakPtX: parameter-provide-com-spec{init-value=[0, 15, 60, 100, 150, 180, 200, 250], parameter=Ary1D_u16_8_CalPortIf1/Ary1D}, provided-interface=Ary1D_u16_8_CalPortIf1
      FordHwTqCmdOvrlLimrDftSpdRate: parameter-provide-com-spec{init-value=40, parameter=float32_CalPortIf1/Val}, provided-interface=float32_CalPortIf1
      FordHwTqCmdOvrlLimrDftSpdRcvrRate: parameter-provide-com-spec{init-value=40, parameter=float32_CalPortIf1/Val}, provided-interface=float32_CalPortIf1
      FordHwTqCmdOvrlLimrLkaBwY: parameter-provide-com-spec{init-value=8 x 0, parameter=Ary1D_u13p3_8_CalPortIf1/Ary1D}, provided-interface=Ary1D_u13p3_8_CalPortIf1
      FordHwTqCmdOvrlLimrLkaTqRateY: parameter-provide-com-spec{init-value=8 x 40, parameter=Ary1D_u13p3_8_CalPortIf1/Ary1D}, provided-interface=Ary1D_u13p3_8_CalPortIf1
      FordHwTqCmdOvrlLimrLkaTqSatnY: parameter-provide-com-spec{init-value=8 x 0, parameter=Ary1D_u13p3_8_CalPortIf1/Ary1D}, provided-interface=Ary1D_u13p3_8_CalPortIf1
      FordHwTqCmdOvrlLimrVehSpdBreakPtX: parameter-provide-com-spec{init-value=[0, 15, 60, 100, 150, 180, 200, 250], parameter=Ary1D_u16_8_CalPortIf1/Ary1D}, provided-interface=Ary1D_u16_8_CalPortIf1
      FordMotTqCmdOvrlLimrDftSpdRate: parameter-provide-com-spec{init-value=40, parameter=float32_CalPortIf1/Val}, provided-interface=float32_CalPortIf1
      FordMotTqCmdOvrlLimrDftSpdRcvrRate: parameter-provide-com-spec{init-value=40, parameter=float32_CalPortIf1/Val}, provided-interface=float32_CalPortIf1
      FordMotTqCmdOvrlLimrHiFrqMonrActvNiblCtrlDcTqTrendThd: parameter-provide-com-spec{init-value=1, parameter=float32_CalPortIf1/Val}, provided-interface=float32_CalPortIf1
      FordMotTqCmdOvrlLimrHiFrqMonrActvNiblCtrlLoFrqTiThd: parameter-provide-com-spec{init-value=0.1, parameter=float32_CalPortIf1/Val}, provided-interface=float32_CalPortIf1
      FordMotTqCmdOvrlLimrHiFrqMonrActvNiblCtrlMaxMotTq: parameter-provide-com-spec{init-value=5, parameter=float32_CalPortIf1/Val}, provided-interface=float32_CalPortIf1
      FordMotTqCmdOvrlLimrHiFrqMonrLaneDprtrWarnDcTqTrendThd: parameter-provide-com-spec{init-value=1.5, parameter=float32_CalPortIf1/Val}, provided-interface=float32_CalPortIf1
      FordMotTqCmdOvrlLimrHiFrqMonrLaneDprtrWarnLoFrqTiThd: parameter-provide-com-spec{init-value=0.033, parameter=float32_CalPortIf1/Val}, provided-interface=float32_CalPortIf1
      FordMotTqCmdOvrlLimrHiFrqMonrLaneDprtrWarnMaxMotTq: parameter-provide-com-spec{init-value=5.5, parameter=float32_CalPortIf1/Val}, provided-interface=float32_CalPortIf1
      FordMotTqCmdOvrlLimrHiFrqMonrTqTrendAlpha: parameter-provide-com-spec{init-value=1, parameter=float32_CalPortIf1/Val}, provided-interface=float32_CalPortIf1
      FordMotTqCmdOvrlLimrHiFrqMonrZeroBandTq: parameter-provide-com-spec{init-value=1, parameter=float32_CalPortIf1/Val}, provided-interface=float32_CalPortIf1
      FordMotTqCmdOvrlLimrHwVelLoPassFrq: parameter-provide-com-spec{init-value=0, parameter=float32_CalPortIf1/Val}, provided-interface=float32_CalPortIf1
      FordMotTqCmdOvrlLimrLatCtrlBwY: parameter-provide-com-spec{init-value=8 x 0, parameter=Ary1D_s5p10_8_CalPortIf1/Ary1D}, provided-interface=Ary1D_s5p10_8_CalPortIf1
      FordMotTqCmdOvrlLimrLatCtrlTqRateY: parameter-provide-com-spec{init-value=8 x 5, parameter=Ary1D_s16_8_CalPortIf1/Ary1D}, provided-interface=Ary1D_s16_8_CalPortIf1
      FordMotTqCmdOvrlLimrLatCtrlTqSatnY: parameter-provide-com-spec{init-value=8 x 0, parameter=Ary1D_s16_8_CalPortIf1/Ary1D}, provided-interface=Ary1D_s16_8_CalPortIf1
      FordMotTqCmdOvrlLimrLatCtrlVehSpdBreakPtX: parameter-provide-com-spec{init-value=[0, 1920, 7680, 12800, 19200, 23040, 25600, 32000], parameter=Ary1D_u9p7_8_CalPortIf1/Ary1D}, provided-interface=Ary1D_u9p7_8_CalPortIf1
      FordMotTqCmdOvrlLimrPullDriftCmpTqRateY: parameter-provide-com-spec{init-value=8 x 1, parameter=Ary1D_s16_8_CalPortIf1/Ary1D}, provided-interface=Ary1D_s16_8_CalPortIf1
      FordMotTqCmdOvrlLimrPullDriftCmpTqSatnY: parameter-provide-com-spec{init-value=8 x 3, parameter=Ary1D_s16_8_CalPortIf1/Ary1D}, provided-interface=Ary1D_s16_8_CalPortIf1
      FordMotTqCmdOvrlLimrPullDriftCmpVehSpdBreakPtX: parameter-provide-com-spec{init-value=[0, 15, 60, 100, 150, 180, 200, 250], parameter=Ary1D_u16_8_CalPortIf1/Ary1D}, provided-interface=Ary1D_u16_8_CalPortIf1
      FordMotTqCmdOvrlLimrSteerReactnLimrCombAmpVehSpdLimX: parameter-provide-com-spec{init-value=8 x 0, parameter=Ary1D_u16_8_CalPortIf1/Ary1D}, provided-interface=Ary1D_u16_8_CalPortIf1
      FordMotTqCmdOvrlLimrSteerReactnLimrCombAmpVehSpdLimY: parameter-provide-com-spec{init-value=[0, 15, 40, 70, 100, 150, 200, 250], parameter=Ary1D_u16_8_CalPortIf1/Ary1D}, provided-interface=Ary1D_u16_8_CalPortIf1
      FordMotTqCmdOvrlLimrSteerReactnLimrCombOvrrunRampRateHwVelErrX: parameter-provide-com-spec{init-value=[0, 25, 50, 100, 170, 250], parameter=Ary1D_u16_6_CalPortIf1/Ary1D}, provided-interface=Ary1D_u16_6_CalPortIf1
      FordMotTqCmdOvrlLimrSteerReactnLimrCombOvrrunRampRateOutY: parameter-provide-com-spec{init-value=[0, 35, 70, 130, 300, 600], parameter=Ary1D_u16_6_CalPortIf1/Ary1D}, provided-interface=Ary1D_u16_6_CalPortIf1
      FordMotTqCmdOvrlLimrSteerReactnLimrCombdAmpOvrrun: parameter-provide-com-spec{init-value=0, parameter=float32_CalPortIf1/Val}, provided-interface=float32_CalPortIf1
      FordMotTqCmdOvrlLimrSteerReactnLimrCombdAmpRcvry: parameter-provide-com-spec{init-value=0.5, parameter=float32_CalPortIf1/Val}, provided-interface=float32_CalPortIf1
      FordMotTqCmdOvrlLimrSteerReactnLimrCombdFixdOvrrunRampRate: parameter-provide-com-spec{init-value=8, parameter=float32_CalPortIf1/Val}, provided-interface=float32_CalPortIf1
      FordMotTqCmdOvrlLimrSteerReactnLimrCombdLimHys: parameter-provide-com-spec{init-value=0.05, parameter=float32_CalPortIf1/Val}, provided-interface=float32_CalPortIf1
      FordMotTqCmdOvrlLimrSteerReactnLimrCombdLimTqX: parameter-provide-com-spec{init-value=8 x [-6, -5, -4, -2, 0, 2, 4, 5, 6], parameter=Ary2D_s16_8_9_CalPortIf1/Ary2D}, provided-interface=Ary2D_s16_8_9_CalPortIf1
      FordMotTqCmdOvrlLimrSteerReactnLimrCombdLimrHwVelY: parameter-provide-com-spec{init-value=[[-20, 10, 20, 30, 80, 100, 100, 100, 100], [-20, 10, 20, 30, 80, 100, 100, 100, 100], [-20, 10, 20, 20, 80, 100, 100, 100, 100], [-20, 10, 20, 20, 80, 100, 100, 100, 100], [-40, 5, 10, 15, 60, 80, 80, 80, 80], [-40, 0, 5, 10, 30, 40, 40, 40, 40], [-40, 0, 5, 10, 20, 30, 30, 30, 30], [-40, 0, 5, 10, 20, 30, 30, 30, 30]], parameter=Ary2D_s16_8_9_CalPortIf1/Ary2D}, provided-interface=Ary2D_s16_8_9_CalPortIf1
      FordMotTqCmdOvrlLimrSteerReactnLimrCombdLimrVehSpd: parameter-provide-com-spec{init-value=[0, 15, 40, 70, 100, 150, 200, 250], parameter=Ary1D_u16_8_CalPortIf1/Ary1D}, provided-interface=Ary1D_u16_8_CalPortIf1
      FordMotTqCmdOvrlLimrSteerReactnLimrCombdRcvryIdealRampRate: parameter-provide-com-spec{init-value=0, parameter=float32_CalPortIf1/Val}, provided-interface=float32_CalPortIf1
      FordMotTqCmdOvrlLimrSteerReactnLimrCombdRcvryRampRateStg1: parameter-provide-com-spec{init-value=20, parameter=float32_CalPortIf1/Val}, provided-interface=float32_CalPortIf1
      FordMotTqCmdOvrlLimrSteerReactnLimrCombdRcvryRampRateStg2: parameter-provide-com-spec{init-value=40, parameter=float32_CalPortIf1/Val}, provided-interface=float32_CalPortIf1
      FordCmdArbnActvNiblCtrlDeactvn: parameter-provide-com-spec{init-value=[1, 1, 1, 1, 1, 1, 1, 1, 1, 0, 0, 0, 0], parameter=Ary1D_logl_13_CalPortIf1/Ary1D}, provided-interface=Ary1D_logl_13_CalPortIf1
      FordCmdArbnActvNiblCtrlDeniedActvnReq: parameter-provide-com-spec{init-value=[1, 1, 1, 1, 1, 1, 1, 1, 1, 0, 0, 0, 0], parameter=Ary1D_logl_13_CalPortIf1/Ary1D}, provided-interface=Ary1D_logl_13_CalPortIf1
      FordCmdArbnDrvrSteerDeniedActvnReq: parameter-provide-com-spec{init-value=[0, 0, 0, 0, 0, 0, 1, 1, 1, 0, 0, 0, 0], parameter=Ary1D_logl_13_CalPortIf1/Ary1D}, provided-interface=Ary1D_logl_13_CalPortIf1
      FordCmdArbnDrvrSteerRcmdnDeactvn: parameter-provide-com-spec{init-value=[1, 1, 1, 1, 1, 1, 1, 1, 1, 0, 0, 0, 0], parameter=Ary1D_logl_13_CalPortIf1/Ary1D}, provided-interface=Ary1D_logl_13_CalPortIf1
      FordCmdArbnEvasSteerAssiDeactvn: parameter-provide-com-spec{init-value=[1, 1, 1, 1, 1, 1, 1, 1, 1, 0, 0, 0, 0], parameter=Ary1D_logl_13_CalPortIf1/Ary1D}, provided-interface=Ary1D_logl_13_CalPortIf1
      FordCmdArbnEvasSteerDeniedActvnReq: parameter-provide-com-spec{init-value=[1, 1, 1, 1, 1, 1, 1, 1, 1, 0, 0, 0, 0], parameter=Ary1D_logl_13_CalPortIf1/Ary1D}, provided-interface=Ary1D_logl_13_CalPortIf1
      FordCmdArbnExtAgCtrlDeactvn: parameter-provide-com-spec{init-value=[1, 1, 1, 1, 1, 1, 1, 1, 1, 1, 0, 0, 0], parameter=Ary1D_logl_13_CalPortIf1/Ary1D}, provided-interface=Ary1D_logl_13_CalPortIf1
      FordCmdArbnExtAgDeniedActvnReq: parameter-provide-com-spec{init-value=[1, 1, 1, 1, 1, 1, 0, 0, 0, 1, 0, 0, 0], parameter=Ary1D_logl_13_CalPortIf1/Ary1D}, provided-interface=Ary1D_logl_13_CalPortIf1
      FordCmdArbnLaneDprtrWarnDeactvn: parameter-provide-com-spec{init-value=[1, 1, 1, 1, 1, 1, 1, 1, 1, 0, 0, 0, 0], parameter=Ary1D_logl_13_CalPortIf1/Ary1D}, provided-interface=Ary1D_logl_13_CalPortIf1
      FordCmdArbnLaneDprtrWarnDeniedActvnReq: parameter-provide-com-spec{init-value=[1, 1, 1, 1, 1, 1, 1, 1, 1, 0, 0, 0, 0], parameter=Ary1D_logl_13_CalPortIf1/Ary1D}, provided-interface=Ary1D_logl_13_CalPortIf1
      FordCmdArbnLaneKeepAssiDeactvn: parameter-provide-com-spec{init-value=[1, 1, 1, 1, 1, 1, 1, 1, 1, 0, 0, 0, 0], parameter=Ary1D_logl_13_CalPortIf1/Ary1D}, provided-interface=Ary1D_logl_13_CalPortIf1
      FordCmdArbnLaneKeepAssiDeniedActvnReq: parameter-provide-com-spec{init-value=[1, 1, 1, 1, 1, 1, 1, 1, 1, 0, 0, 0, 0], parameter=Ary1D_logl_13_CalPortIf1/Ary1D}, provided-interface=Ary1D_logl_13_CalPortIf1
      FordCmdArbnLatCtrlDeactvn: parameter-provide-com-spec{init-value=13 x 0, parameter=Ary1D_logl_13_CalPortIf1/Ary1D}, provided-interface=Ary1D_logl_13_CalPortIf1
      FordCmdArbnLatCtrlDeniedActvnReq: parameter-provide-com-spec{init-value=13 x 0, parameter=Ary1D_logl_13_CalPortIf1/Ary1D}, provided-interface=Ary1D_logl_13_CalPortIf1
      FordCmdArbnNonStMask: parameter-provide-com-spec{init-value=[1, 1, 1, 0, 1, 1, 0, 1, 1, 1, 0, 0, 0], parameter=Ary1D_logl_13_CalPortIf1/Ary1D}, provided-interface=Ary1D_logl_13_CalPortIf1
      FordCmdArbnNormAssiTqThd: parameter-provide-com-spec{init-value=0, parameter=float32_CalPortIf1/Val}, provided-interface=float32_CalPortIf1
      FordCmdArbnPullDriftCmpDeactvn: parameter-provide-com-spec{init-value=[1, 1, 1, 1, 1, 1, 1, 1, 1, 0, 0, 0, 0], parameter=Ary1D_logl_13_CalPortIf1/Ary1D}, provided-interface=Ary1D_logl_13_CalPortIf1
      FordCmdArbnPullDriftCmpDeniedActvnReq: parameter-provide-com-spec{init-value=[1, 1, 1, 1, 1, 1, 1, 1, 1, 0, 0, 0, 0], parameter=Ary1D_logl_13_CalPortIf1/Ary1D}, provided-interface=Ary1D_logl_13_CalPortIf1
      FordCmdArbnPullDriftCmpLrngDeactvn: parameter-provide-com-spec{init-value=[1, 1, 1, 1, 0, 0, 0, 1, 1, 0, 0, 0, 0], parameter=Ary1D_logl_13_CalPortIf1/Ary1D}, provided-interface=Ary1D_logl_13_CalPortIf1
      FordCmdArbnPullDriftCmpLrngDeniedActvnReq: parameter-provide-com-spec{init-value=[1, 1, 1, 1, 0, 0, 0, 1, 1, 0, 0, 0, 0], parameter=Ary1D_logl_13_CalPortIf1/Ary1D}, provided-interface=Ary1D_logl_13_CalPortIf1
      FordCmdArbnSpare1Deactvn: parameter-provide-com-spec{init-value=[1, 1, 1, 1, 1, 1, 1, 1, 1, 0, 0, 0, 0], parameter=Ary1D_logl_13_CalPortIf1/Ary1D}, provided-interface=Ary1D_logl_13_CalPortIf1
      FordCmdArbnSpare1DeniedActvnReq: parameter-provide-com-spec{init-value=[1, 1, 1, 1, 1, 1, 1, 1, 1, 0, 0, 0, 0], parameter=Ary1D_logl_13_CalPortIf1/Ary1D}, provided-interface=Ary1D_logl_13_CalPortIf1
      FordCmdArbnSpare2Deactvn: parameter-provide-com-spec{init-value=[1, 1, 1, 1, 1, 1, 1, 1, 1, 0, 0, 0, 0], parameter=Ary1D_logl_13_CalPortIf1/Ary1D}, provided-interface=Ary1D_logl_13_CalPortIf1
      FordCmdArbnSpare2DeniedActvnReq: parameter-provide-com-spec{init-value=[1, 1, 1, 1, 1, 1, 1, 1, 1, 0, 0, 0, 0], parameter=Ary1D_logl_13_CalPortIf1/Ary1D}, provided-interface=Ary1D_logl_13_CalPortIf1
      FordCmdArbnSpare3Deactvn: parameter-provide-com-spec{init-value=[1, 1, 1, 1, 1, 1, 1, 1, 1, 0, 0, 0, 0], parameter=Ary1D_logl_13_CalPortIf1/Ary1D}, provided-interface=Ary1D_logl_13_CalPortIf1
      FordCmdArbnSpare3DeniedActvnReq: parameter-provide-com-spec{init-value=[1, 1, 1, 1, 1, 1, 1, 1, 1, 0, 0, 0, 0], parameter=Ary1D_logl_13_CalPortIf1/Ary1D}, provided-interface=Ary1D_logl_13_CalPortIf1
      FordCmdArbnSteerDstbcDeactvn: parameter-provide-com-spec{init-value=13 x 0, parameter=Ary1D_logl_13_CalPortIf1/Ary1D}, provided-interface=Ary1D_logl_13_CalPortIf1
      FordCmdArbnSteerDstbcDeniedActvnReq: parameter-provide-com-spec{init-value=13 x 0, parameter=Ary1D_logl_13_CalPortIf1/Ary1D}, provided-interface=Ary1D_logl_13_CalPortIf1
      NormLimpHomeScar: parameter-provide-com-spec{init-value=0, parameter=float32_CalPortIf1/Val}, provided-interface=float32_CalPortIf1
      InitLimpHomeScar: parameter-provide-com-spec{init-value=0, parameter=float32_CalPortIf1/Val}, provided-interface=float32_CalPortIf1
      LimdAssiScar: parameter-provide-com-spec{init-value=0, parameter=float32_CalPortIf1/Val}, provided-interface=float32_CalPortIf1
      LimdAssiRamp: parameter-provide-com-spec{init-value=1, parameter=float32_CalPortIf1/Val}, provided-interface=float32_CalPortIf1
      NormLimpHomeRamp: parameter-provide-com-spec{init-value=1, parameter=float32_CalPortIf1/Val}, provided-interface=float32_CalPortIf1
      InitLimpHomeRamp: parameter-provide-com-spec{init-value=1, parameter=float32_CalPortIf1/Val}, provided-interface=float32_CalPortIf1
      LimdAssiRampUpRate: parameter-provide-com-spec{init-value=1, parameter=float32_CalPortIf1/Val}, provided-interface=float32_CalPortIf1
      LimdAssiRampUpRateFaild: parameter-provide-com-spec{init-value=1, parameter=float32_CalPortIf1/Val}, provided-interface=float32_CalPortIf1
      FullAssiRampUpRate: parameter-provide-com-spec{init-value=1, parameter=float32_CalPortIf1/Val}, provided-interface=float32_CalPortIf1
      ShtdwnRamp: parameter-provide-com-spec{init-value=1, parameter=float32_CalPortIf1/Val}, provided-interface=float32_CalPortIf1
      FordCanDtcInhbFactryModThd: parameter-provide-com-spec{init-value=0, parameter=u16p0_CalPortIf1/Val}, provided-interface=u16p0_CalPortIf1
      FordCanDtcInhbTransptModThd: parameter-provide-com-spec{init-value=0, parameter=u16p0_CalPortIf1/Val}, provided-interface=u16p0_CalPortIf1
      FordVehSpdArbnDrvnWhl: parameter-provide-com-spec{init-value=0, parameter=Logl}, provided-interface=boolean_CalPortIf1
      FordVehSpdArbnTireCircumMax: parameter-provide-com-spec{init-value=2500, parameter=uint16_CalPortIf1/Val}, provided-interface=uint16_CalPortIf1
      FordVehSpdArbnTireCircumMin: parameter-provide-com-spec{init-value=1500, parameter=uint16_CalPortIf1/Val}, provided-interface=uint16_CalPortIf1
      FordVltgIfActvParkAssiAsscTqMin: parameter-provide-com-spec{init-value=0, parameter=float32_CalPortIf1/Val}, provided-interface=float32_CalPortIf1
      FordVltgIfEpsBattCurrLim: parameter-provide-com-spec{init-value=0, parameter=float32_CalPortIf1/Val}, provided-interface=float32_CalPortIf1
      FordVltgIfEpsCurrLim: parameter-provide-com-spec{init-value=40, parameter=float32_CalPortIf1/Val}, provided-interface=float32_CalPortIf1
      FordVltgIfEvasSteerAssiTqMin: parameter-provide-com-spec{init-value=90, parameter=float32_CalPortIf1/Val}, provided-interface=float32_CalPortIf1
      FordVltgIfFeatThdStsTiThd: parameter-provide-com-spec{init-value=1000, parameter=uint16_CalPortIf1/Val}, provided-interface=uint16_CalPortIf1
      FordVltgIfHiVltgAssiRampDwnRate: parameter-provide-com-spec{init-value=50, parameter=float32_CalPortIf1/Val}, provided-interface=float32_CalPortIf1
      FordVltgIfHiVltgAssiRampUpRate: parameter-provide-com-spec{init-value=50, parameter=float32_CalPortIf1/Val}, provided-interface=float32_CalPortIf1
      FordVltgIfHiVltgInhbTiMax: parameter-provide-com-spec{init-value=100, parameter=uint16_CalPortIf1/Val}, provided-interface=uint16_CalPortIf1
      FordVltgIfHiVltgNoAssiRampDwnRate: parameter-provide-com-spec{init-value=50, parameter=float32_CalPortIf1/Val}, provided-interface=float32_CalPortIf1
      FordVltgIfHiVltgNoAssiRcvrTiMax: parameter-provide-com-spec{init-value=2000, parameter=uint32_CalPortIf1/Val}, provided-interface=uint32_CalPortIf1
      FordVltgIfHiVltgRcvrTiMax: parameter-provide-com-spec{init-value=500, parameter=uint32_CalPortIf1/Val}, provided-interface=uint32_CalPortIf1
      FordVltgIfEPSBattVltgDifThd: parameter-provide-com-spec{init-value=5, parameter=float32_CalPortIf1/Val}, provided-interface=float32_CalPortIf1
      FordVltgIfHiVltgThdHi: parameter-provide-com-spec{init-value=19, parameter=float32_CalPortIf1/Val}, provided-interface=float32_CalPortIf1
      FordVltgIfHiVltgThdLo: parameter-provide-com-spec{init-value=18, parameter=float32_CalPortIf1/Val}, provided-interface=float32_CalPortIf1
      FordVltgIfInhbBattVltgDiagcTiThd: parameter-provide-com-spec{init-value=1000, parameter=uint16_CalPortIf1/Val}, provided-interface=uint16_CalPortIf1
      FordVltgIfLaneCentrAssiTqMin: parameter-provide-com-spec{init-value=90, parameter=float32_CalPortIf1/Val}, provided-interface=float32_CalPortIf1
      FordVltgIfLaneDprtrWarnAsscTqMin: parameter-provide-com-spec{init-value=90, parameter=float32_CalPortIf1/Val}, provided-interface=float32_CalPortIf1
      FordVltgIfLkaAsscTqMin: parameter-provide-com-spec{init-value=90, parameter=float32_CalPortIf1/Val}, provided-interface=float32_CalPortIf1
      FordVltgIfLoVltgAssiRampDwnRate: parameter-provide-com-spec{init-value=50, parameter=float32_CalPortIf1/Val}, provided-interface=float32_CalPortIf1
      FordVltgIfLoVltgAssiRampUpRate: parameter-provide-com-spec{init-value=50, parameter=float32_CalPortIf1/Val}, provided-interface=float32_CalPortIf1
      FordVltgIfLoVltgAssiScar: parameter-provide-com-spec{init-value=0.4, parameter=float32_CalPortIf1/Val}, provided-interface=float32_CalPortIf1
      FordVltgIfLoVltgInhbTiMax: parameter-provide-com-spec{init-value=100, parameter=uint32_CalPortIf1/Val}, provided-interface=uint32_CalPortIf1
      FordVltgIfLoVltgNoAssiRampDwnRate: parameter-provide-com-spec{init-value=50, parameter=float32_CalPortIf1/Val}, provided-interface=float32_CalPortIf1
      FordVltgIfLoVltgNoAssiRcvrTiMax: parameter-provide-com-spec{init-value=2000, parameter=uint16_CalPortIf1/Val}, provided-interface=uint16_CalPortIf1
      FordVltgIfLoVltgRcvrTiMax: parameter-provide-com-spec{init-value=500, parameter=uint32_CalPortIf1/Val}, provided-interface=uint32_CalPortIf1
      FordVltgIfLoVltgThdHi: parameter-provide-com-spec{init-value=11, parameter=float32_CalPortIf1/Val}, provided-interface=float32_CalPortIf1
      FordVltgIfLoVltgThdLo: parameter-provide-com-spec{init-value=7, parameter=float32_CalPortIf1/Val}, provided-interface=float32_CalPortIf1
      FordVltgIfLoVltgThdMid: parameter-provide-com-spec{init-value=10, parameter=float32_CalPortIf1/Val}, provided-interface=float32_CalPortIf1
      FordVltgIfLoVltgThdMidToLoTiMax: parameter-provide-com-spec{init-value=1000, parameter=uint32_CalPortIf1/Val}, provided-interface=uint32_CalPortIf1
      FordVltgIfLoVltgTqScaDwnRate: parameter-provide-com-spec{init-value=50, parameter=float32_CalPortIf1/Val}, provided-interface=float32_CalPortIf1
      FordVltgIfLoVltgTqScaUpRate: parameter-provide-com-spec{init-value=50, parameter=float32_CalPortIf1/Val}, provided-interface=float32_CalPortIf1
      FordVltgIfLoVltgTqScagFac: parameter-provide-com-spec{init-value=0.25, parameter=float32_CalPortIf1/Val}, provided-interface=float32_CalPortIf1
      FordVltgIfTrfcJamAsscTqMin: parameter-provide-com-spec{init-value=90, parameter=float32_CalPortIf1/Val}, provided-interface=float32_CalPortIf1
      FordVltgIfTrlrBackupAssiTqMin: parameter-provide-com-spec{init-value=90, parameter=float32_CalPortIf1/Val}, provided-interface=float32_CalPortIf1
      FordVltgIfVehBattCircR: parameter-provide-com-spec{init-value=0.1, parameter=float32_CalPortIf1/Val}, provided-interface=float32_CalPortIf1
  parameter sw component type CalRegn02CmnGroupA
    provide port AssiThermScaX: parameter-provide-com-spec{init-value=[75, 100], parameter=Ary1D_u16p0_2_CalPortIf1/Ary1D}, provided-interface=Ary1D_u16p0_2_CalPortIf1
    provide port AssiThermScaY: parameter-provide-com-spec{init-value=[16384, 13107], parameter=Ary1D_u2p14_2_CalPortIf1/Ary1D}, provided-interface=Ary1D_u2p14_2_CalPortIf1
  parameter sw component type CalRegn02CmnGroupB
    5 x provide port:
      EotProtnFwlEotDampgActvBndX: parameter-provide-com-spec{init-value=[-11200, -80, 160, 800, 11200], parameter=Ary1D_s11p4_5_CalPortIf1/Ary1D}, provided-interface=Ary1D_s11p4_5_CalPortIf1
      EotProtnFwlInactvLim: parameter-provide-com-spec{init-value=0.1, parameter=float32_CalPortIf1/Val}, provided-interface=float32_CalPortIf1
      EotProtnFwlVehSpd: parameter-provide-com-spec{init-value=[0, 2560, 5120, 7680], parameter=Ary1D_u9p7_4_CalPortIf1/Ary1D}, provided-interface=Ary1D_u9p7_4_CalPortIf1
      EotProtnActvRegnBypMaxThd: parameter-provide-com-spec{init-value=0.5, parameter=float32_CalPortIf1/Val}, provided-interface=float32_CalPortIf1
      EotLrngHwAgOverTrvlCntThd: parameter-provide-com-spec{init-value=5, parameter=uint8_CalPortIf1/Val}, provided-interface=uint8_CalPortIf1
package /Nexteer/Calibrations
  142 x parameter interface:
    Ary1D_f32_3_CalPortIf1
      parameter data prototype Ary1D: sw-calibration-access=READ-WRITE, type=Ary1D_f32_3
    uint8_CalPortIf1
      parameter data prototype Val: sw-calibration-access=READ-WRITE, type=uint8
    float32_CalPortIf1
      parameter data prototype Val: sw-calibration-access=READ-WRITE, type=float32
    Ary1D_u9p7_12_CalPortIf1
      parameter data prototype Ary1D: sw-calibration-access=READ-WRITE, type=Ary1D_u9p7_12
    boolean_CalPortIf1
      parameter data prototype Logl: sw-calibration-access=READ-WRITE, type=boolean
    Ary1D_u10p6_10_CalPortIf1
      parameter data prototype Ary1D: sw-calibration-access=READ-WRITE, type=Ary1D_u10p6_10
    uint16_CalPortIf1
      parameter data prototype Val: sw-calibration-access=READ-WRITE, type=uint16
    Ary1D_u9p7_10_CalPortIf1
      parameter data prototype Ary1D: sw-calibration-access=READ-WRITE, type=Ary1D_u9p7_10
    u2p14_CalPortIf1
      parameter data prototype Val: sw-calibration-access=READ-WRITE, type=u2p14
    Ary1D_u9p7_4_CalPortIf1
      parameter data prototype Ary1D: sw-calibration-access=READ-WRITE, type=Ary1D_u9p7_4
    Ary1D_u1p15_6_CalPortIf1
      parameter data prototype Ary1D: sw-calibration-access=READ-WRITE, type=Ary1D_u1p15_6
    Ary1D_u5p11_6_CalPortIf1
      parameter data prototype Ary1D: sw-calibration-access=READ-WRITE, type=Ary1D_u5p11_6
    Ary1D_u8p8_6_CalPortIf1
      parameter data prototype Ary1D: sw-calibration-access=READ-WRITE, type=Ary1D_u8p8_6
    Ary1D_u9p7_2_CalPortIf1
      parameter data prototype Ary1D: sw-calibration-access=READ-WRITE, type=Ary1D_u9p7_2
    Ary1D_u13p3_2_CalPortIf1
      parameter data prototype Ary1D: sw-calibration-access=READ-WRITE, type=Ary1D_u13p3_2
    Ary1D_f32_4_CalPortIf1
      parameter data prototype Ary1D: sw-calibration-access=READ-WRITE, type=Ary1D_f32_4
    Ary2D_f32_8_4_CalPortIf1
      parameter data prototype Ary2D: sw-calibration-access=READ-WRITE, type=Ary2D_f32_8_4
    Ary2D_u16_8_3_CalPortIf1
      parameter data prototype Ary2D: sw-calibration-access=READ-WRITE, type=Ary2D_u16_8_3
    Ary1D_u11p5_10_CalPortIf1
      parameter data prototype Ary1D: sw-calibration-access=READ-WRITE, type=Ary1D_u11p5_10
    Ary1D_u6p10_10_CalPortIf1
      parameter data prototype Ary1D: sw-calibration-access=READ-WRITE, type=Ary1D_u6p10_10
    Ary1D_logl_4_CalPortIf1
      parameter data prototype Ary1D: sw-calibration-access=READ-WRITE, type=Ary1D_logl_4
    uint32_CalPortIf1
      parameter data prototype Val: sw-calibration-access=READ-WRITE, type=uint32
    Ary2D_f32_4_2_CalPortIf1
      parameter data prototype Ary2D: sw-calibration-access=READ-WRITE, type=Ary2D_f32_4_2
    Ary1D_logl_3_CalPortIf1
      parameter data prototype Ary1D: sw-calibration-access=READ-WRITE, type=Ary1D_logl_3
    Ary1D_u10p6_2_CalPortIf1
      parameter data prototype Ary1D: sw-calibration-access=READ-WRITE, type=Ary1D_u10p6_2
    Ary1D_u11p5_8_CalPortIf1
      parameter data prototype Ary1D: sw-calibration-access=READ-WRITE, type=Ary1D_u11p5_8
    Ary1D_u10p6_8_CalPortIf1
      parameter data prototype Ary1D: sw-calibration-access=READ-WRITE, type=Ary1D_u10p6_8
    Ary1D_u08_22_CalPortIf1
      parameter data prototype Ary1D: sw-calibration-access=READ-WRITE, type=Ary1D_u08_22
    Ary1D_s16_22_CalPortIf1
      parameter data prototype Ary1D: sw-calibration-access=READ-WRITE, type=Ary1D_s16_22
    Ary1D_u9p7_6_CalPortIf1
      parameter data prototype Ary1D: sw-calibration-access=READ-WRITE, type=Ary1D_u9p7_6
    Ary1D_s8p7_14_CalPortIf1
      parameter data prototype Ary1D: sw-calibration-access=READ-WRITE, type=Ary1D_s8p7_14
    Ary1D_u4p12_14_CalPortIf1
      parameter data prototype Ary1D: sw-calibration-access=READ-WRITE, type=Ary1D_u4p12_14
    Ary1D_u8p8_10_CalPortIf1
      parameter data prototype Ary1D: sw-calibration-access=READ-WRITE, type=Ary1D_u8p8_10
    Ary1D_u2p14_10_CalPortIf1
      parameter data prototype Ary1D: sw-calibration-access=READ-WRITE, type=Ary1D_u2p14_10
    Ary1D_u12p4_12_CalPortIf1
      parameter data prototype Ary1D: sw-calibration-access=READ-WRITE, type=Ary1D_u12p4_12
    Ary1D_u8p8_12_CalPortIf1
      parameter data prototype Ary1D: sw-calibration-access=READ-WRITE, type=Ary1D_u8p8_12
    Ary1D_s8p7_12_CalPortIf1
      parameter data prototype Ary1D: sw-calibration-access=READ-WRITE, type=Ary1D_s8p7_12
    Ary1D_s4p11_12_CalPortIf1
      parameter data prototype Ary1D: sw-calibration-access=READ-WRITE, type=Ary1D_s4p11_12
    Ary1D_u11p5_12_CalPortIf1
      parameter data prototype Ary1D: sw-calibration-access=READ-WRITE, type=Ary1D_u11p5_12
    Ary1D_u15p1_12_CalPortIf1
      parameter data prototype Ary1D: sw-calibration-access=READ-WRITE, type=Ary1D_u15p1_12
    Ary1D_u2p14_2_CalPortIf1
      parameter data prototype Ary1D: sw-calibration-access=READ-WRITE, type=Ary1D_u2p14_2
    FilNotchGainRec1_CalPortIf1
      parameter data prototype Rec: sw-calibration-access=READ-WRITE, type=FilNotchGainRec1
    Ary2D_u2p14_6_5_CalPortIf1
      parameter data prototype Ary2D: sw-calibration-access=READ-WRITE, type=Ary2D_u2p14_6_5
    Ary2D_u8p8_6_5_CalPortIf1
      parameter data prototype Ary2D: sw-calibration-access=READ-WRITE, type=Ary2D_u8p8_6_5
    Ary1D_u10p6_4_CalPortIf1
      parameter data prototype Ary1D: sw-calibration-access=READ-WRITE, type=Ary1D_u10p6_4
    Ary1D_u11p5_4_CalPortIf1
      parameter data prototype Ary1D: sw-calibration-access=READ-WRITE, type=Ary1D_u11p5_4
    Ary1D_u4p12_11_CalPortIf1
      parameter data prototype Ary1D: sw-calibration-access=READ-WRITE, type=Ary1D_u4p12_11
    Ary1D_u1p15_11_CalPortIf1
      parameter data prototype Ary1D: sw-calibration-access=READ-WRITE, type=Ary1D_u1p15_11
    Ary1D_f32_8_CalPortIf1
      parameter data prototype Ary1D: sw-calibration-access=READ-WRITE, type=Ary1D_f32_8
    Ary1D_u3p13_10_CalPortIf1
      parameter data prototype Ary1D: sw-calibration-access=READ-WRITE, type=Ary1D_u3p13_10
    Ary1D_u9p7_16_CalPortIf1
      parameter data prototype Ary1D: sw-calibration-access=READ-WRITE, type=Ary1D_u9p7_16
    Ary1D_u2p14_16_CalPortIf1
      parameter data prototype Ary1D: sw-calibration-access=READ-WRITE, type=Ary1D_u2p14_16
    Ary1D_u9p7_7_CalPortIf1
      parameter data prototype Ary1D: sw-calibration-access=READ-WRITE, type=Ary1D_u9p7_7
    Ary2D_u2p14_6_7_CalPortIf1
      parameter data prototype Ary2D: sw-calibration-access=READ-WRITE, type=Ary2D_u2p14_6_7
    s18p13_CalPortIf1
      parameter data prototype Val: sw-calibration-access=READ-WRITE, type=s18p13
    u16p0_CalPortIf1
      parameter data prototype Val: sw-calibration-access=READ-WRITE, type=u16p0
    Ary2D_f32_5_5_CalPortIf1
      parameter data prototype Ary2D: sw-calibration-access=READ-WRITE, type=Ary2D_f32_5_5
    Ary2D_f32_5_4_CalPortIf1
      parameter data prototype Ary2D: sw-calibration-access=READ-WRITE, type=Ary2D_f32_5_4
    Ary1D_f32_5_CalPortIf1
      parameter data prototype Ary1D: sw-calibration-access=READ-WRITE, type=Ary1D_f32_5
    Ary1D_u2p14_4_CalPortIf1
      parameter data prototype Ary1D: sw-calibration-access=READ-WRITE, type=Ary1D_u2p14_4
    Ary1D_u4p12_8_CalPortIf1
      parameter data prototype Ary1D: sw-calibration-access=READ-WRITE, type=Ary1D_u4p12_8
    Ary2D_u1p15_8_4_CalPortIf1
      parameter data prototype Ary2D: sw-calibration-access=READ-WRITE, type=Ary2D_u1p15_8_4
    Ary1D_u10p6_5_CalPortIf1
      parameter data prototype Ary1D: sw-calibration-access=READ-WRITE, type=Ary1D_u10p6_5
    Ary1D_u1p15_5_CalPortIf1
      parameter data prototype Ary1D: sw-calibration-access=READ-WRITE, type=Ary1D_u1p15_5
    Ary1D_s11p4_14_CalPortIf1
      parameter data prototype Ary1D: sw-calibration-access=READ-WRITE, type=Ary1D_s11p4_14
    Ary1D_u5p11_14_CalPortIf1
      parameter data prototype Ary1D: sw-calibration-access=READ-WRITE, type=Ary1D_u5p11_14
    Ary1D_u11p5_6_CalPortIf1
      parameter data prototype Ary1D: sw-calibration-access=READ-WRITE, type=Ary1D_u11p5_6
    Ary1D_u4p12_6_CalPortIf1
      parameter data prototype Ary1D: sw-calibration-access=READ-WRITE, type=Ary1D_u4p12_6
    Ary1D_u5p11_10_CalPortIf1
      parameter data prototype Ary1D: sw-calibration-access=READ-WRITE, type=Ary1D_u5p11_10
    Ary1D_u9p7_5_CalPortIf1
      parameter data prototype Ary1D: sw-calibration-access=READ-WRITE, type=Ary1D_u9p7_5
    Ary1D_u5p11_5_CalPortIf1
      parameter data prototype Ary1D: sw-calibration-access=READ-WRITE, type=Ary1D_u5p11_5
    Ary1D_s15p0_4_CalPortIf1
      parameter data prototype Ary1D: sw-calibration-access=READ-WRITE, type=Ary1D_s15p0_4
    Ary2D_u9p7_2_5_CalPortIf1
      parameter data prototype Ary2D: sw-calibration-access=READ-WRITE, type=Ary2D_u9p7_2_5
    Ary1D_u3p13_5_CalPortIf1
      parameter data prototype Ary1D: sw-calibration-access=READ-WRITE, type=Ary1D_u3p13_5
    Ary1D_s15p0_5_CalPortIf1
      parameter data prototype Ary1D: sw-calibration-access=READ-WRITE, type=Ary1D_s15p0_5
    Ary2D_u16p0_2_8_CalPortIf1
      parameter data prototype Ary2D: sw-calibration-access=READ-WRITE, type=Ary2D_u16p0_2_8
    Ary2D_u9p7_2_8_CalPortIf1
      parameter data prototype Ary2D: sw-calibration-access=READ-WRITE, type=Ary2D_u9p7_2_8
    Ary1D_u08_6_CalPortIf1
      parameter data prototype Ary1D: sw-calibration-access=READ-WRITE, type=Ary1D_u08_6
    Ary1D_u08_48_CalPortIf1
      parameter data prototype Ary1D: sw-calibration-access=READ-WRITE, type=Ary1D_u08_48
    u0p16_CalPortIf1
      parameter data prototype Val: sw-calibration-access=READ-WRITE, type=u0p16
    Ary1D_u16_512_CalPortIf1
      parameter data prototype Ary1D: sw-calibration-access=READ-WRITE, type=Ary1D_u16_512
    Ary1D_u6p10_6_CalPortIf1
      parameter data prototype Ary1D: sw-calibration-access=READ-WRITE, type=Ary1D_u6p10_6
    Ary2D_u3p13_12_13_CalPortIf1
      parameter data prototype Ary2D: sw-calibration-access=READ-WRITE, type=Ary2D_u3p13_12_13
    Ary1D_u7p9_12_CalPortIf1
      parameter data prototype Ary1D: sw-calibration-access=READ-WRITE, type=Ary1D_u7p9_12
    Ary2D_u5p11_12_13_CalPortIf1
      parameter data prototype Ary2D: sw-calibration-access=READ-WRITE, type=Ary2D_u5p11_12_13
    Ary2D_u4p12_12_5_CalPortIf1
      parameter data prototype Ary2D: sw-calibration-access=READ-WRITE, type=Ary2D_u4p12_12_5
    Ary2D_u1p15_12_5_CalPortIf1
      parameter data prototype Ary2D: sw-calibration-access=READ-WRITE, type=Ary2D_u1p15_12_5
    Ary1D_u0p16_10_CalPortIf1
      parameter data prototype Ary1D: sw-calibration-access=READ-WRITE, type=Ary1D_u0p16_10
    Ary1D_u1p15_12_CalPortIf1
      parameter data prototype Ary1D: sw-calibration-access=READ-WRITE, type=Ary1D_u1p15_12
    Ary1D_u4p12_5_CalPortIf1
      parameter data prototype Ary1D: sw-calibration-access=READ-WRITE, type=Ary1D_u4p12_5
    Ary1D_u4p12_12_CalPortIf1
      parameter data prototype Ary1D: sw-calibration-access=READ-WRITE, type=Ary1D_u4p12_12
    Ary1D_u2p14_6_CalPortIf1
      parameter data prototype Ary1D: sw-calibration-access=READ-WRITE, type=Ary1D_u2p14_6
    Ary2D_u4p12_12_8_CalPortIf1
      parameter data prototype Ary2D: sw-calibration-access=READ-WRITE, type=Ary2D_u4p12_12_8
    Ary1D_u2p14_5_CalPortIf1
      parameter data prototype Ary1D: sw-calibration-access=READ-WRITE, type=Ary1D_u2p14_5
    Ary1D_u8p8_8_CalPortIf1
      parameter data prototype Ary1D: sw-calibration-access=READ-WRITE, type=Ary1D_u8p8_8
    Ary1D_u9p7_8_CalPortIf1
      parameter data prototype Ary1D: sw-calibration-access=READ-WRITE, type=Ary1D_u9p7_8
    Ary1D_u8p8_2_CalPortIf1
      parameter data prototype Ary1D: sw-calibration-access=READ-WRITE, type=Ary1D_u8p8_2
    Ary1D_u1p15_2_CalPortIf1
      parameter data prototype Ary1D: sw-calibration-access=READ-WRITE, type=Ary1D_u1p15_2
    Ary2D_u12p4_12_13_CalPortIf1
      parameter data prototype Ary2D: sw-calibration-access=READ-WRITE, type=Ary2D_u12p4_12_13
    Ary2D_u8p8_12_20_CalPortIf1
      parameter data prototype Ary2D: sw-calibration-access=READ-WRITE, type=Ary2D_u8p8_12_20
    Ary2D_s4p11_12_20_CalPortIf1
      parameter data prototype Ary2D: sw-calibration-access=READ-WRITE, type=Ary2D_s4p11_12_20
    Ary2D_u5p11_12_5_CalPortIf1
      parameter data prototype Ary2D: sw-calibration-access=READ-WRITE, type=Ary2D_u5p11_12_5
    Ary2D_u2p14_12_5_CalPortIf1
      parameter data prototype Ary2D: sw-calibration-access=READ-WRITE, type=Ary2D_u2p14_12_5
    Ary2D_u1p15_5_4_CalPortIf1
      parameter data prototype Ary2D: sw-calibration-access=READ-WRITE, type=Ary2D_u1p15_5_4
    Ary1D_u12p4_2_CalPortIf1
      parameter data prototype Ary1D: sw-calibration-access=READ-WRITE, type=Ary1D_u12p4_2
    Ary2D_u0p16_4_2_CalPortIf1
      parameter data prototype Ary2D: sw-calibration-access=READ-WRITE, type=Ary2D_u0p16_4_2
    Ary2D_u12p4_9_16_CalPortIf1
      parameter data prototype Ary2D: sw-calibration-access=READ-WRITE, type=Ary2D_u12p4_9_16
    Ary2D_u5p11_9_16_CalPortIf1
      parameter data prototype Ary2D: sw-calibration-access=READ-WRITE, type=Ary2D_u5p11_9_16
    Ary2D_u8p8_9_8_CalPortIf1
      parameter data prototype Ary2D: sw-calibration-access=READ-WRITE, type=Ary2D_u8p8_9_8
    Ary2D_u7p9_9_4_CalPortIf1
      parameter data prototype Ary2D: sw-calibration-access=READ-WRITE, type=Ary2D_u7p9_9_4
    Ary2D_u8p8_9_4_CalPortIf1
      parameter data prototype Ary2D: sw-calibration-access=READ-WRITE, type=Ary2D_u8p8_9_4
    Ary1D_u9p7_9_CalPortIf1
      parameter data prototype Ary1D: sw-calibration-access=READ-WRITE, type=Ary1D_u9p7_9
    Ary1D_f32_2_CalPortIf1
      parameter data prototype Ary1D: sw-calibration-access=READ-WRITE, type=Ary1D_f32_2
    Ary1D_u4p12_10_CalPortIf1
      parameter data prototype Ary1D: sw-calibration-access=READ-WRITE, type=Ary1D_u4p12_10
    Ary1D_u2p14_12_CalPortIf1
      parameter data prototype Ary1D: sw-calibration-access=READ-WRITE, type=Ary1D_u2p14_12
    Ary1D_u13p3_6_CalPortIf1
      parameter data prototype Ary1D: sw-calibration-access=READ-WRITE, type=Ary1D_u13p3_6
    Ary1D_u4p12_2_CalPortIf1
      parameter data prototype Ary1D: sw-calibration-access=READ-WRITE, type=Ary1D_u4p12_2
    u9p7_CalPortIf1
      parameter data prototype Val: sw-calibration-access=READ-WRITE, type=u9p7
    Ary1D_s14p1_8_CalPortIf1
      parameter data prototype Ary1D: sw-calibration-access=READ-WRITE, type=Ary1D_s14p1_8
    Ary1D_s11p4_11_CalPortIf1
      parameter data prototype Ary1D: sw-calibration-access=READ-WRITE, type=Ary1D_s11p4_11
    Ary2D_s4p11_8_11_CalPortIf1
      parameter data prototype Ary2D: sw-calibration-access=READ-WRITE, type=Ary2D_s4p11_8_11
    Ary1D_s4p11_4_CalPortIf1
      parameter data prototype Ary1D: sw-calibration-access=READ-WRITE, type=Ary1D_s4p11_4
    Ary2D_s7p8_4_5_CalPortIf1
      parameter data prototype Ary2D: sw-calibration-access=READ-WRITE, type=Ary2D_s7p8_4_5
    Ary2D_u12p4_5_4_CalPortIf1
      parameter data prototype Ary2D: sw-calibration-access=READ-WRITE, type=Ary2D_u12p4_5_4
    Ary2D_u12p4_4_2_CalPortIf1
      parameter data prototype Ary2D: sw-calibration-access=READ-WRITE, type=Ary2D_u12p4_4_2
    Ary1D_u8p8_4_CalPortIf1
      parameter data prototype Ary1D: sw-calibration-access=READ-WRITE, type=Ary1D_u8p8_4
    Ary1D_u8p8_14_CalPortIf1
      parameter data prototype Ary1D: sw-calibration-access=READ-WRITE, type=Ary1D_u8p8_14
    Ary2D_u3p13_20_8_CalPortIf1
      parameter data prototype Ary2D: sw-calibration-access=READ-WRITE, type=Ary2D_u3p13_20_8
    Ary2D_u0p16_20_8_CalPortIf1
      parameter data prototype Ary2D: sw-calibration-access=READ-WRITE, type=Ary2D_u0p16_20_8
    Ary1D_u5p11_8_CalPortIf1
      parameter data prototype Ary1D: sw-calibration-access=READ-WRITE, type=Ary1D_u5p11_8
    Ary2D_s1p14_10_12_CalPortIf1
      parameter data prototype Ary2D: sw-calibration-access=READ-WRITE, type=Ary2D_s1p14_10_12
    Ary1D_u16p0_20_CalPortIf1
      parameter data prototype Ary1D: sw-calibration-access=READ-WRITE, type=Ary1D_u16p0_20
    u8p8_CalPortIf1
      parameter data prototype Val: sw-calibration-access=READ-WRITE, type=u8p8
    Ary1D_u13p3_8_CalPortIf1
      parameter data prototype Ary1D: sw-calibration-access=READ-WRITE, type=Ary1D_u13p3_8
    Ary1D_u16_8_CalPortIf1
      parameter data prototype Ary1D: sw-calibration-access=READ-WRITE, type=Ary1D_u16_8
    Ary1D_s5p10_8_CalPortIf1
      parameter data prototype Ary1D: sw-calibration-access=READ-WRITE, type=Ary1D_s5p10_8
    Ary1D_s16_8_CalPortIf1
      parameter data prototype Ary1D: sw-calibration-access=READ-WRITE, type=Ary1D_s16_8
    Ary1D_u16_6_CalPortIf1
      parameter data prototype Ary1D: sw-calibration-access=READ-WRITE, type=Ary1D_u16_6
    Ary2D_s16_8_9_CalPortIf1
      parameter data prototype Ary2D: sw-calibration-access=READ-WRITE, type=Ary2D_s16_8_9
    Ary1D_logl_13_CalPortIf1
      parameter data prototype Ary1D: sw-calibration-access=READ-WRITE, type=Ary1D_logl_13
    Ary1D_u16p0_2_CalPortIf1
      parameter data prototype Ary1D: sw-calibration-access=READ-WRITE, type=Ary1D_u16p0_2
    Ary1D_s11p4_5_CalPortIf1
      parameter data prototype Ary1D: sw-calibration-access=READ-WRITE, type=Ary1D_s11p4_5
package /Nexteer/ComponentTypes/DataTypeMappingSets
  data type mapping set Cals
package /Nexteer/DataTypes
  177 x impl type:
    Ary1D_f32_3: category=ARRAY, sw-calibration-access=READ-ONLY, type-emitter=RTE
      element Element: array-size=3, array-size-semantics=FIXED-SIZE, implementation-data-type=float32
    u9p7: implementation-data-type=uint16, type-emitter=RTE
    Ary1D_u9p7_12: category=ARRAY, sw-calibration-access=READ-ONLY, type-emitter=RTE
      element Element: array-size=12, array-size-semantics=FIXED-SIZE, implementation-data-type=u9p7
    u10p6: implementation-data-type=uint16, type-emitter=RTE
    Ary1D_u10p6_10: category=ARRAY, sw-calibration-access=READ-ONLY, type-emitter=RTE
      element Element: array-size=10, array-size-semantics=FIXED-SIZE, implementation-data-type=u10p6
    Ary1D_u9p7_10: category=ARRAY, sw-calibration-access=READ-ONLY, type-emitter=RTE
      element Element: array-size=10, array-size-semantics=FIXED-SIZE, implementation-data-type=u9p7
    u2p14: implementation-data-type=uint16, type-emitter=RTE
    Ary1D_u9p7_4: category=ARRAY, sw-calibration-access=READ-ONLY, type-emitter=RTE
      element Element: array-size=4, array-size-semantics=FIXED-SIZE, implementation-data-type=u9p7
    u1p15: implementation-data-type=uint16, type-emitter=RTE
    Ary1D_u1p15_6: category=ARRAY, sw-calibration-access=READ-ONLY, type-emitter=RTE
      element Element: array-size=6, array-size-semantics=FIXED-SIZE, implementation-data-type=u1p15
    u5p11: implementation-data-type=uint16, type-emitter=RTE
    Ary1D_u5p11_6: category=ARRAY, sw-calibration-access=READ-ONLY, type-emitter=RTE
      element Element: array-size=6, array-size-semantics=FIXED-SIZE, implementation-data-type=u5p11
    u8p8: implementation-data-type=uint16, type-emitter=RTE
    Ary1D_u8p8_6: category=ARRAY, sw-calibration-access=READ-ONLY, type-emitter=RTE
      element Element: array-size=6, array-size-semantics=FIXED-SIZE, implementation-data-type=u8p8
    Ary1D_u9p7_2: category=ARRAY, sw-calibration-access=READ-ONLY, type-emitter=RTE
      element Element: array-size=2, array-size-semantics=FIXED-SIZE, implementation-data-type=u9p7
    u13p3: implementation-data-type=uint16, type-emitter=RTE
    Ary1D_u13p3_2: category=ARRAY, sw-calibration-access=READ-ONLY, type-emitter=RTE
      element Element: array-size=2, array-size-semantics=FIXED-SIZE, implementation-data-type=u13p3
    Ary1D_f32_4: category=ARRAY, sw-calibration-access=READ-ONLY, type-emitter=RTE
      element Element: array-size=4, array-size-semantics=FIXED-SIZE, implementation-data-type=float32
    Ary2D_f32_8_4: category=ARRAY, sw-calibration-access=READ-ONLY, type-emitter=RTE
      element Element: array-size=8, array-size-semantics=FIXED-SIZE, implementation-data-type=Ary1D_f32_4
    Ary2D_u16_8_3: category=ARRAY, sw-calibration-access=READ-ONLY, type-emitter=RTE
      element Element: array-size=8, array-size-semantics=FIXED-SIZE, implementation-data-type=Ary1D_u16_3
    Ary1D_u16_3: category=ARRAY, sw-calibration-access=READ-ONLY, type-emitter=RTE
      element Element: array-size=3, array-size-semantics=FIXED-SIZE, implementation-data-type=uint16
    u11p5: implementation-data-type=uint16, type-emitter=RTE
    Ary1D_u11p5_10: category=ARRAY, sw-calibration-access=READ-ONLY, type-emitter=RTE
      element Element: array-size=10, array-size-semantics=FIXED-SIZE, implementation-data-type=u11p5
    u6p10: implementation-data-type=uint16, type-emitter=RTE
    Ary1D_u6p10_10: category=ARRAY, sw-calibration-access=READ-ONLY, type-emitter=RTE
      element Element: array-size=10, array-size-semantics=FIXED-SIZE, implementation-data-type=u6p10
    Ary1D_logl_4: category=ARRAY, sw-calibration-access=READ-ONLY, type-emitter=RTE
      element Element: array-size=4, array-size-semantics=FIXED-SIZE, implementation-data-type=boolean
    Ary2D_f32_4_2: category=ARRAY, sw-calibration-access=READ-ONLY, type-emitter=RTE
      element Element: array-size=4, array-size-semantics=FIXED-SIZE, implementation-data-type=Ary1D_f32_2
    Ary1D_f32_2: category=ARRAY, sw-calibration-access=READ-ONLY, type-emitter=RTE
      element Element: array-size=2, array-size-semantics=FIXED-SIZE, implementation-data-type=float32
    Ary1D_logl_3: category=ARRAY, sw-calibration-access=READ-ONLY, type-emitter=RTE
      element Element: array-size=3, array-size-semantics=FIXED-SIZE, implementation-data-type=boolean
    Ary1D_u10p6_2: category=ARRAY, sw-calibration-access=READ-ONLY, type-emitter=RTE
      element Element: array-size=2, array-size-semantics=FIXED-SIZE, implementation-data-type=u10p6
    Ary1D_u11p5_8: category=ARRAY, sw-calibration-access=READ-ONLY, type-emitter=RTE
      element Element: array-size=8, array-size-semantics=FIXED-SIZE, implementation-data-type=u11p5
    Ary1D_u10p6_8: category=ARRAY, sw-calibration-access=READ-ONLY, type-emitter=RTE
      element Element: array-size=8, array-size-semantics=FIXED-SIZE, implementation-data-type=u10p6
    Ary1D_u08_22: category=ARRAY, sw-calibration-access=READ-ONLY, type-emitter=RTE
      element Element: array-size=22, array-size-semantics=FIXED-SIZE, implementation-data-type=uint8
    Ary1D_s16_22: category=ARRAY, sw-calibration-access=READ-ONLY, type-emitter=RTE
      element Element: array-size=22, array-size-semantics=FIXED-SIZE, implementation-data-type=sint16
    Ary1D_u9p7_6: category=ARRAY, sw-calibration-access=READ-ONLY, type-emitter=RTE
      element Element: array-size=6, array-size-semantics=FIXED-SIZE, implementation-data-type=u9p7
    s8p7: implementation-data-type=sint16, type-emitter=RTE
    Ary1D_s8p7_14: category=ARRAY, sw-calibration-access=READ-ONLY, type-emitter=RTE
      element Element: array-size=14, array-size-semantics=FIXED-SIZE, implementation-data-type=s8p7
    u4p12: implementation-data-type=uint16, type-emitter=RTE
    Ary1D_u4p12_14: category=ARRAY, sw-calibration-access=READ-ONLY, type-emitter=RTE
      element Element: array-size=14, array-size-semantics=FIXED-SIZE, implementation-data-type=u4p12
    Ary1D_u8p8_10: category=ARRAY, sw-calibration-access=READ-ONLY, type-emitter=RTE
      element Element: array-size=10, array-size-semantics=FIXED-SIZE, implementation-data-type=u8p8
    Ary1D_u2p14_10: category=ARRAY, sw-calibration-access=READ-ONLY, type-emitter=RTE
      element Element: array-size=10, array-size-semantics=FIXED-SIZE, implementation-data-type=u2p14
    u12p4: implementation-data-type=uint16, type-emitter=RTE
    Ary1D_u12p4_12: category=ARRAY, sw-calibration-access=READ-ONLY, type-emitter=RTE
      element Element: array-size=12, array-size-semantics=FIXED-SIZE, implementation-data-type=u12p4
    Ary1D_u8p8_12: category=ARRAY, sw-calibration-access=READ-ONLY, type-emitter=RTE
      element Element: array-size=12, array-size-semantics=FIXED-SIZE, implementation-data-type=u8p8
    Ary1D_s8p7_12: category=ARRAY, sw-calibration-access=READ-ONLY, type-emitter=RTE
      element Element: array-size=12, array-size-semantics=FIXED-SIZE, implementation-data-type=s8p7
    s4p11: implementation-data-type=sint16, type-emitter=RTE
    Ary1D_s4p11_12: category=ARRAY, sw-calibration-access=READ-ONLY, type-emitter=RTE
      element Element: array-size=12, array-size-semantics=FIXED-SIZE, implementation-data-type=s4p11
    Ary1D_u11p5_12: category=ARRAY, sw-calibration-access=READ-ONLY, type-emitter=RTE
      element Element: array-size=12, array-size-semantics=FIXED-SIZE, implementation-data-type=u11p5
    u15p1: implementation-data-type=uint16, type-emitter=RTE
    Ary1D_u15p1_12: category=ARRAY, sw-calibration-access=READ-ONLY, type-emitter=RTE
      element Element: array-size=12, array-size-semantics=FIXED-SIZE, implementation-data-type=u15p1
    Ary1D_u2p14_2: category=ARRAY, sw-calibration-access=READ-ONLY, type-emitter=RTE
      element Element: array-size=2, array-size-semantics=FIXED-SIZE, implementation-data-type=u2p14
    FilNotchGainRec1: category=STRUCTURE, sw-calibration-access=READ-ONLY
      5 x element, all with category=TYPE_REFERENCE, sw-calibration-access=READ-ONLY, implementation-data-type=float32:
        FilGainB{0..2}
        FilGainA1
        FilGainA2
    Ary2D_u2p14_6_5: category=ARRAY, sw-calibration-access=READ-ONLY, type-emitter=RTE
      element Element: array-size=6, array-size-semantics=FIXED-SIZE, implementation-data-type=Ary1D_u2p14_5
    Ary1D_u2p14_5: category=ARRAY, sw-calibration-access=READ-ONLY, type-emitter=RTE
      element Element: array-size=5, array-size-semantics=FIXED-SIZE, implementation-data-type=u2p14
    Ary2D_u8p8_6_5: category=ARRAY, sw-calibration-access=READ-ONLY, type-emitter=RTE
      element Element: array-size=6, array-size-semantics=FIXED-SIZE, implementation-data-type=Ary1D_u8p8_5
    Ary1D_u8p8_5: category=ARRAY, sw-calibration-access=READ-ONLY, type-emitter=RTE
      element Element: array-size=5, array-size-semantics=FIXED-SIZE, implementation-data-type=u8p8
    Ary1D_u10p6_4: category=ARRAY, sw-calibration-access=READ-ONLY, type-emitter=RTE
      element Element: array-size=4, array-size-semantics=FIXED-SIZE, implementation-data-type=u10p6
    Ary1D_u11p5_4: category=ARRAY, sw-calibration-access=READ-ONLY, type-emitter=RTE
      element Element: array-size=4, array-size-semantics=FIXED-SIZE, implementation-data-type=u11p5
    Ary1D_u4p12_11: category=ARRAY, sw-calibration-access=READ-ONLY, type-emitter=RTE
      element Element: array-size=11, array-size-semantics=FIXED-SIZE, implementation-data-type=u4p12
    Ary1D_u1p15_11: category=ARRAY, sw-calibration-access=READ-ONLY, type-emitter=RTE
      element Element: array-size=11, array-size-semantics=FIXED-SIZE, implementation-data-type=u1p15
    Ary1D_f32_8: category=ARRAY, sw-calibration-access=READ-ONLY, type-emitter=RTE
      element Element: array-size=8, array-size-semantics=FIXED-SIZE, implementation-data-type=float32
    u3p13: implementation-data-type=uint16, type-emitter=RTE
    Ary1D_u3p13_10: category=ARRAY, sw-calibration-access=READ-ONLY, type-emitter=RTE
      element Element: array-size=10, array-size-semantics=FIXED-SIZE, implementation-data-type=u3p13
    Ary1D_u9p7_16: category=ARRAY, sw-calibration-access=READ-ONLY, type-emitter=RTE
      element Element: array-size=16, array-size-semantics=FIXED-SIZE, implementation-data-type=u9p7
    Ary1D_u2p14_16: category=ARRAY, sw-calibration-access=READ-ONLY, type-emitter=RTE
      element Element: array-size=16, array-size-semantics=FIXED-SIZE, implementation-data-type=u2p14
    Ary1D_u9p7_7: category=ARRAY, sw-calibration-access=READ-ONLY, type-emitter=RTE
      element Element: array-size=7, array-size-semantics=FIXED-SIZE, implementation-data-type=u9p7
    Ary2D_u2p14_6_7: category=ARRAY, sw-calibration-access=READ-ONLY, type-emitter=RTE
      element Element: array-size=6, array-size-semantics=FIXED-SIZE, implementation-data-type=Ary1D_u2p14_7
    Ary1D_u2p14_7: category=ARRAY, sw-calibration-access=READ-ONLY, type-emitter=RTE
      element Element: array-size=7, array-size-semantics=FIXED-SIZE, implementation-data-type=u2p14
    s18p13: implementation-data-type=sint32, type-emitter=RTE
    u16p0: implementation-data-type=uint16, type-emitter=RTE
    Ary2D_f32_5_5: category=ARRAY, sw-calibration-access=READ-ONLY, type-emitter=RTE
      element Element: array-size=5, array-size-semantics=FIXED-SIZE, implementation-data-type=Ary1D_f32_5
    Ary1D_f32_5: category=ARRAY, sw-calibration-access=READ-ONLY, type-emitter=RTE
      element Element: array-size=5, array-size-semantics=FIXED-SIZE, implementation-data-type=float32
    Ary2D_f32_5_4: category=ARRAY, sw-calibration-access=READ-ONLY, type-emitter=RTE
      element Element: array-size=5, array-size-semantics=FIXED-SIZE, implementation-data-type=Ary1D_f32_4
    Ary1D_u2p14_4: category=ARRAY, sw-calibration-access=READ-ONLY, type-emitter=RTE
      element Element: array-size=4, array-size-semantics=FIXED-SIZE, implementation-data-type=u2p14
    Ary1D_u4p12_8: category=ARRAY, sw-calibration-access=READ-ONLY, type-emitter=RTE
      element Element: array-size=8, array-size-semantics=FIXED-SIZE, implementation-data-type=u4p12
    Ary2D_u1p15_8_4: category=ARRAY, sw-calibration-access=READ-ONLY, type-emitter=RTE
      element Element: array-size=8, array-size-semantics=FIXED-SIZE, implementation-data-type=Ary1D_u1p15_4
    Ary1D_u1p15_4: category=ARRAY, sw-calibration-access=READ-ONLY, type-emitter=RTE
      element Element: array-size=4, array-size-semantics=FIXED-SIZE, implementation-data-type=u1p15
    Ary1D_u10p6_5: category=ARRAY, sw-calibration-access=READ-ONLY, type-emitter=RTE
      element Element: array-size=5, array-size-semantics=FIXED-SIZE, implementation-data-type=u10p6
    Ary1D_u1p15_5: category=ARRAY, sw-calibration-access=READ-ONLY, type-emitter=RTE
      element Element: array-size=5, array-size-semantics=FIXED-SIZE, implementation-data-type=u1p15
    s11p4: implementation-data-type=sint16, type-emitter=RTE
    Ary1D_s11p4_14: category=ARRAY, sw-calibration-access=READ-ONLY, type-emitter=RTE
      element Element: array-size=14, array-size-semantics=FIXED-SIZE, implementation-data-type=s11p4
    Ary1D_u5p11_14: category=ARRAY, sw-calibration-access=READ-ONLY, type-emitter=RTE
      element Element: array-size=14, array-size-semantics=FIXED-SIZE, implementation-data-type=u5p11
    Ary1D_u11p5_6: category=ARRAY, sw-calibration-access=READ-ONLY, type-emitter=RTE
      element Element: array-size=6, array-size-semantics=FIXED-SIZE, implementation-data-type=u11p5
    Ary1D_u4p12_6: category=ARRAY, sw-calibration-access=READ-ONLY, type-emitter=RTE
      element Element: array-size=6, array-size-semantics=FIXED-SIZE, implementation-data-type=u4p12
    Ary1D_u5p11_10: category=ARRAY, sw-calibration-access=READ-ONLY, type-emitter=RTE
      element Element: array-size=10, array-size-semantics=FIXED-SIZE, implementation-data-type=u5p11
    Ary1D_u9p7_5: category=ARRAY, sw-calibration-access=READ-ONLY, type-emitter=RTE
      element Element: array-size=5, array-size-semantics=FIXED-SIZE, implementation-data-type=u9p7
    Ary1D_u5p11_5: category=ARRAY, sw-calibration-access=READ-ONLY, type-emitter=RTE
      element Element: array-size=5, array-size-semantics=FIXED-SIZE, implementation-data-type=u5p11
    s15p0: implementation-data-type=sint16, type-emitter=RTE
    Ary1D_s15p0_4: category=ARRAY, sw-calibration-access=READ-ONLY, type-emitter=RTE
      element Element: array-size=4, array-size-semantics=FIXED-SIZE, implementation-data-type=s15p0
    Ary2D_u9p7_2_5: category=ARRAY, sw-calibration-access=READ-ONLY, type-emitter=RTE
      element Element: array-size=2, array-size-semantics=FIXED-SIZE, implementation-data-type=Ary1D_u9p7_5
    Ary1D_u3p13_5: category=ARRAY, sw-calibration-access=READ-ONLY, type-emitter=RTE
      element Element: array-size=5, array-size-semantics=FIXED-SIZE, implementation-data-type=u3p13
    Ary1D_s15p0_5: category=ARRAY, sw-calibration-access=READ-ONLY, type-emitter=RTE
      element Element: array-size=5, array-size-semantics=FIXED-SIZE, implementation-data-type=s15p0
    Ary2D_u16p0_2_8: category=ARRAY, sw-calibration-access=READ-ONLY, type-emitter=RTE
      element Element: array-size=2, array-size-semantics=FIXED-SIZE, implementation-data-type=Ary1D_u16p0_8
    Ary1D_u16p0_8: category=ARRAY, sw-calibration-access=READ-ONLY, type-emitter=RTE
      element Element: array-size=8, array-size-semantics=FIXED-SIZE, implementation-data-type=u16p0
    Ary2D_u9p7_2_8: category=ARRAY, sw-calibration-access=READ-ONLY, type-emitter=RTE
      element Element: array-size=2, array-size-semantics=FIXED-SIZE, implementation-data-type=Ary1D_u9p7_8
    Ary1D_u9p7_8: category=ARRAY, sw-calibration-access=READ-ONLY, type-emitter=RTE
      element Element: array-size=8, array-size-semantics=FIXED-SIZE, implementation-data-type=u9p7
    Ary1D_u08_6: category=ARRAY, sw-calibration-access=READ-ONLY, type-emitter=RTE
      element Element: array-size=6, array-size-semantics=FIXED-SIZE, implementation-data-type=uint8
    Ary1D_u08_48: category=ARRAY, sw-calibration-access=READ-ONLY, type-emitter=RTE
      element Element: array-size=48, array-size-semantics=FIXED-SIZE, implementation-data-type=uint8
    u0p16: implementation-data-type=uint16, type-emitter=RTE
    Ary1D_u16_512: category=ARRAY, sw-calibration-access=READ-ONLY, type-emitter=RTE
      element Element: array-size=512, array-size-semantics=FIXED-SIZE, implementation-data-type=uint16
    Ary1D_u6p10_6: category=ARRAY, sw-calibration-access=READ-ONLY, type-emitter=RTE
      element Element: array-size=6, array-size-semantics=FIXED-SIZE, implementation-data-type=u6p10
    Ary2D_u3p13_12_13: category=ARRAY, sw-calibration-access=READ-ONLY, type-emitter=RTE
      element Element: array-size=12, array-size-semantics=FIXED-SIZE, implementation-data-type=Ary1D_u3p13_13
    Ary1D_u3p13_13: category=ARRAY, sw-calibration-access=READ-ONLY, type-emitter=RTE
      element Element: array-size=13, array-size-semantics=FIXED-SIZE, implementation-data-type=u3p13
    u7p9: implementation-data-type=uint16, type-emitter=RTE
    Ary1D_u7p9_12: category=ARRAY, sw-calibration-access=READ-ONLY, type-emitter=RTE
      element Element: array-size=12, array-size-semantics=FIXED-SIZE, implementation-data-type=u7p9
    Ary2D_u5p11_12_13: category=ARRAY, sw-calibration-access=READ-ONLY, type-emitter=RTE
      element Element: array-size=12, array-size-semantics=FIXED-SIZE, implementation-data-type=Ary1D_u5p11_13
    Ary1D_u5p11_13: category=ARRAY, sw-calibration-access=READ-ONLY, type-emitter=RTE
      element Element: array-size=13, array-size-semantics=FIXED-SIZE, implementation-data-type=u5p11
    Ary2D_u4p12_12_5: category=ARRAY, sw-calibration-access=READ-ONLY, type-emitter=RTE
      element Element: array-size=12, array-size-semantics=FIXED-SIZE, implementation-data-type=Ary1D_u4p12_5
    Ary1D_u4p12_5: category=ARRAY, sw-calibration-access=READ-ONLY, type-emitter=RTE
      element Element: array-size=5, array-size-semantics=FIXED-SIZE, implementation-data-type=u4p12
    Ary2D_u1p15_12_5: category=ARRAY, sw-calibration-access=READ-ONLY, type-emitter=RTE
      element Element: array-size=12, array-size-semantics=FIXED-SIZE, implementation-data-type=Ary1D_u1p15_5
    Ary1D_u0p16_10: category=ARRAY, sw-calibration-access=READ-ONLY, type-emitter=RTE
      element Element: array-size=10, array-size-semantics=FIXED-SIZE, implementation-data-type=u0p16
    Ary1D_u1p15_12: category=ARRAY, sw-calibration-access=READ-ONLY, type-emitter=RTE
      element Element: array-size=12, array-size-semantics=FIXED-SIZE, implementation-data-type=u1p15
    Ary1D_u4p12_12: category=ARRAY, sw-calibration-access=READ-ONLY, type-emitter=RTE
      element Element: array-size=12, array-size-semantics=FIXED-SIZE, implementation-data-type=u4p12
    Ary1D_u2p14_6: category=ARRAY, sw-calibration-access=READ-ONLY, type-emitter=RTE
      element Element: array-size=6, array-size-semantics=FIXED-SIZE, implementation-data-type=u2p14
    Ary2D_u4p12_12_8: category=ARRAY, sw-calibration-access=READ-ONLY, type-emitter=RTE
      element Element: array-size=12, array-size-semantics=FIXED-SIZE, implementation-data-type=Ary1D_u4p12_8
    Ary1D_u8p8_8: category=ARRAY, sw-calibration-access=READ-ONLY, type-emitter=RTE
      element Element: array-size=8, array-size-semantics=FIXED-SIZE, implementation-data-type=u8p8
    Ary1D_u8p8_2: category=ARRAY, sw-calibration-access=READ-ONLY, type-emitter=RTE
      element Element: array-size=2, array-size-semantics=FIXED-SIZE, implementation-data-type=u8p8
    Ary1D_u1p15_2: category=ARRAY, sw-calibration-access=READ-ONLY, type-emitter=RTE
      element Element: array-size=2, array-size-semantics=FIXED-SIZE, implementation-data-type=u1p15
    Ary2D_u12p4_12_13: category=ARRAY, sw-calibration-access=READ-ONLY, type-emitter=RTE
      element Element: array-size=12, array-size-semantics=FIXED-SIZE, implementation-data-type=Ary1D_u12p4_13
    Ary1D_u12p4_13: category=ARRAY, sw-calibration-access=READ-ONLY, type-emitter=RTE
      element Element: array-size=13, array-size-semantics=FIXED-SIZE, implementation-data-type=u12p4
    Ary2D_u8p8_12_20: category=ARRAY, sw-calibration-access=READ-ONLY, type-emitter=RTE
      element Element: array-size=12, array-size-semantics=FIXED-SIZE, implementation-data-type=Ary1D_u8p8_20
    Ary1D_u8p8_20: category=ARRAY, sw-calibration-access=READ-ONLY, type-emitter=RTE
      element Element: array-size=20, array-size-semantics=FIXED-SIZE, implementation-data-type=u8p8
    Ary2D_s4p11_12_20: category=ARRAY, sw-calibration-access=READ-ONLY, type-emitter=RTE
      element Element: array-size=12, array-size-semantics=FIXED-SIZE, implementation-data-type=Ary1D_s4p11_20
    Ary1D_s4p11_20: category=ARRAY, sw-calibration-access=READ-ONLY, type-emitter=RTE
      element Element: array-size=20, array-size-semantics=FIXED-SIZE, implementation-data-type=s4p11
    Ary2D_u5p11_12_5: category=ARRAY, sw-calibration-access=READ-ONLY, type-emitter=RTE
      element Element: array-size=12, array-size-semantics=FIXED-SIZE, implementation-data-type=Ary1D_u5p11_5
    Ary2D_u2p14_12_5: category=ARRAY, sw-calibration-access=READ-ONLY, type-emitter=RTE
      element Element: array-size=12, array-size-semantics=FIXED-SIZE, implementation-data-type=Ary1D_u2p14_5
    Ary2D_u1p15_5_4: category=ARRAY, sw-calibration-access=READ-ONLY, type-emitter=RTE
      element Element: array-size=5, array-size-semantics=FIXED-SIZE, implementation-data-type=Ary1D_u1p15_4
    Ary1D_u12p4_2: category=ARRAY, sw-calibration-access=READ-ONLY, type-emitter=RTE
      element Element: array-size=2, array-size-semantics=FIXED-SIZE, implementation-data-type=u12p4
    Ary2D_u0p16_4_2: category=ARRAY, sw-calibration-access=READ-ONLY, type-emitter=RTE
      element Element: array-size=4, array-size-semantics=FIXED-SIZE, implementation-data-type=Ary1D_u0p16_2
    Ary1D_u0p16_2: category=ARRAY, sw-calibration-access=READ-ONLY, type-emitter=RTE
      element Element: array-size=2, array-size-semantics=FIXED-SIZE, implementation-data-type=u0p16
    Ary2D_u12p4_9_16: category=ARRAY, sw-calibration-access=READ-ONLY, type-emitter=RTE
      element Element: array-size=9, array-size-semantics=FIXED-SIZE, implementation-data-type=Ary1D_u12p4_16
    Ary1D_u12p4_16: category=ARRAY, sw-calibration-access=READ-ONLY, type-emitter=RTE
      element Element: array-size=16, array-size-semantics=FIXED-SIZE, implementation-data-type=u12p4
    Ary2D_u5p11_9_16: category=ARRAY, sw-calibration-access=READ-ONLY, type-emitter=RTE
      element Element: array-size=9, array-size-semantics=FIXED-SIZE, implementation-data-type=Ary1D_u5p11_16
    Ary1D_u5p11_16: category=ARRAY, sw-calibration-access=READ-ONLY, type-emitter=RTE
      element Element: array-size=16, array-size-semantics=FIXED-SIZE, implementation-data-type=u5p11
    Ary2D_u8p8_9_8: category=ARRAY, sw-calibration-access=READ-ONLY, type-emitter=RTE
      element Element: array-size=9, array-size-semantics=FIXED-SIZE, implementation-data-type=Ary1D_u8p8_8
    Ary2D_u7p9_9_4: category=ARRAY, sw-calibration-access=READ-ONLY, type-emitter=RTE
      element Element: array-size=9, array-size-semantics=FIXED-SIZE, implementation-data-type=Ary1D_u7p9_4
    Ary1D_u7p9_4: category=ARRAY, sw-calibration-access=READ-ONLY, type-emitter=RTE
      element Element: array-size=4, array-size-semantics=FIXED-SIZE, implementation-data-type=u7p9
    Ary2D_u8p8_9_4: category=ARRAY, sw-calibration-access=READ-ONLY, type-emitter=RTE
      element Element: array-size=9, array-size-semantics=FIXED-SIZE, implementation-data-type=Ary1D_u8p8_4
    Ary1D_u8p8_4: category=ARRAY, sw-calibration-access=READ-ONLY, type-emitter=RTE
      element Element: array-size=4, array-size-semantics=FIXED-SIZE, implementation-data-type=u8p8
    Ary1D_u9p7_9: category=ARRAY, sw-calibration-access=READ-ONLY, type-emitter=RTE
      element Element: array-size=9, array-size-semantics=FIXED-SIZE, implementation-data-type=u9p7
    Ary1D_u4p12_10: category=ARRAY, sw-calibration-access=READ-ONLY, type-emitter=RTE
      element Element: array-size=10, array-size-semantics=FIXED-SIZE, implementation-data-type=u4p12
    Ary1D_u2p14_12: category=ARRAY, sw-calibration-access=READ-ONLY, type-emitter=RTE
      element Element: array-size=12, array-size-semantics=FIXED-SIZE, implementation-data-type=u2p14
    Ary1D_u13p3_6: category=ARRAY, sw-calibration-access=READ-ONLY, type-emitter=RTE
      element Element: array-size=6, array-size-semantics=FIXED-SIZE, implementation-data-type=u13p3
    Ary1D_u4p12_2: category=ARRAY, sw-calibration-access=READ-ONLY, type-emitter=RTE
      element Element: array-size=2, array-size-semantics=FIXED-SIZE, implementation-data-type=u4p12
    s14p1: implementation-data-type=sint16, type-emitter=RTE
    Ary1D_s14p1_8: category=ARRAY, sw-calibration-access=READ-ONLY, type-emitter=RTE
      element Element: array-size=8, array-size-semantics=FIXED-SIZE, implementation-data-type=s14p1
    Ary1D_s11p4_11: category=ARRAY, sw-calibration-access=READ-ONLY, type-emitter=RTE
      element Element: array-size=11, array-size-semantics=FIXED-SIZE, implementation-data-type=s11p4
    Ary2D_s4p11_8_11: category=ARRAY, sw-calibration-access=READ-ONLY, type-emitter=RTE
      element Element: array-size=8, array-size-semantics=FIXED-SIZE, implementation-data-type=Ary1D_s4p11_11
    Ary1D_s4p11_11: category=ARRAY, sw-calibration-access=READ-ONLY, type-emitter=RTE
      element Element: array-size=11, array-size-semantics=FIXED-SIZE, implementation-data-type=s4p11
    Ary1D_s4p11_4: category=ARRAY, sw-calibration-access=READ-ONLY, type-emitter=RTE
      element Element: array-size=4, array-size-semantics=FIXED-SIZE, implementation-data-type=s4p11
    s7p8: implementation-data-type=sint16, type-emitter=RTE
    Ary2D_s7p8_4_5: category=ARRAY, sw-calibration-access=READ-ONLY, type-emitter=RTE
      element Element: array-size=4, array-size-semantics=FIXED-SIZE, implementation-data-type=Ary1D_s7p8_5
    Ary1D_s7p8_5: category=ARRAY, sw-calibration-access=READ-ONLY, type-emitter=RTE
      element Element: array-size=5, array-size-semantics=FIXED-SIZE, implementation-data-type=s7p8
    Ary2D_u12p4_5_4: category=ARRAY, sw-calibration-access=READ-ONLY, type-emitter=RTE
      element Element: array-size=5, array-size-semantics=FIXED-SIZE, implementation-data-type=Ary1D_u12p4_4
    Ary1D_u12p4_4: category=ARRAY, sw-calibration-access=READ-ONLY, type-emitter=RTE
      element Element: array-size=4, array-size-semantics=FIXED-SIZE, implementation-data-type=u12p4
    Ary2D_u12p4_4_2: category=ARRAY, sw-calibration-access=READ-ONLY, type-emitter=RTE
      element Element: array-size=4, array-size-semantics=FIXED-SIZE, implementation-data-type=Ary1D_u12p4_2
    Ary1D_u8p8_14: category=ARRAY, sw-calibration-access=READ-ONLY, type-emitter=RTE
      element Element: array-size=14, array-size-semantics=FIXED-SIZE, implementation-data-type=u8p8
    Ary2D_u3p13_20_8: category=ARRAY, sw-calibration-access=READ-ONLY, type-emitter=RTE
      element Element: array-size=20, array-size-semantics=FIXED-SIZE, implementation-data-type=Ary1D_u3p13_8
    Ary1D_u3p13_8: category=ARRAY, sw-calibration-access=READ-ONLY, type-emitter=RTE
      element Element: array-size=8, array-size-semantics=FIXED-SIZE, implementation-data-type=u3p13
    Ary2D_u0p16_20_8: category=ARRAY, sw-calibration-access=READ-ONLY, type-emitter=RTE
      element Element: array-size=20, array-size-semantics=FIXED-SIZE, implementation-data-type=Ary1D_u0p16_8
    Ary1D_u0p16_8: category=ARRAY, sw-calibration-access=READ-ONLY, type-emitter=RTE
      element Element: array-size=8, array-size-semantics=FIXED-SIZE, implementation-data-type=u0p16
    Ary1D_u5p11_8: category=ARRAY, sw-calibration-access=READ-ONLY, type-emitter=RTE
      element Element: array-size=8, array-size-semantics=FIXED-SIZE, implementation-data-type=u5p11
    s1p14: implementation-data-type=sint16, type-emitter=RTE
    Ary2D_s1p14_10_12: category=ARRAY, sw-calibration-access=READ-ONLY, type-emitter=RTE
      element Element: array-size=10, array-size-semantics=FIXED-SIZE, implementation-data-type=Ary1D_s1p14_12
    Ary1D_s1p14_12: category=ARRAY, sw-calibration-access=READ-ONLY, type-emitter=RTE
      element Element: array-size=12, array-size-semantics=FIXED-SIZE, implementation-data-type=s1p14
    Ary1D_u16p0_20: category=ARRAY, sw-calibration-access=READ-ONLY, type-emitter=RTE
      element Element: array-size=20, array-size-semantics=FIXED-SIZE, implementation-data-type=u16p0
    Ary1D_u13p3_8: category=ARRAY, sw-calibration-access=READ-ONLY, type-emitter=RTE
      element Element: array-size=8, array-size-semantics=FIXED-SIZE, implementation-data-type=u13p3
    Ary1D_u16_8: category=ARRAY, sw-calibration-access=READ-ONLY, type-emitter=RTE
      element Element: array-size=8, array-size-semantics=FIXED-SIZE, implementation-data-type=uint16
    s5p10: implementation-data-type=sint16, type-emitter=RTE
    Ary1D_s5p10_8: category=ARRAY, sw-calibration-access=READ-ONLY, type-emitter=RTE
      element Element: array-size=8, array-size-semantics=FIXED-SIZE, implementation-data-type=s5p10
    Ary1D_s16_8: category=ARRAY, sw-calibration-access=READ-ONLY, type-emitter=RTE
      element Element: array-size=8, array-size-semantics=FIXED-SIZE, implementation-data-type=sint16
    Ary1D_u16_6: category=ARRAY, sw-calibration-access=READ-ONLY, type-emitter=RTE
      element Element: array-size=6, array-size-semantics=FIXED-SIZE, implementation-data-type=uint16
    Ary2D_s16_8_9: category=ARRAY, sw-calibration-access=READ-ONLY, type-emitter=RTE
      element Element: array-size=8, array-size-semantics=FIXED-SIZE, implementation-data-type=Ary1D_s16_9
    Ary1D_s16_9: category=ARRAY, sw-calibration-access=READ-ONLY, type-emitter=RTE
      element Element: array-size=9, array-size-semantics=FIXED-SIZE, implementation-data-type=sint16
    Ary1D_logl_13: category=ARRAY, sw-calibration-access=READ-ONLY, type-emitter=RTE
      element Element: array-size=13, array-size-semantics=FIXED-SIZE, implementation-data-type=boolean
    Ary1D_u16p0_2: category=ARRAY, sw-calibration-access=READ-ONLY, type-emitter=RTE
      element Element: array-size=2, array-size-semantics=FIXED-SIZE, implementation-data-type=u16p0
    Ary1D_s11p4_5: category=ARRAY, sw-calibration-access=READ-ONLY, type-emitter=RTE
      element Element: array-size=5, array-size-semantics=FIXED-SIZE, implementation-data-type=s11p4
